VERSION "dbc-export 1 2025.20.8"

NS_ :

BS_:

BU_: ADSP APSB BB BMS CMP CP DAS DI DIF DIR DPB EPASTP EPASTS GTW ICR IDB OCS1P PM PMF PMR PTC RCM RCU TCU UI UIS VCLEFT VCSEC

BO_ 1360 ADSP_alertLog: 8 ADSP
 SG_ ADSP_alertID M : 0|7@1+ (1,0) [0|127] "" Vector__XXX
 SG_ ADSP_alertState : 15|1@1+ (1,0) [0|1] "" Vector__XXX
 SG_ ADSP_a035_a2baFaultNode m35 : 16|4@1+ (1,0) [0|15] "" Vector__XXX
 SG_ ADSP_a035_timeout m35 : 20|1@1+ (1,0) [0|1] "" Vector__XXX
 SG_ ADSP_a035_a2baIntrType m35 : 24|8@1+ (1,0) [0|255] "" Vector__XXX
 SG_ ADSP_a035_a2baFaultType m35 : 32|6@1+ (1,0) [0|63] "" Vector__XXX
 SG_ ADSP_a036_a2bbFaultNode m36 : 16|4@1+ (1,0) [0|15] "" Vector__XXX
 SG_ ADSP_a036_timeout m36 : 20|1@1+ (1,0) [0|1] "" Vector__XXX
 SG_ ADSP_a036_a2bbIntrType m36 : 24|8@1+ (1,0) [0|255] "" Vector__XXX
 SG_ ADSP_a036_a2bbFaultType m36 : 32|6@1+ (1,0) [0|63] "" Vector__XXX
 SG_ ADSP_a050_open_load m50 : 16|1@1+ (1,0) [0|1] "" Vector__XXX
 SG_ ADSP_a050_short_vcc m50 : 17|1@1+ (1,0) [0|1] "" Vector__XXX
 SG_ ADSP_a050_short_gnd m50 : 18|1@1+ (1,0) [0|1] "" Vector__XXX
 SG_ ADSP_a050_short_load m50 : 19|1@1+ (1,0) [0|1] "" Vector__XXX
 SG_ ADSP_a050_diag_failed_to_start m50 : 20|1@1+ (1,0) [0|1] "" Vector__XXX
 SG_ ADSP_a050_diag_failed m50 : 21|1@1+ (1,0) [0|1] "" Vector__XXX
 SG_ ADSP_a053_audioSystemUnavailable m53 : 16|3@1+ (1,0) [0|7] "" Vector__XXX
 SG_ ADSP_a066_open_load m66 : 16|1@1+ (1,0) [0|1] "" Vector__XXX
 SG_ ADSP_a066_short_vcc m66 : 17|1@1+ (1,0) [0|1] "" Vector__XXX
 SG_ ADSP_a066_short_gnd m66 : 18|1@1+ (1,0) [0|1] "" Vector__XXX
 SG_ ADSP_a066_short_load m66 : 19|1@1+ (1,0) [0|1] "" Vector__XXX
 SG_ ADSP_a066_diag_failed_to_start m66 : 20|1@1+ (1,0) [0|1] "" Vector__XXX
 SG_ ADSP_a066_diag_failed m66 : 21|1@1+ (1,0) [0|1] "" Vector__XXX
 SG_ ADSP_a067_baseamp0Fault m67 : 16|3@1+ (1,0) [0|7] "" Vector__XXX
 SG_ ADSP_a068_baseamp1Fault m68 : 16|3@1+ (1,0) [0|7] "" Vector__XXX
 SG_ ADSP_a069_baseamp2Fault m69 : 16|3@1+ (1,0) [0|7] "" Vector__XXX
 SG_ ADSP_a070_baseamp3Fault m70 : 16|3@1+ (1,0) [0|7] "" Vector__XXX
 SG_ ADSP_a071_versionMismatch m71 : 16|1@1+ (1,0) [0|1] "" Vector__XXX

BO_ 1361 ADSP_alertMatrix1: 8 ADSP
 SG_ ADSP_w001_flashInit : 0|1@1+ (1,0) [0|1] "" Vector__XXX
 SG_ ADSP_w002_exception : 1|1@1+ (1,0) [0|1] "" Vector__XXX
 SG_ ADSP_w003_assert : 2|1@1+ (1,0) [0|1] "" Vector__XXX
 SG_ ADSP_w004_malloc : 3|1@1+ (1,0) [0|1] "" Vector__XXX
 SG_ ADSP_w005_stackOverflow : 4|1@1+ (1,0) [0|1] "" Vector__XXX
 SG_ ADSP_w006_eavbSeqno : 5|1@1+ (1,0) [0|1] "" Vector__XXX
 SG_ ADSP_w007_ethLinkErr : 6|1@1+ (1,0) [0|1] "" Vector__XXX
 SG_ ADSP_w008_internalTempHigh : 7|1@1+ (1,0) [0|1] "" Vector__XXX
 SG_ ADSP_w010_12vAudioFiltLow : 9|1@1+ (1,0) [0|1] "" Vector__XXX
 SG_ ADSP_w011_armHighCpuUsage : 10|1@1+ (1,0) [0|1] "" Vector__XXX
 SG_ ADSP_w012_sharc0HighCpuUsage : 11|1@1+ (1,0) [0|1] "" Vector__XXX
 SG_ ADSP_w013_sharc1HighCpuUsage : 12|1@1+ (1,0) [0|1] "" Vector__XXX
 SG_ ADSP_w014_eavbOverrun : 13|1@1+ (1,0) [0|1] "" Vector__XXX
 SG_ ADSP_w015_eavbUnderrun : 14|1@1+ (1,0) [0|1] "" Vector__XXX
 SG_ ADSP_w016_usbRxOverrun : 15|1@1+ (1,0) [0|1] "" Vector__XXX
 SG_ ADSP_w017_usbRxUnderrun : 16|1@1+ (1,0) [0|1] "" Vector__XXX
 SG_ ADSP_w018_usbTxOverrun : 17|1@1+ (1,0) [0|1] "" Vector__XXX
 SG_ ADSP_w019_usbTxUnderrun : 18|1@1+ (1,0) [0|1] "" Vector__XXX
 SG_ ADSP_w020_usbTxFailed : 19|1@1+ (1,0) [0|1] "" Vector__XXX
 SG_ ADSP_w021_usbTxAborted : 20|1@1+ (1,0) [0|1] "" Vector__XXX
 SG_ ADSP_w022_emacErr : 21|1@1+ (1,0) [0|1] "" Vector__XXX
 SG_ ADSP_w023_ethEtharpErr : 22|1@1+ (1,0) [0|1] "" Vector__XXX
 SG_ ADSP_w024_ethIpfragErr : 23|1@1+ (1,0) [0|1] "" Vector__XXX
 SG_ ADSP_w025_ethIpErr : 24|1@1+ (1,0) [0|1] "" Vector__XXX
 SG_ ADSP_w026_ethIcmpErr : 25|1@1+ (1,0) [0|1] "" Vector__XXX
 SG_ ADSP_w027_ethUdpErr : 26|1@1+ (1,0) [0|1] "" Vector__XXX
 SG_ ADSP_w028_ethTcpErr : 27|1@1+ (1,0) [0|1] "" Vector__XXX
 SG_ ADSP_w029_baseamp0SmFault : 28|1@1+ (1,0) [0|1] "" Vector__XXX
 SG_ ADSP_w030_ethSysErr : 29|1@1+ (1,0) [0|1] "" Vector__XXX
 SG_ ADSP_w031_baseamp1SmFault : 30|1@1+ (1,0) [0|1] "" Vector__XXX
 SG_ ADSP_w032_baseamp2SmFault : 31|1@1+ (1,0) [0|1] "" Vector__XXX
 SG_ ADSP_w033_a2baDiscoveryFailed : 32|1@1+ (1,0) [0|1] "" Vector__XXX
 SG_ ADSP_w034_a2bbDiscoveryFailed : 33|1@1+ (1,0) [0|1] "" Vector__XXX
 SG_ ADSP_w035_a2baFault : 34|1@1+ (1,0) [0|1] "" Vector__XXX
 SG_ ADSP_w036_a2bbFault : 35|1@1+ (1,0) [0|1] "" Vector__XXX
 SG_ ADSP_w037_a2baIdleFailed : 36|1@1+ (1,0) [0|1] "" Vector__XXX
 SG_ ADSP_w038_a2bbIdleFailed : 37|1@1+ (1,0) [0|1] "" Vector__XXX
 SG_ ADSP_w039_ancPing : 38|1@1+ (1,0) [0|1] "" Vector__XXX
 SG_ ADSP_w040_socSciHeartbeat : 39|1@1+ (1,0) [0|1] "" Vector__XXX
 SG_ ADSP_w041_twiWriteError : 40|1@1+ (1,0) [0|1] "" Vector__XXX
 SG_ ADSP_w042_twiReadError : 41|1@1+ (1,0) [0|1] "" Vector__XXX
 SG_ ADSP_w043_aweControlError : 42|1@1+ (1,0) [0|1] "" Vector__XXX
 SG_ ADSP_w044_canethChecksum : 43|1@1+ (1,0) [0|1] "" Vector__XXX
 SG_ ADSP_w045_ancEnableFail : 44|1@1+ (1,0) [0|1] "" Vector__XXX
 SG_ ADSP_w046_sharc0AweFrameOverload : 45|1@1+ (1,0) [0|1] "" Vector__XXX
 SG_ ADSP_w047_sharc1AweFrameOverload : 46|1@1+ (1,0) [0|1] "" Vector__XXX
 SG_ ADSP_w048_eCallSelfTestFailed : 47|1@1+ (1,0) [0|1] "" Vector__XXX
 SG_ ADSP_w049_sae : 48|1@1+ (1,0) [0|1] "" Vector__XXX
 SG_ ADSP_w050_extSpkFault : 49|1@1+ (1,0) [0|1] "" Vector__XXX
 SG_ ADSP_w051_extspkFailure : 50|1@1+ (1,0) [0|1] "" Vector__XXX
 SG_ ADSP_w052_criticalReset : 51|1@1+ (1,0) [0|1] "" Vector__XXX
 SG_ ADSP_w053_audioSystemUnavailable : 52|1@1+ (1,0) [0|1] "" Vector__XXX
 SG_ ADSP_w054_canethRxError : 53|1@1+ (1,0) [0|1] "" Vector__XXX
 SG_ ADSP_w055_hfpMathExcept1NAN : 54|1@1+ (1,0) [0|1] "" Vector__XXX
 SG_ ADSP_w056_hfpMathExcept1INF : 55|1@1+ (1,0) [0|1] "" Vector__XXX
 SG_ ADSP_w057_hfpMathExcept2NAN : 56|1@1+ (1,0) [0|1] "" Vector__XXX
 SG_ ADSP_w058_hfpMathExcept2INF : 57|1@1+ (1,0) [0|1] "" Vector__XXX
 SG_ ADSP_w059_nvmmError : 58|1@1+ (1,0) [0|1] "" Vector__XXX
 SG_ ADSP_w060_baseamp3SmFault : 59|1@1+ (1,0) [0|1] "" Vector__XXX
 SG_ ADSP_w061_tcuGpioServiceError : 60|1@1+ (1,0) [0|1] "" Vector__XXX

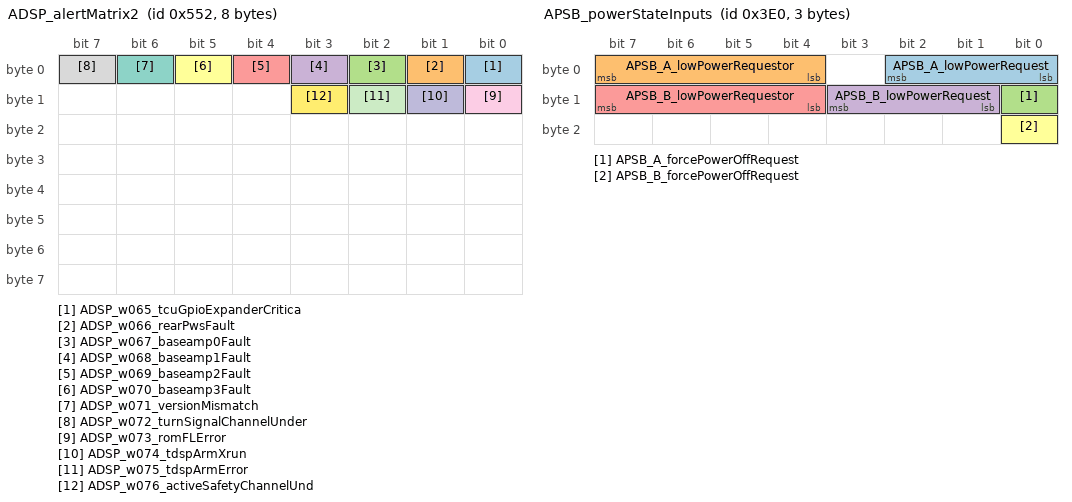
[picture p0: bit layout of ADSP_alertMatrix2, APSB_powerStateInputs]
BO_ 1362 ADSP_alertMatrix2: 8 ADSP
 SG_ ADSP_w065_tcuGpioExpanderCritica : 0|1@1+ (1,0) [0|1] "" Vector__XXX
 SG_ ADSP_w066_rearPwsFault : 1|1@1+ (1,0) [0|1] "" Vector__XXX
 SG_ ADSP_w067_baseamp0Fault : 2|1@1+ (1,0) [0|1] "" Vector__XXX
 SG_ ADSP_w068_baseamp1Fault : 3|1@1+ (1,0) [0|1] "" Vector__XXX
 SG_ ADSP_w069_baseamp2Fault : 4|1@1+ (1,0) [0|1] "" Vector__XXX
 SG_ ADSP_w070_baseamp3Fault : 5|1@1+ (1,0) [0|1] "" Vector__XXX
 SG_ ADSP_w071_versionMismatch : 6|1@1+ (1,0) [0|1] "" Vector__XXX
 SG_ ADSP_w072_turnSignalChannelUnder : 7|1@1+ (1,0) [0|1] "" Vector__XXX
 SG_ ADSP_w073_romFLError : 8|1@1+ (1,0) [0|1] "" Vector__XXX
 SG_ ADSP_w074_tdspArmXrun : 9|1@1+ (1,0) [0|1] "" Vector__XXX
 SG_ ADSP_w075_tdspArmError : 10|1@1+ (1,0) [0|1] "" Vector__XXX
 SG_ ADSP_w076_activeSafetyChannelUnd : 11|1@1+ (1,0) [0|1] "" Vector__XXX

BO_ 992 APSB_powerStateInputs: 3 APSB
 SG_ APSB_A_lowPowerRequest : 0|3@1+ (1,0) [0|7] "" Vector__XXX
 SG_ APSB_A_lowPowerRequestor : 4|4@1+ (1,0) [0|15] "" Vector__XXX
 SG_ APSB_A_forcePowerOffRequest : 8|1@1+ (1,0) [0|1] "" Vector__XXX
 SG_ APSB_B_lowPowerRequest : 9|3@1+ (1,0) [0|7] "" Vector__XXX
 SG_ APSB_B_lowPowerRequestor : 12|4@1+ (1,0) [0|15] "" Vector__XXX
 SG_ APSB_B_forcePowerOffRequest : 16|1@1+ (1,0) [0|1] "" Vector__XXX

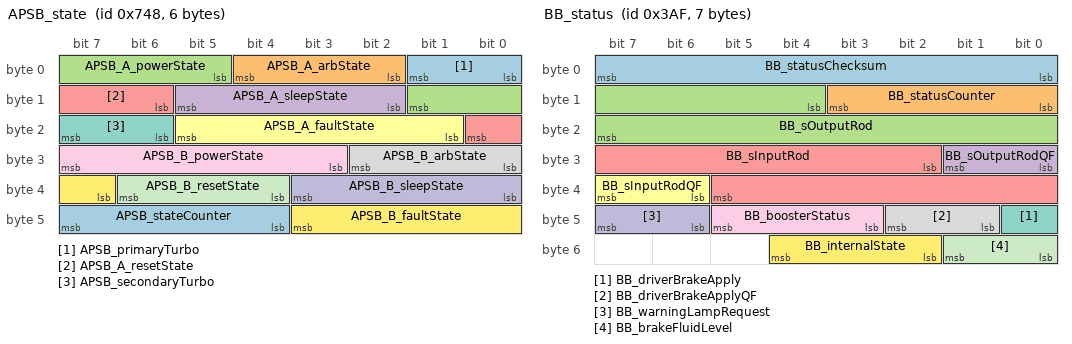
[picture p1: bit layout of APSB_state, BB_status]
BO_ 1864 APSB_state: 6 APSB
 SG_ APSB_primaryTurbo : 0|2@1+ (1,0) [0|3] "" Vector__XXX
 SG_ APSB_A_arbState : 2|3@1+ (1,0) [0|7] "" Vector__XXX
 SG_ APSB_A_powerState : 5|5@1+ (1,0) [0|31] "" Vector__XXX
 SG_ APSB_A_sleepState : 10|4@1+ (1,0) [0|15] "" Vector__XXX
 SG_ APSB_A_resetState : 14|3@1+ (1,0) [0|7] "" Vector__XXX
 SG_ APSB_A_faultState : 17|5@1+ (1,0) [0|31] "" Vector__XXX
 SG_ APSB_secondaryTurbo : 22|2@1+ (1,0) [0|3] "" Vector__XXX
 SG_ APSB_B_arbState : 24|3@1+ (1,0) [0|7] "" Vector__XXX
 SG_ APSB_B_powerState : 27|5@1+ (1,0) [0|31] "" Vector__XXX
 SG_ APSB_B_sleepState : 32|4@1+ (1,0) [0|15] "" Vector__XXX
 SG_ APSB_B_resetState : 36|3@1+ (1,0) [0|7] "" Vector__XXX
 SG_ APSB_B_faultState : 39|5@1+ (1,0) [0|31] "" Vector__XXX
 SG_ APSB_stateCounter : 44|4@1+ (1,0) [0|15] "" Vector__XXX

BO_ 971 APSB_status: 8 APSB
 SG_ APSB_appStatusMonitorState : 0|3@1+ (1,0) [0|7] "" Vector__XXX
 SG_ APSB_vehBehaviorState : 4|4@1+ (1,0) [0|15] "" Vector__XXX
 SG_ APSB_canMaster : 8|2@1+ (1,0) [0|2] "" Vector__XXX
 SG_ APSB_appGpioState : 10|2@1+ (1,0) [0|3] "" Vector__XXX
 SG_ APSB_eacInternalState : 12|3@1+ (1,0) [0|7] "" Vector__XXX
 SG_ APSB_switchState : 15|1@1+ (1,0) [0|1] "" Vector__XXX
 SG_ APSB_apbStatusMonitorState : 16|3@1+ (1,0) [0|7] "" Vector__XXX
 SG_ APSB_apbGpioState : 20|2@1+ (1,0) [0|3] "" Vector__XXX
 SG_ APSB_statusCounter : 22|4@1+ (1,0) [0|15] "" Vector__XXX
 SG_ APSB_locLimitReason : 26|3@1+ (1,0) [0|7] "" Vector__XXX
 SG_ APSB_appPowerStateRequest : 29|2@1+ (1,0) [0|3] "" Vector__XXX
 SG_ APSB_appPowerStateReason : 31|4@1+ (1,0) [0|15] "" Vector__XXX
 SG_ APSB_apbPowerStateRequest : 36|2@1+ (1,0) [0|3] "" Vector__XXX
 SG_ APSB_apbPowerStateReason : 38|4@1+ (1,0) [0|15] "" Vector__XXX
 SG_ APSB_heaterStateDebug : 43|3@1+ (1,0) [0|6] "" Vector__XXX
 SG_ APSB_autosummonCounter : 46|3@1+ (1,0) [0|7] "" Vector__XXX
 SG_ APSB_autosummonAlert : 49|1@1+ (1,0) [0|1] "" Vector__XXX
 SG_ APSB_gpsAntennaState : 50|2@1+ (1,0) [0|3] "" Vector__XXX
 SG_ APSB_arbState : 52|3@1+ (1,0) [0|7] "" Vector__XXX
 SG_ APSB_socPowerOperatingMode : 55|2@1+ (1,0) [0|3] "" Vector__XXX

BO_ 943 BB_status: 7 BB
 SG_ BB_statusChecksum : 0|8@1+ (1,0) [0|255] "" Vector__XXX
 SG_ BB_statusCounter : 8|4@1+ (1,0) [0|15] "" Vector__XXX
 SG_ BB_sOutputRod : 12|12@1+ (0.015625,-5) [-5|47] "mm" Vector__XXX
 SG_ BB_sOutputRodQF : 24|2@1+ (1,0) [0|3] "" Vector__XXX
 SG_ BB_sInputRod : 26|12@1+ (0.015625,-5) [-5|47] "mm" Vector__XXX
 SG_ BB_sInputRodQF : 38|2@1+ (1,0) [0|3] "" Vector__XXX
 SG_ BB_driverBrakeApply : 40|1@1+ (1,0) [0|1] "" Vector__XXX
 SG_ BB_driverBrakeApplyQF : 41|2@1+ (1,0) [0|3] "" Vector__XXX
 SG_ BB_boosterStatus : 43|3@1+ (1,0) [0|7] "" Vector__XXX
 SG_ BB_warningLampRequest : 46|2@1+ (1,0) [0|3] "" Vector__XXX
 SG_ BB_brakeFluidLevel : 48|2@1+ (1,0) [0|3] "" Vector__XXX
 SG_ BB_internalState : 50|3@1+ (1,0) [0|7] "" Vector__XXX

BO_ 2029 BMS_debugInfo_10Hz: 8 BMS
 SG_ BMS_10HzDebug_Id M : 0|6@1+ (1,0) [0|63] "" Vector__XXX
 SG_ BMS_activeCoolCellTargetT m33 : 6|9@1+ (0.25,-25) [-25|100] "DegC" Vector__XXX
 SG_ BMS_passiveCoolCellTargetT m33 : 15|9@1+ (0.25,-25) [-25|100] "DegC" Vector__XXX

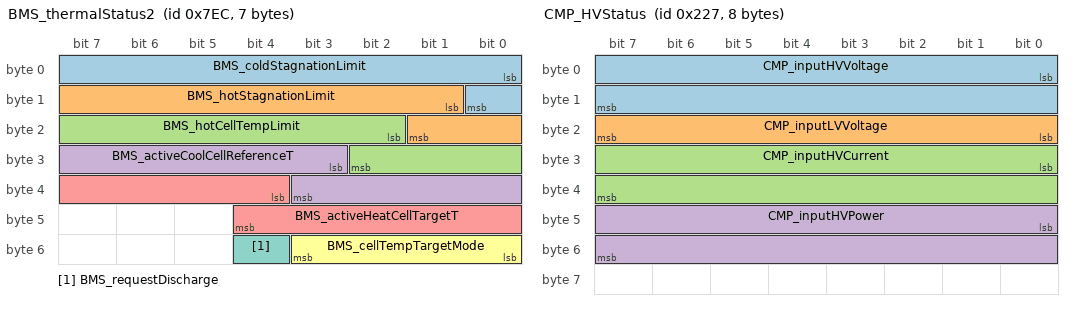
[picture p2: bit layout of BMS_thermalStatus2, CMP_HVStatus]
BO_ 2028 BMS_thermalStatus2: 7 BMS
 SG_ BMS_coldStagnationLimit : 0|9@1+ (0.25,-25) [-25|100] "DegC" Vector__XXX
 SG_ BMS_hotStagnationLimit : 9|9@1+ (0.25,-25) [-25|100] "DegC" Vector__XXX
 SG_ BMS_hotCellTempLimit : 18|9@1+ (0.25,-25) [-25|100] "DegC" Vector__XXX
 SG_ BMS_activeCoolCellReferenceT : 27|9@1+ (0.25,-25) [-25|100] "DegC" Vector__XXX
 SG_ BMS_activeHeatCellTargetT : 36|9@1+ (0.25,-25) [-25|100] "DegC" Vector__XXX
 SG_ BMS_cellTempTargetMode : 48|4@1+ (1,0) [0|15] "" Vector__XXX
 SG_ BMS_requestDischarge : 52|1@1+ (1,0) [0|1] "" Vector__XXX

BO_ 551 CMP_HVStatus: 8 CMP
 SG_ CMP_inputHVVoltage : 0|16@1+ (0.1,0) [0|6553.4] "V" Vector__XXX
 SG_ CMP_inputLVVoltage : 16|8@1+ (0.1,0) [0|25.5] "V" Vector__XXX
 SG_ CMP_inputHVCurrent : 24|16@1+ (0.1,0) [0|6553.4] "A" Vector__XXX
 SG_ CMP_inputHVPower : 40|16@1+ (1,0) [0|65534] "W" Vector__XXX

BO_ 1767 CP_IsoTpPipeToPncd: 8 CP
 SG_ CP_isoTpToPncdData : 0|64@1+ (1,0) [0|1.84467440737e+19] "" Vector__XXX

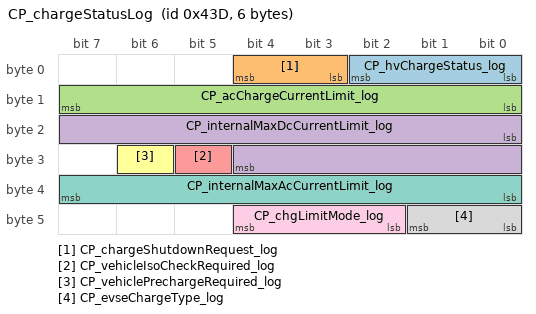
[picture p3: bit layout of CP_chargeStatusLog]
BO_ 1085 CP_chargeStatusLog: 6 CP
 SG_ CP_hvChargeStatus_log : 0|3@1+ (1,0) [0|7] "" Vector__XXX
 SG_ CP_chargeShutdownRequest_log : 3|2@1+ (1,0) [0|3] "" Vector__XXX
 SG_ CP_acChargeCurrentLimit_log : 8|8@1+ (0.5,0) [0|127.5] "A" Vector__XXX
 SG_ CP_internalMaxDcCurrentLimit_log : 16|13@1+ (0.25,0) [0|2047.75] "A" Vector__XXX
 SG_ CP_vehicleIsoCheckRequired_log : 29|1@1+ (1,0) [0|1] "" Vector__XXX
 SG_ CP_vehiclePrechargeRequired_log : 30|1@1+ (1,0) [0|1] "" Vector__XXX
 SG_ CP_internalMaxAcCurrentLimit_log : 32|8@1+ (0.5,0) [0|127.5] "A" Vector__XXX
 SG_ CP_evseChargeType_log : 40|2@1+ (1,0) [0|3] "" Vector__XXX
 SG_ CP_chgLimitMode_log : 42|3@1+ (1,0) [0|7] "" Vector__XXX

BO_ 777 DAS_object: 8 DAS
 SG_ DAS_objectId M : 0|3@1+ (1,0) [0|7] "" Vector__XXX
 SG_ DAS_leadVehType m0 : 3|3@1+ (1,0) [0|7] "" Vector__XXX
 SG_ DAS_leadVehRelevantForControl m0 : 7|1@1+ (1,0) [0|1] "" Vector__XXX
 SG_ DAS_leadVehDx m0 : 8|8@1+ (0.5,0) [0|127] "m" Vector__XXX
 SG_ DAS_leadVehVxRel m0 : 16|4@1+ (4,-30) [-30|26] "m/s" Vector__XXX
 SG_ DAS_leadVehDy m0 : 20|7@1+ (0.35,-22.05) [-22.05|22.4] "m" Vector__XXX
 SG_ DAS_leadVehId m0 : 27|7@1+ (1,0) [0|126] "" Vector__XXX
 SG_ DAS_leadVeh2Type m0 : 34|3@1+ (1,0) [0|7] "" Vector__XXX
 SG_ DAS_leadVeh2RelevantForControl m0 : 38|1@1+ (1,0) [0|1] "" Vector__XXX
 SG_ DAS_leadVeh2Dx m0 : 39|8@1+ (0.5,0) [0|127] "m" Vector__XXX
 SG_ DAS_leadVeh2VxRel m0 : 47|4@1+ (4,-30) [-30|26] "m/s" Vector__XXX
 SG_ DAS_leadVeh2Dy m0 : 51|7@1+ (0.35,-22.05) [-22.05|22.4] "m" Vector__XXX
 SG_ DAS_leadVeh2Id m0 : 58|6@1+ (1,0) [1|63] "" Vector__XXX
 SG_ DAS_leftVehType m1 : 3|3@1+ (1,0) [0|7] "" Vector__XXX
 SG_ DAS_leftVehRelevantForControl m1 : 7|1@1+ (1,0) [0|1] "" Vector__XXX
 SG_ DAS_leftVehDx m1 : 8|8@1+ (0.5,0) [0|127] "m" Vector__XXX
 SG_ DAS_leftVehVxRel m1 : 16|4@1+ (4,-30) [-30|26] "m/s" Vector__XXX
 SG_ DAS_leftVehDy m1 : 20|7@1+ (0.35,-22.05) [-22.05|22.4] "m" Vector__XXX
 SG_ DAS_leftVehId m1 : 27|7@1+ (1,0) [0|126] "" Vector__XXX
 SG_ DAS_leftVeh2Type m1 : 34|3@1+ (1,0) [0|7] "" Vector__XXX
 SG_ DAS_leftVeh2RelevantForControl m1 : 38|1@1+ (1,0) [0|1] "" Vector__XXX
 SG_ DAS_leftVeh2Dx m1 : 39|8@1+ (0.5,0) [0|127] "m" Vector__XXX
 SG_ DAS_leftVeh2VxRel m1 : 47|4@1+ (4,-30) [-30|26] "m/s" Vector__XXX
 SG_ DAS_leftVeh2Dy m1 : 51|7@1+ (0.35,-22.05) [-22.05|22.4] "m" Vector__XXX
 SG_ DAS_leftVeh2Id m1 : 58|6@1+ (1,0) [1|63] "" Vector__XXX
 SG_ DAS_rightVehType m2 : 3|3@1+ (1,0) [0|7] "" Vector__XXX
 SG_ DAS_rightVehRelevantForControl m2 : 7|1@1+ (1,0) [0|1] "" Vector__XXX
 SG_ DAS_rightVehDx m2 : 8|8@1+ (0.5,0) [0|127] "m" Vector__XXX
 SG_ DAS_rightVehVxRel m2 : 16|4@1+ (4,-30) [-30|26] "m/s" Vector__XXX
 SG_ DAS_rightVehDy m2 : 20|7@1+ (0.35,-22.05) [-22.05|22.4] "m" Vector__XXX
 SG_ DAS_rightVehId m2 : 27|7@1+ (1,0) [0|126] "" Vector__XXX
 SG_ DAS_rightVeh2Type m2 : 34|3@1+ (1,0) [0|7] "" Vector__XXX
 SG_ DAS_rightVeh2RelevantForControl m2 : 38|1@1+ (1,0) [0|1] "" Vector__XXX
 SG_ DAS_rightVeh2Dx m2 : 39|8@1+ (0.5,0) [0|127] "m" Vector__XXX
 SG_ DAS_rightVeh2VxRel m2 : 47|4@1+ (4,-30) [-30|26] "m/s" Vector__XXX
 SG_ DAS_rightVeh2Dy m2 : 51|7@1+ (0.35,-22.05) [-22.05|22.4] "m" Vector__XXX
 SG_ DAS_rightVeh2Id m2 : 58|6@1+ (1,0) [1|63] "" Vector__XXX
 SG_ DAS_cutinVehType m3 : 3|3@1+ (1,0) [0|7] "" Vector__XXX
 SG_ DAS_cutinVehRelevantForControl m3 : 7|1@1+ (1,0) [0|1] "" Vector__XXX
 SG_ DAS_cutinVehDx m3 : 8|8@1+ (0.5,0) [0|127] "m" Vector__XXX
 SG_ DAS_cutinVehVxRel m3 : 16|4@1+ (4,-30) [-30|26] "m/s" Vector__XXX
 SG_ DAS_cutinVehDy m3 : 20|7@1+ (0.35,-22.05) [-22.05|22.4] "m" Vector__XXX
 SG_ DAS_cutinVehId m3 : 27|7@1+ (1,0) [0|126] "" Vector__XXX
 SG_ DAS_roadSignColor m4 : 3|3@1+ (1,0) [0|7] "" Vector__XXX
 SG_ DAS_roadSignId m4 : 6|8@1+ (1,0) [0|254] "" Vector__XXX
 SG_ DAS_roadSignStopLineDist m4 : 14|10@1+ (0.2,-20) [-20|184.4] "m" Vector__XXX
 SG_ DAS_roadSignControlActive m4 : 24|1@1+ (1,0) [0|1] "" Vector__XXX
 SG_ DAS_roadSignSource m4 : 25|2@1+ (1,0) [0|3] "" Vector__XXX
 SG_ DAS_roadSignArrow m4 : 27|3@1+ (1,0) [0|7] "" Vector__XXX
 SG_ DAS_roadSignOrientation m4 : 30|2@1+ (1,0) [0|3] "" Vector__XXX

BO_ 1548 DAS_telemetryRadar: 8 DAS
 SG_ DAS_TR_ObjIndex M : 0|5@1+ (1,0) [0|31] "" Vector__XXX
 SG_ DAS_TR_Counter : 54|2@1+ (1,0) [0|3] "" Vector__XXX
 SG_ DAS_TR_Obj00_Class m0 : 5|3@1+ (1,0) [0|7] "" Vector__XXX
 SG_ DAS_TR_Obj00_Dx m0 : 8|10@1+ (0.15625,0) [0|159.84375] "m" Vector__XXX
 SG_ DAS_TR_Obj00_Dy m0 : 18|6@1+ (0.5,-15.5) [-15.5|16] "m" Vector__XXX
 SG_ DAS_TR_Obj00_Vx m0 : 24|8@1+ (0.5,-63.5) [-63.5|64] "m/s" Vector__XXX
 SG_ DAS_TR_Obj00_RCS m0 : 32|8@1+ (0.25,-14) [-14|49.75] "dB" Vector__XXX
 SG_ DAS_TR_Obj00_Length m0 : 40|6@1+ (0.125,0) [0|7.875] "m" Vector__XXX
 SG_ DAS_TR_Obj00_MovingState m0 : 46|2@1+ (1,0) [0|3] "" Vector__XXX
 SG_ DAS_TR_Obj00_Dz m0 : 48|6@1+ (0.25,-5) [-5|10.75] "m" Vector__XXX
 SG_ DAS_TR_Obj00_Exist m0 : 56|5@1+ (3.125,0) [0|96.875] "%" Vector__XXX

BO_ 854 DIF_alertMatrix1: 8 DIF
 SG_ DIF_a001_hwPhaseAgateDrive : 0|1@1+ (1,0) [0|1] "" Vector__XXX
 SG_ DIF_a002_hwPhaseBgateDrive : 1|1@1+ (1,0) [0|1] "" Vector__XXX
 SG_ DIF_a003_hwPhaseCgateDrive : 2|1@1+ (1,0) [0|1] "" Vector__XXX
 SG_ DIF_a004_hwPhaseApeak : 3|1@1+ (1,0) [0|1] "" Vector__XXX
 SG_ DIF_a005_hwPhaseBpeak : 4|1@1+ (1,0) [0|1] "" Vector__XXX
 SG_ DIF_a006_hwPhaseCpeak : 5|1@1+ (1,0) [0|1] "" Vector__XXX
 SG_ DIF_a007_statorAnomalyDetected : 6|1@1+ (1,0) [0|1] "" Vector__XXX
 SG_ DIF_a008_hwEncoderA : 7|1@1+ (1,0) [0|1] "" Vector__XXX
 SG_ DIF_a009_hwEncoderB : 8|1@1+ (1,0) [0|1] "" Vector__XXX
 SG_ DIF_a010_unintendedReset : 9|1@1+ (1,0) [0|1] "" Vector__XXX
 SG_ DIF_a011_swPowerStageNotReady : 10|1@1+ (1,0) [0|1] "" Vector__XXX
 SG_ DIF_a012_hvilNotClosed : 11|1@1+ (1,0) [0|1] "" Vector__XXX
 SG_ DIF_a013_eccError : 12|1@1+ (1,0) [0|1] "" Vector__XXX
 SG_ DIF_a014_activeDamping : 13|1@1+ (1,0) [0|1] "" Vector__XXX
 SG_ DIF_a015_mechSafeStateAnomaly : 14|1@1+ (1,0) [0|1] "" Vector__XXX
 SG_ DIF_a016_safeStateApplied : 15|1@1+ (1,0) [0|1] "" Vector__XXX
 SG_ DIF_a017_hwPedalMonitor : 16|1@1+ (1,0) [0|1] "" Vector__XXX
 SG_ DIF_a018_hwLVSupplyUV : 17|1@1+ (1,0) [0|1] "" Vector__XXX
 SG_ DIF_a020_hwMotorEncoder : 19|1@1+ (1,0) [0|1] "" Vector__XXX
 SG_ DIF_a021_hwBusOV : 20|1@1+ (1,0) [0|1] "" Vector__XXX
 SG_ DIF_a022_hw5vSupplyUV : 21|1@1+ (1,0) [0|1] "" Vector__XXX
 SG_ DIF_a024_selfTest : 23|1@1+ (1,0) [0|1] "" Vector__XXX
 SG_ DIF_a025_phaseApeak : 24|1@1+ (1,0) [0|1] "" Vector__XXX
 SG_ DIF_a026_phaseBpeak : 25|1@1+ (1,0) [0|1] "" Vector__XXX
 SG_ DIF_a027_phaseCpeak : 26|1@1+ (1,0) [0|1] "" Vector__XXX
 SG_ DIF_a028_phaseArms : 27|1@1+ (1,0) [0|1] "" Vector__XXX
 SG_ DIF_a029_phaseBrms : 28|1@1+ (1,0) [0|1] "" Vector__XXX
 SG_ DIF_a030_phaseCrms : 29|1@1+ (1,0) [0|1] "" Vector__XXX
 SG_ DIF_a031_phaseAcurrentOffset : 30|1@1+ (1,0) [0|1] "" Vector__XXX
 SG_ DIF_a032_phaseBcurrentOffset : 31|1@1+ (1,0) [0|1] "" Vector__XXX
 SG_ DIF_a033_phaseAcurrentSensor : 32|1@1+ (1,0) [0|1] "" Vector__XXX
 SG_ DIF_a034_phaseBcurrentSensor : 33|1@1+ (1,0) [0|1] "" Vector__XXX
 SG_ DIF_a035_phaseCurrentBalance : 34|1@1+ (1,0) [0|1] "" Vector__XXX
 SG_ DIF_a036_busOV : 35|1@1+ (1,0) [0|1] "" Vector__XXX
 SG_ DIF_a037_busUV : 36|1@1+ (1,0) [0|1] "" Vector__XXX
 SG_ DIF_a038_busVsensor : 37|1@1+ (1,0) [0|1] "" Vector__XXX
 SG_ DIF_a039_exceptionUndefinedInstr : 38|1@1+ (1,0) [0|1] "" Vector__XXX
 SG_ DIF_a040_difMIA : 39|1@1+ (1,0) [0|1] "" Vector__XXX
 SG_ DIF_a041_sdcMIA : 40|1@1+ (1,0) [0|1] "" Vector__XXX
 SG_ DIF_a042_inletSensor : 41|1@1+ (1,0) [0|1] "" Vector__XXX
 SG_ DIF_a043_outletOT : 42|1@1+ (1,0) [0|1] "" Vector__XXX
 SG_ DIF_a044_outletUT : 43|1@1+ (1,0) [0|1] "" Vector__XXX
 SG_ DIF_a045_outletSensor : 44|1@1+ (1,0) [0|1] "" Vector__XXX
 SG_ DIF_a046_statorOT : 45|1@1+ (1,0) [0|1] "" Vector__XXX
 SG_ DIF_a047_statorSensor1 : 46|1@1+ (1,0) [0|1] "" Vector__XXX
 SG_ DIF_a048_statorSensor2 : 47|1@1+ (1,0) [0|1] "" Vector__XXX
 SG_ DIF_a049_statorSensorDiff : 48|1@1+ (1,0) [0|1] "" Vector__XXX
 SG_ DIF_a050_noStatorSensor : 49|1@1+ (1,0) [0|1] "" Vector__XXX
 SG_ DIF_a052_dirMIA : 51|1@1+ (1,0) [0|1] "" Vector__XXX
 SG_ DIF_a053_unexpectedLatchState : 52|1@1+ (1,0) [0|1] "" Vector__XXX
 SG_ DIF_a054_driveInverterOT : 53|1@1+ (1,0) [0|1] "" Vector__XXX
 SG_ DIF_a055_trqCrossCheck : 54|1@1+ (1,0) [0|1] "" Vector__XXX
 SG_ DIF_a056_ambientOT : 55|1@1+ (1,0) [0|1] "" Vector__XXX
 SG_ DIF_a057_ambientUT : 56|1@1+ (1,0) [0|1] "" Vector__XXX
 SG_ DIF_a058_ambientSensor : 57|1@1+ (1,0) [0|1] "" Vector__XXX
 SG_ DIF_a059_heatsinkOT : 58|1@1+ (1,0) [0|1] "" Vector__XXX
 SG_ DIF_a060_heatsinkUT : 59|1@1+ (1,0) [0|1] "" Vector__XXX
 SG_ DIF_a061_heatsinkSensor : 60|1@1+ (1,0) [0|1] "" Vector__XXX
 SG_ DIF_a062_systemLimpMode : 61|1@1+ (1,0) [0|1] "" Vector__XXX
 SG_ DIF_a063_bbMIA : 62|1@1+ (1,0) [0|1] "" Vector__XXX
 SG_ DIF_a064_torqueIntervention : 63|1@1+ (1,0) [0|1] "" Vector__XXX

BO_ 855 DIF_alertMatrix2: 8 DIF
 SG_ DIF_a065_canHardwareBusB : 0|1@1+ (1,0) [0|1] "" Vector__XXX
 SG_ DIF_a066_canDataBusB : 1|1@1+ (1,0) [0|1] "" Vector__XXX
 SG_ DIF_a067_canOverrunBusB : 2|1@1+ (1,0) [0|1] "" Vector__XXX
 SG_ DIF_a069_rotorTempLimit : 4|1@1+ (1,0) [0|1] "" Vector__XXX
 SG_ DIF_a070_udsTransactionInitiated : 5|1@1+ (1,0) [0|1] "" Vector__XXX
 SG_ DIF_a071_busDisconnected : 6|1@1+ (1,0) [0|1] "" Vector__XXX
 SG_ DIF_a072_gateDriveFaultCounter : 7|1@1+ (1,0) [0|1] "" Vector__XXX
 SG_ DIF_a073_motorSpeed : 8|1@1+ (1,0) [0|1] "" Vector__XXX
 SG_ DIF_a074_motorEncoder : 9|1@1+ (1,0) [0|1] "" Vector__XXX
 SG_ DIF_a075_motorSpeedMismatch : 10|1@1+ (1,0) [0|1] "" Vector__XXX
 SG_ DIF_a076_lvSupplyOV : 11|1@1+ (1,0) [0|1] "" Vector__XXX
 SG_ DIF_a077_lvSupplyUV : 12|1@1+ (1,0) [0|1] "" Vector__XXX
 SG_ DIF_a078_adcRefLow : 13|1@1+ (1,0) [0|1] "" Vector__XXX
 SG_ DIF_a079_adcRefHigh : 14|1@1+ (1,0) [0|1] "" Vector__XXX
 SG_ DIF_a081_P0BFF_DIF_EM_CurrentHig : 16|1@1+ (1,0) [0|1] "" Vector__XXX
 SG_ DIF_a082_P7837_DIF_ECU_DemoTimer : 17|1@1+ (1,0) [0|1] "" Vector__XXX
 SG_ DIF_a083_PABCD_DIF_ECU_DemoWindo : 18|1@1+ (1,0) [0|1] "" Vector__XXX
 SG_ DIF_a084_eccTestData0 : 19|1@1+ (1,0) [0|1] "" Vector__XXX
 SG_ DIF_a086_activeDischargeOn : 21|1@1+ (1,0) [0|1] "" Vector__XXX
 SG_ DIF_a087_gtwMIA : 22|1@1+ (1,0) [0|1] "" Vector__XXX
 SG_ DIF_a088_uiMIA : 23|1@1+ (1,0) [0|1] "" Vector__XXX
 SG_ DIF_a090_pmMIA : 25|1@1+ (1,0) [0|1] "" Vector__XXX
 SG_ DIF_a091_espMIA : 26|1@1+ (1,0) [0|1] "" Vector__XXX
 SG_ DIF_a092_bmsMIA : 27|1@1+ (1,0) [0|1] "" Vector__XXX
 SG_ DIF_a093_canHardwareBusA : 28|1@1+ (1,0) [0|1] "" Vector__XXX
 SG_ DIF_a094_canDataBusA : 29|1@1+ (1,0) [0|1] "" Vector__XXX
 SG_ DIF_a095_canOverrunBusA : 30|1@1+ (1,0) [0|1] "" Vector__XXX
 SG_ DIF_a096_memoryError : 31|1@1+ (1,0) [0|1] "" Vector__XXX
 SG_ DIF_a097_eepromError : 32|1@1+ (1,0) [0|1] "" Vector__XXX
 SG_ DIF_a098_intTimeTooLong : 33|1@1+ (1,0) [0|1] "" Vector__XXX
 SG_ DIF_a099_threadOverrun : 34|1@1+ (1,0) [0|1] "" Vector__XXX
 SG_ DIF_a100_assertion : 35|1@1+ (1,0) [0|1] "" Vector__XXX
 SG_ DIF_a101_eccTestData1 : 36|1@1+ (1,0) [0|1] "" Vector__XXX
 SG_ DIF_a102_exceptionPrefetchAbort : 37|1@1+ (1,0) [0|1] "" Vector__XXX
 SG_ DIF_a103_lowFlow : 38|1@1+ (1,0) [0|1] "" Vector__XXX
 SG_ DIF_a107_fpgaError : 42|1@1+ (1,0) [0|1] "" Vector__XXX
 SG_ DIF_a108_stateTrans : 43|1@1+ (1,0) [0|1] "" Vector__XXX
 SG_ DIF_a109_ahbWriteError : 44|1@1+ (1,0) [0|1] "" Vector__XXX
 SG_ DIF_a110_brakeMIA : 45|1@1+ (1,0) [0|1] "" Vector__XXX
 SG_ DIF_a111_badPhaseSensorCalib : 46|1@1+ (1,0) [0|1] "" Vector__XXX
 SG_ DIF_a112_noPhaseCurrent : 47|1@1+ (1,0) [0|1] "" Vector__XXX
 SG_ DIF_a113_noFuncHeatsinkSensor : 48|1@1+ (1,0) [0|1] "" Vector__XXX
 SG_ DIF_a114_exceptionDataAbort : 49|1@1+ (1,0) [0|1] "" Vector__XXX
 SG_ DIF_a115_exceptionDataAbort2 : 50|1@1+ (1,0) [0|1] "" Vector__XXX
 SG_ DIF_a116_highSpeedWearCounter : 51|1@1+ (1,0) [0|1] "" Vector__XXX
 SG_ DIF_a117_diMIA : 52|1@1+ (1,0) [0|1] "" Vector__XXX
 SG_ DIF_a119_hvpMIA : 54|1@1+ (1,0) [0|1] "" Vector__XXX
 SG_ DIF_a120_hvlinkMIA : 55|1@1+ (1,0) [0|1] "" Vector__XXX
 SG_ DIF_a121_motorControlRegulation : 56|1@1+ (1,0) [0|1] "" Vector__XXX
 SG_ DIF_a122_highStackUsage : 57|1@1+ (1,0) [0|1] "" Vector__XXX
 SG_ DIF_a123_lossMotorControl : 58|1@1+ (1,0) [0|1] "" Vector__XXX
 SG_ DIF_a126_limpMode : 61|1@1+ (1,0) [0|1] "" Vector__XXX
 SG_ DIF_a127_gracefulPowerOff : 62|1@1+ (1,0) [0|1] "" Vector__XXX
 SG_ DIF_a128_fpgaVersionMismatch : 63|1@1+ (1,0) [0|1] "" Vector__XXX

BO_ 858 DIF_alertMatrix3: 8 DIF
 SG_ DIF_a133_capacitorOT : 4|1@1+ (1,0) [0|1] "" Vector__XXX
 SG_ DIF_a134_wheelSpeedIrrational : 5|1@1+ (1,0) [0|1] "" Vector__XXX
 SG_ DIF_a136_spiError : 7|1@1+ (1,0) [0|1] "" Vector__XXX
 SG_ DIF_a142_highLashAngle : 13|1@1+ (1,0) [0|1] "" Vector__XXX
 SG_ DIF_a144_configMismatch : 15|1@1+ (1,0) [0|1] "" Vector__XXX
 SG_ DIF_a147_highTorqueWearLimit : 18|1@1+ (1,0) [0|1] "" Vector__XXX
 SG_ DIF_a148_burnInCycleEnded : 19|1@1+ (1,0) [0|1] "" Vector__XXX
 SG_ DIF_a149_oilPumpFailure : 20|1@1+ (1,0) [0|1] "" Vector__XXX
 SG_ DIF_a150_busVD : 21|1@1+ (1,0) [0|1] "" Vector__XXX
 SG_ DIF_a151_shockTorqueLimiter : 22|1@1+ (1,0) [0|1] "" Vector__XXX
 SG_ DIF_a152_linError : 23|1@1+ (1,0) [0|1] "" Vector__XXX
 SG_ DIF_a153_oilPumpDiagnostics : 24|1@1+ (1,0) [0|1] "" Vector__XXX
 SG_ DIF_a154_resolver : 25|1@1+ (1,0) [0|1] "" Vector__XXX
 SG_ DIF_a155_vcfrontMIA : 26|1@1+ (1,0) [0|1] "" Vector__XXX
 SG_ DIF_a156_currentObserver : 27|1@1+ (1,0) [0|1] "" Vector__XXX
 SG_ DIF_a157_rcmMIA : 28|1@1+ (1,0) [0|1] "" Vector__XXX
 SG_ DIF_a158_ibstMIA : 29|1@1+ (1,0) [0|1] "" Vector__XXX
 SG_ DIF_a160_busVoltageAnomaly : 31|1@1+ (1,0) [0|1] "" Vector__XXX
 SG_ DIF_a161_epas3pMIA : 32|1@1+ (1,0) [0|1] "" Vector__XXX
 SG_ DIF_a162_endOfLifetimeBurnIn : 33|1@1+ (1,0) [0|1] "" Vector__XXX
 SG_ DIF_a174_unitMayNotRestart : 45|1@1+ (1,0) [0|1] "" Vector__XXX
 SG_ DIF_a176_safetyICFault : 47|1@1+ (1,0) [0|1] "" Vector__XXX
 SG_ DIF_a177_fluxReferenceCorrected : 48|1@1+ (1,0) [0|1] "" Vector__XXX

BO_ 859 DIF_alertMatrix4: 8 DIF
 SG_ DIF_a202_excessHeatUnavailable : 9|1@1+ (1,0) [0|1] "" Vector__XXX
 SG_ DIF_a225_tmpEstPlausibility : 32|1@1+ (1,0) [0|1] "" Vector__XXX
 SG_ DIF_a231_unintendedReset2 : 38|1@1+ (1,0) [0|1] "" Vector__XXX
 SG_ DIF_a233_diMsgMissed : 40|1@1+ (1,0) [0|1] "" Vector__XXX
 SG_ DIF_a234_pcsMIA : 41|1@1+ (1,0) [0|1] "" Vector__XXX
 SG_ DIF_a236_tasMIA : 43|1@1+ (1,0) [0|1] "" Vector__XXX
 SG_ DIF_a241_systemThermallyLimited : 48|1@1+ (1,0) [0|1] "" Vector__XXX
 SG_ DIF_a242_spinDownLearning : 49|1@1+ (1,0) [0|1] "" Vector__XXX
 SG_ DIF_a243_ecuLogAvailable : 50|1@1+ (1,0) [0|1] "" Vector__XXX
 SG_ DIF_a244_mechSafeStateApplied : 51|1@1+ (1,0) [0|1] "" Vector__XXX
 SG_ DIF_a245_mechSafeStatePreWarn : 52|1@1+ (1,0) [0|1] "" Vector__XXX
 SG_ DIF_a246_recoveryAtSpeedError : 53|1@1+ (1,0) [0|1] "" Vector__XXX
 SG_ DIF_a247_rotorOffsetError : 54|1@1+ (1,0) [0|1] "" Vector__XXX
 SG_ DIF_a249_highStatorTempFromResis : 56|1@1+ (1,0) [0|1] "" Vector__XXX
 SG_ DIF_a250_preregulatorRail : 57|1@1+ (1,0) [0|1] "" Vector__XXX
 SG_ DIF_a251_oilPumpService : 58|1@1+ (1,0) [0|1] "" Vector__XXX
 SG_ DIF_a252_currentCoreFallback : 59|1@1+ (1,0) [0|1] "" Vector__XXX
 SG_ DIF_a253_lvBoostedRail : 60|1@1+ (1,0) [0|1] "" Vector__XXX
 SG_ DIF_a254_activeDischargeRail : 61|1@1+ (1,0) [0|1] "" Vector__XXX
 SG_ DIF_a255_currentGainFallback : 62|1@1+ (1,0) [0|1] "" Vector__XXX

BO_ 935 DIR_alertMatrix1: 8 DIR
 SG_ DIR_a001_hwPhaseAgateDrive : 0|1@1+ (1,0) [0|1] "" Vector__XXX
 SG_ DIR_a002_hwPhaseBgateDrive : 1|1@1+ (1,0) [0|1] "" Vector__XXX
 SG_ DIR_a003_hwPhaseCgateDrive : 2|1@1+ (1,0) [0|1] "" Vector__XXX
 SG_ DIR_a004_hwPhaseApeak : 3|1@1+ (1,0) [0|1] "" Vector__XXX
 SG_ DIR_a005_hwPhaseBpeak : 4|1@1+ (1,0) [0|1] "" Vector__XXX
 SG_ DIR_a006_hwPhaseCpeak : 5|1@1+ (1,0) [0|1] "" Vector__XXX
 SG_ DIR_a007_statorAnomalyDetected : 6|1@1+ (1,0) [0|1] "" Vector__XXX
 SG_ DIR_a008_hwEncoderA : 7|1@1+ (1,0) [0|1] "" Vector__XXX
 SG_ DIR_a009_hwEncoderB : 8|1@1+ (1,0) [0|1] "" Vector__XXX
 SG_ DIR_a010_unintendedReset : 9|1@1+ (1,0) [0|1] "" Vector__XXX
 SG_ DIR_a011_swPowerStageNotReady : 10|1@1+ (1,0) [0|1] "" Vector__XXX
 SG_ DIR_a012_hvilNotClosed : 11|1@1+ (1,0) [0|1] "" Vector__XXX
 SG_ DIR_a013_eccError : 12|1@1+ (1,0) [0|1] "" Vector__XXX
 SG_ DIR_a014_activeDamping : 13|1@1+ (1,0) [0|1] "" Vector__XXX
 SG_ DIR_a015_mechSafeStateAnomaly : 14|1@1+ (1,0) [0|1] "" Vector__XXX
 SG_ DIR_a016_safeStateApplied : 15|1@1+ (1,0) [0|1] "" Vector__XXX
 SG_ DIR_a017_hwPedalMonitor : 16|1@1+ (1,0) [0|1] "" Vector__XXX
 SG_ DIR_a018_hwLVSupplyUV : 17|1@1+ (1,0) [0|1] "" Vector__XXX
 SG_ DIR_a020_hwMotorEncoder : 19|1@1+ (1,0) [0|1] "" Vector__XXX
 SG_ DIR_a021_hwBusOV : 20|1@1+ (1,0) [0|1] "" Vector__XXX
 SG_ DIR_a022_hw5vSupplyUV : 21|1@1+ (1,0) [0|1] "" Vector__XXX
 SG_ DIR_a024_selfTest : 23|1@1+ (1,0) [0|1] "" Vector__XXX
 SG_ DIR_a025_phaseApeak : 24|1@1+ (1,0) [0|1] "" Vector__XXX
 SG_ DIR_a026_phaseBpeak : 25|1@1+ (1,0) [0|1] "" Vector__XXX
 SG_ DIR_a027_phaseCpeak : 26|1@1+ (1,0) [0|1] "" Vector__XXX
 SG_ DIR_a028_phaseArms : 27|1@1+ (1,0) [0|1] "" Vector__XXX
 SG_ DIR_a029_phaseBrms : 28|1@1+ (1,0) [0|1] "" Vector__XXX
 SG_ DIR_a030_phaseCrms : 29|1@1+ (1,0) [0|1] "" Vector__XXX
 SG_ DIR_a031_phaseAcurrentOffset : 30|1@1+ (1,0) [0|1] "" Vector__XXX
 SG_ DIR_a032_phaseBcurrentOffset : 31|1@1+ (1,0) [0|1] "" Vector__XXX
 SG_ DIR_a033_phaseAcurrentSensor : 32|1@1+ (1,0) [0|1] "" Vector__XXX
 SG_ DIR_a034_phaseBcurrentSensor : 33|1@1+ (1,0) [0|1] "" Vector__XXX
 SG_ DIR_a035_phaseCurrentBalance : 34|1@1+ (1,0) [0|1] "" Vector__XXX
 SG_ DIR_a036_busOV : 35|1@1+ (1,0) [0|1] "" Vector__XXX
 SG_ DIR_a037_busUV : 36|1@1+ (1,0) [0|1] "" Vector__XXX
 SG_ DIR_a038_busVsensor : 37|1@1+ (1,0) [0|1] "" Vector__XXX
 SG_ DIR_a039_exceptionUndefinedInstr : 38|1@1+ (1,0) [0|1] "" Vector__XXX
 SG_ DIR_a040_difMIA : 39|1@1+ (1,0) [0|1] "" Vector__XXX
 SG_ DIR_a041_sdcMIA : 40|1@1+ (1,0) [0|1] "" Vector__XXX
 SG_ DIR_a042_inletSensor : 41|1@1+ (1,0) [0|1] "" Vector__XXX
 SG_ DIR_a043_outletOT : 42|1@1+ (1,0) [0|1] "" Vector__XXX
 SG_ DIR_a044_outletUT : 43|1@1+ (1,0) [0|1] "" Vector__XXX
 SG_ DIR_a045_outletSensor : 44|1@1+ (1,0) [0|1] "" Vector__XXX
 SG_ DIR_a046_statorOT : 45|1@1+ (1,0) [0|1] "" Vector__XXX
 SG_ DIR_a047_statorSensor1 : 46|1@1+ (1,0) [0|1] "" Vector__XXX
 SG_ DIR_a048_statorSensor2 : 47|1@1+ (1,0) [0|1] "" Vector__XXX
 SG_ DIR_a049_statorSensorDiff : 48|1@1+ (1,0) [0|1] "" Vector__XXX
 SG_ DIR_a050_noStatorSensor : 49|1@1+ (1,0) [0|1] "" Vector__XXX
 SG_ DIR_a052_dirMIA : 51|1@1+ (1,0) [0|1] "" Vector__XXX
 SG_ DIR_a053_unexpectedLatchState : 52|1@1+ (1,0) [0|1] "" Vector__XXX
 SG_ DIR_a054_driveInverterOT : 53|1@1+ (1,0) [0|1] "" Vector__XXX
 SG_ DIR_a055_trqCrossCheck : 54|1@1+ (1,0) [0|1] "" Vector__XXX
 SG_ DIR_a056_ambientOT : 55|1@1+ (1,0) [0|1] "" Vector__XXX
 SG_ DIR_a057_ambientUT : 56|1@1+ (1,0) [0|1] "" Vector__XXX
 SG_ DIR_a058_ambientSensor : 57|1@1+ (1,0) [0|1] "" Vector__XXX
 SG_ DIR_a059_heatsinkOT : 58|1@1+ (1,0) [0|1] "" Vector__XXX
 SG_ DIR_a060_heatsinkUT : 59|1@1+ (1,0) [0|1] "" Vector__XXX
 SG_ DIR_a061_heatsinkSensor : 60|1@1+ (1,0) [0|1] "" Vector__XXX
 SG_ DIR_a062_systemLimpMode : 61|1@1+ (1,0) [0|1] "" Vector__XXX
 SG_ DIR_a063_bbMIA : 62|1@1+ (1,0) [0|1] "" Vector__XXX
 SG_ DIR_a064_torqueIntervention : 63|1@1+ (1,0) [0|1] "" Vector__XXX

BO_ 949 DIR_alertMatrix2: 8 DIR
 SG_ DIR_a065_canHardwareBusB : 0|1@1+ (1,0) [0|1] "" Vector__XXX
 SG_ DIR_a066_canDataBusB : 1|1@1+ (1,0) [0|1] "" Vector__XXX
 SG_ DIR_a067_canOverrunBusB : 2|1@1+ (1,0) [0|1] "" Vector__XXX
 SG_ DIR_a069_rotorTempLimit : 4|1@1+ (1,0) [0|1] "" Vector__XXX
 SG_ DIR_a070_udsTransactionInitiated : 5|1@1+ (1,0) [0|1] "" Vector__XXX
 SG_ DIR_a071_busDisconnected : 6|1@1+ (1,0) [0|1] "" Vector__XXX
 SG_ DIR_a072_gateDriveFaultCounter : 7|1@1+ (1,0) [0|1] "" Vector__XXX
 SG_ DIR_a073_motorSpeed : 8|1@1+ (1,0) [0|1] "" Vector__XXX
 SG_ DIR_a074_motorEncoder : 9|1@1+ (1,0) [0|1] "" Vector__XXX
 SG_ DIR_a075_motorSpeedMismatch : 10|1@1+ (1,0) [0|1] "" Vector__XXX
 SG_ DIR_a076_lvSupplyOV : 11|1@1+ (1,0) [0|1] "" Vector__XXX
 SG_ DIR_a077_lvSupplyUV : 12|1@1+ (1,0) [0|1] "" Vector__XXX
 SG_ DIR_a078_adcRefLow : 13|1@1+ (1,0) [0|1] "" Vector__XXX
 SG_ DIR_a079_adcRefHigh : 14|1@1+ (1,0) [0|1] "" Vector__XXX
 SG_ DIR_a080_adcInfo : 15|1@1+ (1,0) [0|1] "" Vector__XXX
 SG_ DIR_a081_P0BFF_DIR_EM_CurrentHig : 16|1@1+ (1,0) [0|1] "" Vector__XXX
 SG_ DIR_a082_P0F45_DIR_ECU_DemoTimer : 17|1@1+ (1,0) [0|1] "" Vector__XXX
 SG_ DIR_a083_P98B3_DIR_ECU_DemoWindo : 18|1@1+ (1,0) [0|1] "" Vector__XXX
 SG_ DIR_a084_eccTestData0 : 19|1@1+ (1,0) [0|1] "" Vector__XXX
 SG_ DIR_a086_activeDischargeOn : 21|1@1+ (1,0) [0|1] "" Vector__XXX
 SG_ DIR_a087_gtwMIA : 22|1@1+ (1,0) [0|1] "" Vector__XXX
 SG_ DIR_a088_uiMIA : 23|1@1+ (1,0) [0|1] "" Vector__XXX
 SG_ DIR_a090_pmMIA : 25|1@1+ (1,0) [0|1] "" Vector__XXX
 SG_ DIR_a091_espMIA : 26|1@1+ (1,0) [0|1] "" Vector__XXX
 SG_ DIR_a092_bmsMIA : 27|1@1+ (1,0) [0|1] "" Vector__XXX
 SG_ DIR_a093_canHardwareBusA : 28|1@1+ (1,0) [0|1] "" Vector__XXX
 SG_ DIR_a094_canDataBusA : 29|1@1+ (1,0) [0|1] "" Vector__XXX
 SG_ DIR_a095_canOverrunBusA : 30|1@1+ (1,0) [0|1] "" Vector__XXX
 SG_ DIR_a096_memoryError : 31|1@1+ (1,0) [0|1] "" Vector__XXX
 SG_ DIR_a097_eepromError : 32|1@1+ (1,0) [0|1] "" Vector__XXX
 SG_ DIR_a098_intTimeTooLong : 33|1@1+ (1,0) [0|1] "" Vector__XXX
 SG_ DIR_a099_threadOverrun : 34|1@1+ (1,0) [0|1] "" Vector__XXX
 SG_ DIR_a100_assertion : 35|1@1+ (1,0) [0|1] "" Vector__XXX
 SG_ DIR_a101_eccTestData1 : 36|1@1+ (1,0) [0|1] "" Vector__XXX
 SG_ DIR_a102_exceptionPrefetchAbort : 37|1@1+ (1,0) [0|1] "" Vector__XXX
 SG_ DIR_a103_lowFlow : 38|1@1+ (1,0) [0|1] "" Vector__XXX
 SG_ DIR_a107_fpgaError : 42|1@1+ (1,0) [0|1] "" Vector__XXX
 SG_ DIR_a108_stateTrans : 43|1@1+ (1,0) [0|1] "" Vector__XXX
 SG_ DIR_a109_ahbWriteError : 44|1@1+ (1,0) [0|1] "" Vector__XXX
 SG_ DIR_a110_brakeMIA : 45|1@1+ (1,0) [0|1] "" Vector__XXX
 SG_ DIR_a111_badPhaseSensorCalib : 46|1@1+ (1,0) [0|1] "" Vector__XXX
 SG_ DIR_a112_noPhaseCurrent : 47|1@1+ (1,0) [0|1] "" Vector__XXX
 SG_ DIR_a113_noFuncHeatsinkSensor : 48|1@1+ (1,0) [0|1] "" Vector__XXX
 SG_ DIR_a114_exceptionDataAbort : 49|1@1+ (1,0) [0|1] "" Vector__XXX
 SG_ DIR_a115_exceptionDataAbort2 : 50|1@1+ (1,0) [0|1] "" Vector__XXX
 SG_ DIR_a116_highSpeedWearCounter : 51|1@1+ (1,0) [0|1] "" Vector__XXX
 SG_ DIR_a117_diMIA : 52|1@1+ (1,0) [0|1] "" Vector__XXX
 SG_ DIR_a119_hvpMIA : 54|1@1+ (1,0) [0|1] "" Vector__XXX
 SG_ DIR_a120_hvlinkMIA : 55|1@1+ (1,0) [0|1] "" Vector__XXX
 SG_ DIR_a121_motorControlRegulation : 56|1@1+ (1,0) [0|1] "" Vector__XXX
 SG_ DIR_a122_highStackUsage : 57|1@1+ (1,0) [0|1] "" Vector__XXX
 SG_ DIR_a123_lossMotorControl : 58|1@1+ (1,0) [0|1] "" Vector__XXX
 SG_ DIR_a126_limpMode : 61|1@1+ (1,0) [0|1] "" Vector__XXX
 SG_ DIR_a127_gracefulPowerOff : 62|1@1+ (1,0) [0|1] "" Vector__XXX
 SG_ DIR_a128_fpgaVersionMismatch : 63|1@1+ (1,0) [0|1] "" Vector__XXX

BO_ 965 DIR_alertMatrix3: 8 DIR
 SG_ DIR_a133_capacitorOT : 4|1@1+ (1,0) [0|1] "" Vector__XXX
 SG_ DIR_a134_wheelSpeedIrrational : 5|1@1+ (1,0) [0|1] "" Vector__XXX
 SG_ DIR_a136_spiError : 7|1@1+ (1,0) [0|1] "" Vector__XXX
 SG_ DIR_a142_highLashAngle : 13|1@1+ (1,0) [0|1] "" Vector__XXX
 SG_ DIR_a144_configMismatch : 15|1@1+ (1,0) [0|1] "" Vector__XXX
 SG_ DIR_a147_highTorqueWearLimit : 18|1@1+ (1,0) [0|1] "" Vector__XXX
 SG_ DIR_a148_burnInCycleEnded : 19|1@1+ (1,0) [0|1] "" Vector__XXX
 SG_ DIR_a149_oilPumpFailure : 20|1@1+ (1,0) [0|1] "" Vector__XXX
 SG_ DIR_a150_busVD : 21|1@1+ (1,0) [0|1] "" Vector__XXX
 SG_ DIR_a151_shockTorqueLimiter : 22|1@1+ (1,0) [0|1] "" Vector__XXX
 SG_ DIR_a152_linError : 23|1@1+ (1,0) [0|1] "" Vector__XXX
 SG_ DIR_a153_oilPumpDiagnostics : 24|1@1+ (1,0) [0|1] "" Vector__XXX
 SG_ DIR_a154_resolver : 25|1@1+ (1,0) [0|1] "" Vector__XXX
 SG_ DIR_a155_vcfrontMIA : 26|1@1+ (1,0) [0|1] "" Vector__XXX
 SG_ DIR_a156_currentObserver : 27|1@1+ (1,0) [0|1] "" Vector__XXX
 SG_ DIR_a157_rcmMIA : 28|1@1+ (1,0) [0|1] "" Vector__XXX
 SG_ DIR_a158_ibstMIA : 29|1@1+ (1,0) [0|1] "" Vector__XXX
 SG_ DIR_a160_busVoltageAnomaly : 31|1@1+ (1,0) [0|1] "" Vector__XXX
 SG_ DIR_a161_epas3pMIA : 32|1@1+ (1,0) [0|1] "" Vector__XXX
 SG_ DIR_a162_endOfLifetimeBurnIn : 33|1@1+ (1,0) [0|1] "" Vector__XXX
 SG_ DIR_a174_unitMayNotRestart : 45|1@1+ (1,0) [0|1] "" Vector__XXX
 SG_ DIR_a176_safetyICFault : 47|1@1+ (1,0) [0|1] "" Vector__XXX
 SG_ DIR_a177_fluxReferenceCorrected : 48|1@1+ (1,0) [0|1] "" Vector__XXX
 SG_ DIR_a178_spindownLearningBrakeAl : 49|1@1+ (1,0) [0|1] "" Vector__XXX

BO_ 997 DIR_alertMatrix4: 8 DIR
 SG_ DIR_a202_excessHeatUnavailable : 9|1@1+ (1,0) [0|1] "" Vector__XXX
 SG_ DIR_a225_tmpEstPlausibility : 32|1@1+ (1,0) [0|1] "" Vector__XXX
 SG_ DIR_a231_unintendedReset2 : 38|1@1+ (1,0) [0|1] "" Vector__XXX
 SG_ DIR_a233_diMsgMissed : 40|1@1+ (1,0) [0|1] "" Vector__XXX
 SG_ DIR_a234_pcsMIA : 41|1@1+ (1,0) [0|1] "" Vector__XXX
 SG_ DIR_a236_tasMIA : 43|1@1+ (1,0) [0|1] "" Vector__XXX
 SG_ DIR_a241_systemThermallyLimited : 48|1@1+ (1,0) [0|1] "" Vector__XXX
 SG_ DIR_a242_spinDownLearning : 49|1@1+ (1,0) [0|1] "" Vector__XXX
 SG_ DIR_a243_ecuLogAvailable : 50|1@1+ (1,0) [0|1] "" Vector__XXX
 SG_ DIR_a244_mechSafeStateApplied : 51|1@1+ (1,0) [0|1] "" Vector__XXX
 SG_ DIR_a245_mechSafeStatePreWarn : 52|1@1+ (1,0) [0|1] "" Vector__XXX
 SG_ DIR_a246_recoveryAtSpeedError : 53|1@1+ (1,0) [0|1] "" Vector__XXX
 SG_ DIR_a247_rotorOffsetError : 54|1@1+ (1,0) [0|1] "" Vector__XXX
 SG_ DIR_a248_vehicleSpeedLimited : 55|1@1+ (1,0) [0|1] "" Vector__XXX
 SG_ DIR_a249_highStatorTempFromResis : 56|1@1+ (1,0) [0|1] "" Vector__XXX
 SG_ DIR_a250_preregulatorRail : 57|1@1+ (1,0) [0|1] "" Vector__XXX
 SG_ DIR_a251_oilPumpService : 58|1@1+ (1,0) [0|1] "" Vector__XXX
 SG_ DIR_a252_currentCoreFallback : 59|1@1+ (1,0) [0|1] "" Vector__XXX
 SG_ DIR_a253_lvBoostedRail : 60|1@1+ (1,0) [0|1] "" Vector__XXX
 SG_ DIR_a254_activeDischargeRail : 61|1@1+ (1,0) [0|1] "" Vector__XXX
 SG_ DIR_a255_currentGainFallback : 62|1@1+ (1,0) [0|1] "" Vector__XXX

BO_ 871 DI_alertMatrix1: 8 DI
 SG_ DI_a001_frunkSpeedLimitActive : 0|1@1+ (1,0) [0|1] "" Vector__XXX
 SG_ DI_a002_parkButtonDuringStalkReq : 1|1@1+ (1,0) [0|1] "" Vector__XXX
 SG_ DI_a003_suggestedGearOverride : 2|1@1+ (1,0) [0|1] "" Vector__XXX
 SG_ DI_a004_smartShiftUnavailable : 3|1@1+ (1,0) [0|1] "" Vector__XXX
 SG_ DI_a005_stalkPanicked : 4|1@1+ (1,0) [0|1] "" Vector__XXX
 SG_ DI_a006_shifterUnavailable : 5|1@1+ (1,0) [0|1] "" Vector__XXX
 SG_ DI_a007_secGearSelButtonStuck : 6|1@1+ (1,0) [0|1] "" Vector__XXX
 SG_ DI_a010_unintendedReset : 9|1@1+ (1,0) [0|1] "" Vector__XXX
 SG_ DI_a012_accel5VSupply : 11|1@1+ (1,0) [0|1] "" Vector__XXX
 SG_ DI_a013_eccError : 12|1@1+ (1,0) [0|1] "" Vector__XXX
 SG_ DI_a014_secGearSelActivated : 13|1@1+ (1,0) [0|1] "" Vector__XXX
 SG_ DI_a015_immobilizer : 14|1@1+ (1,0) [0|1] "" Vector__XXX
 SG_ DI_a016_parkRequestByPM : 15|1@1+ (1,0) [0|1] "" Vector__XXX
 SG_ DI_a017_hwPedalMonitor : 16|1@1+ (1,0) [0|1] "" Vector__XXX
 SG_ DI_a018_hwLVSupplyUV : 17|1@1+ (1,0) [0|1] "" Vector__XXX
 SG_ DI_a019_hwAccelPedalPower : 18|1@1+ (1,0) [0|1] "" Vector__XXX
 SG_ DI_a020_systemHvilNotClosed : 19|1@1+ (1,0) [0|1] "" Vector__XXX
 SG_ DI_a021_packOvervoltage : 20|1@1+ (1,0) [0|1] "" Vector__XXX
 SG_ DI_a022_hw5vSupplyUV : 21|1@1+ (1,0) [0|1] "" Vector__XXX
 SG_ DI_a023_carNotParked : 22|1@1+ (1,0) [0|1] "" Vector__XXX
 SG_ DI_a024_holdNForNeutral : 23|1@1+ (1,0) [0|1] "" Vector__XXX
 SG_ DI_a025_regenBackfillUnavailable : 24|1@1+ (1,0) [0|1] "" Vector__XXX
 SG_ DI_a026_parkPressedWithHighAPeda : 25|1@1+ (1,0) [0|1] "" Vector__XXX
 SG_ DI_a031_closureAccelerationLimit : 30|1@1+ (1,0) [0|1] "" Vector__XXX
 SG_ DI_a036_sysStandbyUnitLimitedWai : 35|1@1+ (1,0) [0|1] "" Vector__XXX
 SG_ DI_a038_idleTaskStarving : 37|1@1+ (1,0) [0|1] "" Vector__XXX
 SG_ DI_a039_exceptionUndefinedInstru : 38|1@1+ (1,0) [0|1] "" Vector__XXX
 SG_ DI_a040_difMIA : 39|1@1+ (1,0) [0|1] "" Vector__XXX
 SG_ DI_a041_driverBrakeApplyStuck : 40|1@1+ (1,0) [0|1] "" Vector__XXX
 SG_ DI_a042_pmfMIA : 41|1@1+ (1,0) [0|1] "" Vector__XXX
 SG_ DI_a043_pmrMIA : 42|1@1+ (1,0) [0|1] "" Vector__XXX
 SG_ DI_a048_ecuLogAvailable : 47|1@1+ (1,0) [0|1] "" Vector__XXX
 SG_ DI_a049_P0632_DI_ECU_OdometerNot : 48|1@1+ (1,0) [0|1] "" Vector__XXX
 SG_ DI_a050_P1234_DI_ECU_DemoTimer : 49|1@1+ (1,0) [0|1] "" Vector__XXX
 SG_ DI_a051_batteryOvercurrent : 50|1@1+ (1,0) [0|1] "" Vector__XXX
 SG_ DI_a052_dirMIA : 51|1@1+ (1,0) [0|1] "" Vector__XXX
 SG_ DI_a053_canDataBusC : 52|1@1+ (1,0) [0|1] "" Vector__XXX
 SG_ DI_a054_canOverrunBusC : 53|1@1+ (1,0) [0|1] "" Vector__XXX
 SG_ DI_a055_canHardwareBusC : 54|1@1+ (1,0) [0|1] "" Vector__XXX
 SG_ DI_a056_canDataBusD : 55|1@1+ (1,0) [0|1] "" Vector__XXX
 SG_ DI_a057_canOverrunBusD : 56|1@1+ (1,0) [0|1] "" Vector__XXX
 SG_ DI_a058_canHardwareBusD : 57|1@1+ (1,0) [0|1] "" Vector__XXX
 SG_ DI_a059_canDataBusE : 58|1@1+ (1,0) [0|1] "" Vector__XXX
 SG_ DI_a060_canOverrunBusE : 59|1@1+ (1,0) [0|1] "" Vector__XXX
 SG_ DI_a061_canHardwareBusE : 60|1@1+ (1,0) [0|1] "" Vector__XXX
 SG_ DI_a062_systemLimpMode : 61|1@1+ (1,0) [0|1] "" Vector__XXX
 SG_ DI_a063_systemGracefulPowerOff : 62|1@1+ (1,0) [0|1] "" Vector__XXX
 SG_ DI_a064_pmsrmUnitMiaWithHvDown : 63|1@1+ (1,0) [0|1] "" Vector__XXX

BO_ 872 DI_alertMatrix2: 8 DI
 SG_ DI_a065_canHardwareBusB : 0|1@1+ (1,0) [0|1] "" Vector__XXX
 SG_ DI_a066_canDataBusB : 1|1@1+ (1,0) [0|1] "" Vector__XXX
 SG_ DI_a067_canOverrunBusB : 2|1@1+ (1,0) [0|1] "" Vector__XXX
 SG_ DI_a068_secondaryWheelSpeedIrrat : 3|1@1+ (1,0) [0|1] "" Vector__XXX
 SG_ DI_a069_P1234_DI_ECU_DemoWindow : 4|1@1+ (1,0) [0|1] "" Vector__XXX
 SG_ DI_a070_udsTransactionInitiated : 5|1@1+ (1,0) [0|1] "" Vector__XXX
 SG_ DI_a076_lvSupplyOV : 11|1@1+ (1,0) [0|1] "" Vector__XXX
 SG_ DI_a077_lvSupplyUV : 12|1@1+ (1,0) [0|1] "" Vector__XXX
 SG_ DI_a078_adcRefLow : 13|1@1+ (1,0) [0|1] "" Vector__XXX
 SG_ DI_a079_adcRefHigh : 14|1@1+ (1,0) [0|1] "" Vector__XXX
 SG_ DI_a080_accelSynch : 15|1@1+ (1,0) [0|1] "" Vector__XXX
 SG_ DI_a081_accelTrack1 : 16|1@1+ (1,0) [0|1] "" Vector__XXX
 SG_ DI_a082_accelTrack2 : 17|1@1+ (1,0) [0|1] "" Vector__XXX
 SG_ DI_a083_brakePedalSensor : 18|1@1+ (1,0) [0|1] "" Vector__XXX
 SG_ DI_a084_eccTestData0 : 19|1@1+ (1,0) [0|1] "" Vector__XXX
 SG_ DI_a085_proximityInEnable : 20|1@1+ (1,0) [0|1] "" Vector__XXX
 SG_ DI_a086_dpbMIA : 21|1@1+ (1,0) [0|1] "" Vector__XXX
 SG_ DI_a087_gtwMIA : 22|1@1+ (1,0) [0|1] "" Vector__XXX
 SG_ DI_a088_uiMIA : 23|1@1+ (1,0) [0|1] "" Vector__XXX
 SG_ DI_a089_sccmMIA : 24|1@1+ (1,0) [0|1] "" Vector__XXX
 SG_ DI_a090_pmMIA : 25|1@1+ (1,0) [0|1] "" Vector__XXX
 SG_ DI_a091_espMIA : 26|1@1+ (1,0) [0|1] "" Vector__XXX
 SG_ DI_a092_bmsMIA : 27|1@1+ (1,0) [0|1] "" Vector__XXX
 SG_ DI_a093_canHardwareBusA : 28|1@1+ (1,0) [0|1] "" Vector__XXX
 SG_ DI_a094_canDataBusA : 29|1@1+ (1,0) [0|1] "" Vector__XXX
 SG_ DI_a095_canOverrunBusA : 30|1@1+ (1,0) [0|1] "" Vector__XXX
 SG_ DI_a096_memoryError : 31|1@1+ (1,0) [0|1] "" Vector__XXX
 SG_ DI_a097_eepromError : 32|1@1+ (1,0) [0|1] "" Vector__XXX
 SG_ DI_a098_eepromManagerError : 33|1@1+ (1,0) [0|1] "" Vector__XXX
 SG_ DI_a099_threadOverrun : 34|1@1+ (1,0) [0|1] "" Vector__XXX
 SG_ DI_a100_nvramError : 35|1@1+ (1,0) [0|1] "" Vector__XXX
 SG_ DI_a101_eccTestData1 : 36|1@1+ (1,0) [0|1] "" Vector__XXX
 SG_ DI_a102_exceptionPrefetchAbort : 37|1@1+ (1,0) [0|1] "" Vector__XXX
 SG_ DI_a103_bbMIA : 38|1@1+ (1,0) [0|1] "" Vector__XXX
 SG_ DI_a104_proximityIrrational : 39|1@1+ (1,0) [0|1] "" Vector__XXX
 SG_ DI_a105_cpMIA : 40|1@1+ (1,0) [0|1] "" Vector__XXX
 SG_ DI_a108_appMIA : 43|1@1+ (1,0) [0|1] "" Vector__XXX
 SG_ DI_a109_ahbWriteError : 44|1@1+ (1,0) [0|1] "" Vector__XXX
 SG_ DI_a110_brakeMIA : 45|1@1+ (1,0) [0|1] "" Vector__XXX
 SG_ DI_a112_accelTrack1Incons : 47|1@1+ (1,0) [0|1] "" Vector__XXX
 SG_ DI_a114_exceptionDataAbort : 49|1@1+ (1,0) [0|1] "" Vector__XXX
 SG_ DI_a115_exceptionDataAbort2 : 50|1@1+ (1,0) [0|1] "" Vector__XXX
 SG_ DI_a116_motorRecovered : 51|1@1+ (1,0) [0|1] "" Vector__XXX
 SG_ DI_a117_latentFaultCheckTripped : 52|1@1+ (1,0) [0|1] "" Vector__XXX
 SG_ DI_a118_diImmobilizedForFactoryF : 53|1@1+ (1,0) [0|1] "" Vector__XXX
 SG_ DI_a119_latentFaultCheckFailedOn : 54|1@1+ (1,0) [0|1] "" Vector__XXX
 SG_ DI_a120_regenBlendingUnavailable : 55|1@1+ (1,0) [0|1] "" Vector__XXX
 SG_ DI_a121_qualifiedBrakeEventMitig : 56|1@1+ (1,0) [0|1] "" Vector__XXX
 SG_ DI_a122_highStackUsage : 57|1@1+ (1,0) [0|1] "" Vector__XXX
 SG_ DI_a124_cruiseFault : 59|1@1+ (1,0) [0|1] "" Vector__XXX
 SG_ DI_a125_noBatteryPower : 60|1@1+ (1,0) [0|1] "" Vector__XXX

BO_ 875 DI_alertMatrix3: 8 DI
 SG_ DI_a129_epbNotApplied : 0|1@1+ (1,0) [0|1] "" Vector__XXX
 SG_ DI_a130_aebFault : 1|1@1+ (1,0) [0|1] "" Vector__XXX
 SG_ DI_a131_highSpeedWearLimit : 2|1@1+ (1,0) [0|1] "" Vector__XXX
 SG_ DI_a133_vehicleHoldTimedOut : 4|1@1+ (1,0) [0|1] "" Vector__XXX
 SG_ DI_a134_wheelSpeedIrrational : 5|1@1+ (1,0) [0|1] "" Vector__XXX
 SG_ DI_a135_vehicleHoldFault : 6|1@1+ (1,0) [0|1] "" Vector__XXX
 SG_ DI_a137_noCapableDriveUnits : 8|1@1+ (1,0) [0|1] "" Vector__XXX
 SG_ DI_a138_frontUnitDisabled : 9|1@1+ (1,0) [0|1] "" Vector__XXX
 SG_ DI_a139_rearUnitDisabled : 10|1@1+ (1,0) [0|1] "" Vector__XXX
 SG_ DI_a140_ptcMIA : 11|1@1+ (1,0) [0|1] "" Vector__XXX
 SG_ DI_a141_dasMIA : 12|1@1+ (1,0) [0|1] "" Vector__XXX
 SG_ DI_a142_potholeDetected : 13|1@1+ (1,0) [0|1] "" Vector__XXX
 SG_ DI_a143_mcuLimitActive : 14|1@1+ (1,0) [0|1] "" Vector__XXX
 SG_ DI_a144_configMismatch : 15|1@1+ (1,0) [0|1] "" Vector__XXX
 SG_ DI_a146_pbrkPanicEpbFault : 17|1@1+ (1,0) [0|1] "" Vector__XXX
 SG_ DI_a154_vdcRearSteering : 25|1@1+ (1,0) [0|1] "" Vector__XXX
 SG_ DI_a155_vcfrontMIA : 26|1@1+ (1,0) [0|1] "" Vector__XXX
 SG_ DI_a157_rcmMIA : 28|1@1+ (1,0) [0|1] "" Vector__XXX
 SG_ DI_a158_ibstMIA : 29|1@1+ (1,0) [0|1] "" Vector__XXX
 SG_ DI_a159_cruiseSelfCheck : 30|1@1+ (1,0) [0|1] "" Vector__XXX
 SG_ DI_a160_fastLearnComplete : 31|1@1+ (1,0) [0|1] "" Vector__XXX
 SG_ DI_a161_epas3pMIA : 32|1@1+ (1,0) [0|1] "" Vector__XXX
 SG_ DI_a162_shiftDenied : 33|1@1+ (1,0) [0|1] "" Vector__XXX
 SG_ DI_a163_shiftMotorSpeed : 34|1@1+ (1,0) [0|1] "" Vector__XXX
 SG_ DI_a164_brakeOverride : 35|1@1+ (1,0) [0|1] "" Vector__XXX
 SG_ DI_a165_cruiseCancelled : 36|1@1+ (1,0) [0|1] "" Vector__XXX
 SG_ DI_a166_driverLeft : 37|1@1+ (1,0) [0|1] "" Vector__XXX
 SG_ DI_a167_keyNotAuthenticated : 38|1@1+ (1,0) [0|1] "" Vector__XXX
 SG_ DI_a168_proximityDriveDenial : 39|1@1+ (1,0) [0|1] "" Vector__XXX
 SG_ DI_a169_regenOffOverride : 40|1@1+ (1,0) [0|1] "" Vector__XXX
 SG_ DI_a170_tireConfigUpdated : 41|1@1+ (1,0) [0|1] "" Vector__XXX
 SG_ DI_a171_driveRailNotRequested : 42|1@1+ (1,0) [0|1] "" Vector__XXX
 SG_ DI_a172_accelPressedInNP : 43|1@1+ (1,0) [0|1] "" Vector__XXX
 SG_ DI_a173_bothPedalsPressed : 44|1@1+ (1,0) [0|1] "" Vector__XXX
 SG_ DI_a174_notOkToStartDrive : 45|1@1+ (1,0) [0|1] "" Vector__XXX
 SG_ DI_a175_crsNotAvailable : 46|1@1+ (1,0) [0|1] "" Vector__XXX
 SG_ DI_a176_EBRreleased : 47|1@1+ (1,0) [0|1] "" Vector__XXX
 SG_ DI_a177_tireFitmentChanged : 48|1@1+ (1,0) [0|1] "" Vector__XXX
 SG_ DI_a178_steeringAngleOffsetFault : 49|1@1+ (1,0) [0|1] "" Vector__XXX
 SG_ DI_a179_steeringAngleOffsetWarni : 50|1@1+ (1,0) [0|1] "" Vector__XXX
 SG_ DI_a180_crsSeatbeltUnbuckled : 51|1@1+ (1,0) [0|1] "" Vector__XXX
 SG_ DI_a181_rearMotorMode : 52|1@1+ (1,0) [0|1] "" Vector__XXX
 SG_ DI_a182_frontMotorMode : 53|1@1+ (1,0) [0|1] "" Vector__XXX
 SG_ DI_a183_holdReleaseRqrd : 54|1@1+ (1,0) [0|1] "" Vector__XXX
 SG_ DI_a184_autoparkCanceled : 55|1@1+ (1,0) [0|1] "" Vector__XXX
 SG_ DI_a185_autoparkAborted : 56|1@1+ (1,0) [0|1] "" Vector__XXX
 SG_ DI_a186_brakeStand : 57|1@1+ (1,0) [0|1] "" Vector__XXX
 SG_ DI_a187_pedalMisapplication : 58|1@1+ (1,0) [0|1] "" Vector__XXX
 SG_ DI_a188_tireRotationRecommendedG : 59|1@1+ (1,0) [0|1] "" Vector__XXX
 SG_ DI_a189_garageShiftWithPedal : 60|1@1+ (1,0) [0|1] "" Vector__XXX
 SG_ DI_a190_tireRotationRecommended : 61|1@1+ (1,0) [0|1] "" Vector__XXX
 SG_ DI_a191_brakeShiftReq : 62|1@1+ (1,0) [0|1] "" Vector__XXX
 SG_ DI_a192_invalidOdometer : 63|1@1+ (1,0) [0|1] "" Vector__XXX

BO_ 878 DI_alertMatrix4: 8 DI
 SG_ DI_a193_vdcBrakeTorqueFr : 0|1@1+ (1,0) [0|1] "" Vector__XXX
 SG_ DI_a194_vdcBrakeTorqueRe : 1|1@1+ (1,0) [0|1] "" Vector__XXX
 SG_ DI_a195_vdcEspSlipFr : 2|1@1+ (1,0) [0|1] "" Vector__XXX
 SG_ DI_a196_vdcEspSlipRe : 3|1@1+ (1,0) [0|1] "" Vector__XXX
 SG_ DI_a197_vdcEspWheelSaturations : 4|1@1+ (1,0) [0|1] "" Vector__XXX
 SG_ DI_a198_vdcEspMCPressAndSteering : 5|1@1+ (1,0) [0|1] "" Vector__XXX
 SG_ DI_a199_vdcFaulted : 6|1@1+ (1,0) [0|1] "" Vector__XXX
 SG_ DI_a200_vdcModelBasedPlausibilit : 7|1@1+ (1,0) [0|1] "" Vector__XXX
 SG_ DI_a201_decelTorqueLimited : 8|1@1+ (1,0) [0|1] "" Vector__XXX
 SG_ DI_a202_excessHeatUnavailable : 9|1@1+ (1,0) [0|1] "" Vector__XXX
 SG_ DI_a203_TCReducedByADD : 10|1@1+ (1,0) [0|1] "" Vector__XXX
 SG_ DI_a204_vdcRcmLongitudinal : 11|1@1+ (1,0) [0|1] "" Vector__XXX
 SG_ DI_a205_vdcRcmLateral : 12|1@1+ (1,0) [0|1] "" Vector__XXX
 SG_ DI_a206_vdcRcmVertical : 13|1@1+ (1,0) [0|1] "" Vector__XXX
 SG_ DI_a207_vdcPowertrainTorque_dif : 14|1@1+ (1,0) [0|1] "" Vector__XXX
 SG_ DI_a208_vdcPowertrainTorque_dir : 15|1@1+ (1,0) [0|1] "" Vector__XXX
 SG_ DI_a210_vdcOtherControllerStates : 17|1@1+ (1,0) [0|1] "" Vector__XXX
 SG_ DI_a211_vdcMotorSpeed_dif : 18|1@1+ (1,0) [0|1] "" Vector__XXX
 SG_ DI_a212_vdcWheelRotations : 19|1@1+ (1,0) [0|1] "" Vector__XXX
 SG_ DI_a213_lowMuProbabilityChange : 20|1@1+ (1,0) [0|1] "" Vector__XXX
 SG_ DI_a214_vdcWheelSpeedFr : 21|1@1+ (1,0) [0|1] "" Vector__XXX
 SG_ DI_a215_vdcWheelSpeedRe : 22|1@1+ (1,0) [0|1] "" Vector__XXX
 SG_ DI_a216_vdcMBPAlmostTripped : 23|1@1+ (1,0) [0|1] "" Vector__XXX
 SG_ DI_a217_vdcOutputIrrational : 24|1@1+ (1,0) [0|1] "" Vector__XXX
 SG_ DI_a218_vdcOSPreControlActive : 25|1@1+ (1,0) [0|1] "" Vector__XXX
 SG_ DI_a219_vdcOversteerdMzActive : 26|1@1+ (1,0) [0|1] "" Vector__XXX
 SG_ DI_a220_vdcUndersteerDecelActive : 27|1@1+ (1,0) [0|1] "" Vector__XXX
 SG_ DI_a221_vdcUndersteerdMzActive : 28|1@1+ (1,0) [0|1] "" Vector__XXX
 SG_ DI_a222_vdcDisabled : 29|1@1+ (1,0) [0|1] "" Vector__XXX
 SG_ DI_a223_tractionControlDisabled : 30|1@1+ (1,0) [0|1] "" Vector__XXX
 SG_ DI_a224_brakeOverTemp : 31|1@1+ (1,0) [0|1] "" Vector__XXX
 SG_ DI_a225_vyEstimatorDegradedDebug : 32|1@1+ (1,0) [0|1] "" Vector__XXX
 SG_ DI_a226_sysStartConditionNotMet : 33|1@1+ (1,0) [0|1] "" Vector__XXX
 SG_ DI_a227_contactorsNotClosed : 34|1@1+ (1,0) [0|1] "" Vector__XXX
 SG_ DI_a228_brakeTempEstUnavailable : 35|1@1+ (1,0) [0|1] "" Vector__XXX
 SG_ DI_a230_cmpMIA : 37|1@1+ (1,0) [0|1] "" Vector__XXX
 SG_ DI_a231_unintendedReset2 : 38|1@1+ (1,0) [0|1] "" Vector__XXX
 SG_ DI_a232_velocityEstimatorDegrade : 39|1@1+ (1,0) [0|1] "" Vector__XXX
 SG_ DI_a233_frontWheelImpactDetected : 40|1@1+ (1,0) [0|1] "" Vector__XXX
 SG_ DI_a235_trackModeActive : 42|1@1+ (1,0) [0|1] "" Vector__XXX
 SG_ DI_a236_tasMIA : 43|1@1+ (1,0) [0|1] "" Vector__XXX
 SG_ DI_a237_undersideAbuse : 44|1@1+ (1,0) [0|1] "" Vector__XXX
 SG_ DI_a238_secondaryCollisionMitiga : 45|1@1+ (1,0) [0|1] "" Vector__XXX
 SG_ DI_a239_neutralRequestByPM : 46|1@1+ (1,0) [0|1] "" Vector__XXX
 SG_ DI_a240_torqueSplitStuck : 47|1@1+ (1,0) [0|1] "" Vector__XXX
 SG_ DI_a241_vdcMotorSpeed_dir : 48|1@1+ (1,0) [0|1] "" Vector__XXX
 SG_ DI_a242_vdcTrailerSwayDetected : 49|1@1+ (1,0) [0|1] "" Vector__XXX
 SG_ DI_a243_rcuMIA : 50|1@1+ (1,0) [0|1] "" Vector__XXX
 SG_ DI_a244_vseRLSMassMismatch : 51|1@1+ (1,0) [0|1] "" Vector__XXX
 SG_ DI_a245_opdReducedWithoutEbr : 52|1@1+ (1,0) [0|1] "" Vector__XXX
 SG_ DI_a246_opdUnavailable : 53|1@1+ (1,0) [0|1] "" Vector__XXX
 SG_ DI_a248_vdcPreControlHighDynamic : 55|1@1+ (1,0) [0|1] "" Vector__XXX
 SG_ DI_a249_spinDownLearningInProgre : 56|1@1+ (1,0) [0|1] "" Vector__XXX
 SG_ DI_a250_tasSpeedLimitActive : 57|1@1+ (1,0) [0|1] "" Vector__XXX
 SG_ DI_a251_diPowerOnStateMismatch : 58|1@1+ (1,0) [0|1] "" Vector__XXX
 SG_ DI_a253_accelSynchWarn : 60|1@1+ (1,0) [0|1] "" Vector__XXX
 SG_ DI_a254_vehicleStuckDetected : 61|1@1+ (1,0) [0|1] "" Vector__XXX

BO_TX_BU_ 1360 : ADSP;
BO_TX_BU_ 1361 : ADSP;
BO_TX_BU_ 1362 : ADSP;
BO_TX_BU_ 992 : APSB;
BO_TX_BU_ 1864 : APSB;
BO_TX_BU_ 971 : APSB;
BO_TX_BU_ 943 : BB;
BO_TX_BU_ 2029 : BMS;
BO_TX_BU_ 2028 : BMS;
BO_TX_BU_ 551 : CMP;
BO_TX_BU_ 1767 : CP;
BO_TX_BU_ 1085 : CP;
BO_TX_BU_ 777 : DAS;
BO_TX_BU_ 1548 : DAS;
BO_TX_BU_ 854 : DIF;
BO_TX_BU_ 855 : DIF;
BO_TX_BU_ 858 : DIF;
BO_TX_BU_ 859 : DIF;
BO_TX_BU_ 935 : DIR;
BO_TX_BU_ 949 : DIR;
BO_TX_BU_ 965 : DIR;
BO_TX_BU_ 997 : DIR;
BO_TX_BU_ 871 : DI;
BO_TX_BU_ 872 : DI;
BO_TX_BU_ 875 : DI;
BO_TX_BU_ 878 : DI;

CM_ "Tesla Model 3 / Model Y CAN bus database; bus ETH; firmware 2025.20.8. Decoded CAN signal definitions (layout, scaling, units, value tables).";
CM_ BU_ ADSP "Audio amplifier";
CM_ BU_ APSB "APSB ECU";
CM_ BU_ BB "BB ECU";
CM_ BU_ BMS "High-voltage battery management system";
CM_ BU_ CMP "A/C compressor";
CM_ BU_ CP "Charge port controller";
CM_ BU_ DAS "Driver assistance computer";
CM_ BU_ DI "Drive inverter";
CM_ BU_ DIF "Front drive inverter";
CM_ BU_ DIR "Rear drive inverter";
CM_ BU_ DPB "DPB ECU";
CM_ BU_ EPASTP "EPASTP ECU";
CM_ BU_ EPASTS "EPASTS ECU";
CM_ BU_ GTW "Gateway";
CM_ BU_ ICR "ICR ECU";
CM_ BU_ IDB "IDB ECU";
CM_ BU_ OCS1P "Occupant classification system";
CM_ BU_ PM "PM ECU";
CM_ BU_ PMF "PMF ECU";
CM_ BU_ PMR "PMR ECU";
CM_ BU_ PTC "Cabin heater";
CM_ BU_ RCM "Restraint control module";
CM_ BU_ RCU "RCU ECU";
CM_ BU_ TCU "TCU ECU";
CM_ BU_ UI "Touchscreen user interface computer";
CM_ BU_ UIS "UIS ECU";
CM_ BU_ VCLEFT "Left body controller";
CM_ BU_ VCSEC "Vehicle security controller";
CM_ BO_ 1360 "Audio amplifier message: alert log";
CM_ SG_ 1360 ADSP_alertID "Audio amplifier: alert ID";
CM_ SG_ 1360 ADSP_alertState "Audio amplifier: alert state";
CM_ SG_ 1360 ADSP_a035_a2baFaultNode "Audio amplifier: a035 a2ba fault node";
CM_ SG_ 1360 ADSP_a035_timeout "Audio amplifier: a035 timeout";
CM_ SG_ 1360 ADSP_a035_a2baIntrType "Audio amplifier: a035 a2ba intr type";
CM_ SG_ 1360 ADSP_a035_a2baFaultType "Audio amplifier: a035 a2ba fault type";
CM_ SG_ 1360 ADSP_a036_a2bbFaultNode "Audio amplifier: a036 a2bb fault node";
CM_ SG_ 1360 ADSP_a036_timeout "Audio amplifier: a036 timeout";
CM_ SG_ 1360 ADSP_a036_a2bbIntrType "Audio amplifier: a036 a2bb intr type";
CM_ SG_ 1360 ADSP_a036_a2bbFaultType "Audio amplifier: a036 a2bb fault type";
CM_ SG_ 1360 ADSP_a050_open_load "Audio amplifier: a050 open load";
CM_ SG_ 1360 ADSP_a050_short_vcc "Audio amplifier: a050 short vcc";
CM_ SG_ 1360 ADSP_a050_short_gnd "Audio amplifier: a050 short gnd";
CM_ SG_ 1360 ADSP_a050_short_load "Audio amplifier: a050 short load";
CM_ SG_ 1360 ADSP_a050_diag_failed_to_start "Audio amplifier: a050 diag failed to start";
CM_ SG_ 1360 ADSP_a050_diag_failed "Audio amplifier: a050 diag failed";
CM_ SG_ 1360 ADSP_a053_audioSystemUnavailable "Audio amplifier: a053 audio system unavailable";
CM_ SG_ 1360 ADSP_a066_open_load "Audio amplifier: a066 open load";
CM_ SG_ 1360 ADSP_a066_short_vcc "Audio amplifier: a066 short vcc";
CM_ SG_ 1360 ADSP_a066_short_gnd "Audio amplifier: a066 short gnd";
CM_ SG_ 1360 ADSP_a066_short_load "Audio amplifier: a066 short load";
CM_ SG_ 1360 ADSP_a066_diag_failed_to_start "Audio amplifier: a066 diag failed to start";
CM_ SG_ 1360 ADSP_a066_diag_failed "Audio amplifier: a066 diag failed";
CM_ SG_ 1360 ADSP_a067_baseamp0Fault "Audio amplifier: a067 baseamp0 fault";
CM_ SG_ 1360 ADSP_a068_baseamp1Fault "Audio amplifier: a068 baseamp1 fault";
CM_ SG_ 1360 ADSP_a069_baseamp2Fault "Audio amplifier: a069 baseamp2 fault";
CM_ SG_ 1360 ADSP_a070_baseamp3Fault "Audio amplifier: a070 baseamp3 fault";
CM_ SG_ 1360 ADSP_a071_versionMismatch "Audio amplifier: a071 version mismatch";
CM_ BO_ 1361 "Audio amplifier message: alert matrix1";
CM_ SG_ 1361 ADSP_w001_flashInit "Audio amplifier: w001 flash init";
CM_ SG_ 1361 ADSP_w002_exception "Audio amplifier: w002 exception";
CM_ SG_ 1361 ADSP_w003_assert "Audio amplifier: w003 assert";
CM_ SG_ 1361 ADSP_w004_malloc "Audio amplifier: w004 malloc";
CM_ SG_ 1361 ADSP_w005_stackOverflow "Audio amplifier: w005 stack overflow";
CM_ SG_ 1361 ADSP_w006_eavbSeqno "Audio amplifier: w006 eavb seqno";
CM_ SG_ 1361 ADSP_w007_ethLinkErr "Audio amplifier: w007 eth link err";
CM_ SG_ 1361 ADSP_w008_internalTempHigh "Audio amplifier: w008 internal temp high";
CM_ SG_ 1361 ADSP_w010_12vAudioFiltLow "Audio amplifier: w010 12v audio filt low";
CM_ SG_ 1361 ADSP_w011_armHighCpuUsage "Audio amplifier: w011 arm high cpu usage";
CM_ SG_ 1361 ADSP_w012_sharc0HighCpuUsage "Audio amplifier: w012 sharc0 high cpu usage";
CM_ SG_ 1361 ADSP_w013_sharc1HighCpuUsage "Audio amplifier: w013 sharc1 high cpu usage";
CM_ SG_ 1361 ADSP_w014_eavbOverrun "Audio amplifier: w014 eavb overrun";
CM_ SG_ 1361 ADSP_w015_eavbUnderrun "Audio amplifier: w015 eavb underrun";
CM_ SG_ 1361 ADSP_w016_usbRxOverrun "Audio amplifier: w016 usb rx overrun";
CM_ SG_ 1361 ADSP_w017_usbRxUnderrun "Audio amplifier: w017 usb rx underrun";
CM_ SG_ 1361 ADSP_w018_usbTxOverrun "Audio amplifier: w018 usb tx overrun";
CM_ SG_ 1361 ADSP_w019_usbTxUnderrun "Audio amplifier: w019 usb tx underrun";
CM_ SG_ 1361 ADSP_w020_usbTxFailed "Audio amplifier: w020 usb tx failed";
CM_ SG_ 1361 ADSP_w021_usbTxAborted "Audio amplifier: w021 usb tx aborted";
CM_ SG_ 1361 ADSP_w022_emacErr "Audio amplifier: w022 emac err";
CM_ SG_ 1361 ADSP_w023_ethEtharpErr "Audio amplifier: w023 eth etharp err";
CM_ SG_ 1361 ADSP_w024_ethIpfragErr "Audio amplifier: w024 eth ipfrag err";
CM_ SG_ 1361 ADSP_w025_ethIpErr "Audio amplifier: w025 eth ip err";
CM_ SG_ 1361 ADSP_w026_ethIcmpErr "Audio amplifier: w026 eth icmp err";
CM_ SG_ 1361 ADSP_w027_ethUdpErr "Audio amplifier: w027 eth udp err";
CM_ SG_ 1361 ADSP_w028_ethTcpErr "Audio amplifier: w028 eth tcp err";
CM_ SG_ 1361 ADSP_w029_baseamp0SmFault "Audio amplifier: w029 baseamp0 sm fault";
CM_ SG_ 1361 ADSP_w030_ethSysErr "Audio amplifier: w030 eth sys err";
CM_ SG_ 1361 ADSP_w031_baseamp1SmFault "Audio amplifier: w031 baseamp1 sm fault";
CM_ SG_ 1361 ADSP_w032_baseamp2SmFault "Audio amplifier: w032 baseamp2 sm fault";
CM_ SG_ 1361 ADSP_w033_a2baDiscoveryFailed "Audio amplifier: w033 a2ba discovery failed";
CM_ SG_ 1361 ADSP_w034_a2bbDiscoveryFailed "Audio amplifier: w034 a2bb discovery failed";
CM_ SG_ 1361 ADSP_w035_a2baFault "Audio amplifier: w035 a2ba fault";
CM_ SG_ 1361 ADSP_w036_a2bbFault "Audio amplifier: w036 a2bb fault";
CM_ SG_ 1361 ADSP_w037_a2baIdleFailed "Audio amplifier: w037 a2ba idle failed";
CM_ SG_ 1361 ADSP_w038_a2bbIdleFailed "Audio amplifier: w038 a2bb idle failed";
CM_ SG_ 1361 ADSP_w039_ancPing "Audio amplifier: w039 anc ping";
CM_ SG_ 1361 ADSP_w040_socSciHeartbeat "Audio amplifier: w040 soc sci heartbeat";
CM_ SG_ 1361 ADSP_w041_twiWriteError "Audio amplifier: w041 twi write error";
CM_ SG_ 1361 ADSP_w042_twiReadError "Audio amplifier: w042 twi read error";
CM_ SG_ 1361 ADSP_w043_aweControlError "Audio amplifier: w043 awe control error";
CM_ SG_ 1361 ADSP_w044_canethChecksum "Audio amplifier: w044 caneth checksum";
CM_ SG_ 1361 ADSP_w045_ancEnableFail "Audio amplifier: w045 anc enable fail";
CM_ SG_ 1361 ADSP_w046_sharc0AweFrameOverload "Audio amplifier: w046 sharc0 awe frame overload";
CM_ SG_ 1361 ADSP_w047_sharc1AweFrameOverload "Audio amplifier: w047 sharc1 awe frame overload";
CM_ SG_ 1361 ADSP_w048_eCallSelfTestFailed "Audio amplifier: w048 e call self test failed";
CM_ SG_ 1361 ADSP_w049_sae "Audio amplifier: w049 sae";
CM_ SG_ 1361 ADSP_w050_extSpkFault "Audio amplifier: w050 ext spk fault";
CM_ SG_ 1361 ADSP_w051_extspkFailure "Audio amplifier: w051 extspk failure";
CM_ SG_ 1361 ADSP_w052_criticalReset "Audio amplifier: w052 critical reset";
CM_ SG_ 1361 ADSP_w053_audioSystemUnavailable "Audio amplifier: w053 audio system unavailable";
CM_ SG_ 1361 ADSP_w054_canethRxError "Audio amplifier: w054 caneth rx error";
CM_ SG_ 1361 ADSP_w055_hfpMathExcept1NAN "Audio amplifier: w055 hfp math except1 NAN";
CM_ SG_ 1361 ADSP_w056_hfpMathExcept1INF "Audio amplifier: w056 hfp math except1 INF";
CM_ SG_ 1361 ADSP_w057_hfpMathExcept2NAN "Audio amplifier: w057 hfp math except2 NAN";
CM_ SG_ 1361 ADSP_w058_hfpMathExcept2INF "Audio amplifier: w058 hfp math except2 INF";
CM_ SG_ 1361 ADSP_w059_nvmmError "Audio amplifier: w059 nvmm error";
CM_ SG_ 1361 ADSP_w060_baseamp3SmFault "Audio amplifier: w060 baseamp3 sm fault";
CM_ SG_ 1361 ADSP_w061_tcuGpioServiceError "Audio amplifier: w061 tcu gpio service error";
CM_ BO_ 1362 "Audio amplifier message: alert matrix2";
CM_ SG_ 1362 ADSP_w065_tcuGpioExpanderCritica "Audio amplifier: w065 tcu gpio expander critical error";
CM_ SG_ 1362 ADSP_w066_rearPwsFault "Audio amplifier: w066 rear pws fault";
CM_ SG_ 1362 ADSP_w067_baseamp0Fault "Audio amplifier: w067 baseamp0 fault";
CM_ SG_ 1362 ADSP_w068_baseamp1Fault "Audio amplifier: w068 baseamp1 fault";
CM_ SG_ 1362 ADSP_w069_baseamp2Fault "Audio amplifier: w069 baseamp2 fault";
CM_ SG_ 1362 ADSP_w070_baseamp3Fault "Audio amplifier: w070 baseamp3 fault";
CM_ SG_ 1362 ADSP_w071_versionMismatch "Audio amplifier: w071 version mismatch";
CM_ SG_ 1362 ADSP_w072_turnSignalChannelUnder "Audio amplifier: w072 turn signal channel underrun";
CM_ SG_ 1362 ADSP_w073_romFLError "Audio amplifier: w073 rom FL error";
CM_ SG_ 1362 ADSP_w074_tdspArmXrun "Audio amplifier: w074 tdsp arm xrun";
CM_ SG_ 1362 ADSP_w075_tdspArmError "Audio amplifier: w075 tdsp arm error";
CM_ SG_ 1362 ADSP_w076_activeSafetyChannelUnd "Audio amplifier: w076 active safety channel underrun";
CM_ BO_ 992 "APSB ECU message: power state inputs";
CM_ SG_ 992 APSB_A_lowPowerRequest "APSB ECU: a low power request";
CM_ SG_ 992 APSB_A_lowPowerRequestor "APSB ECU: a low power requestor";
CM_ SG_ 992 APSB_A_forcePowerOffRequest "APSB ECU: a force power off request";
CM_ SG_ 992 APSB_B_lowPowerRequest "APSB ECU: b low power request";
CM_ SG_ 992 APSB_B_lowPowerRequestor "APSB ECU: b low power requestor";
CM_ SG_ 992 APSB_B_forcePowerOffRequest "APSB ECU: b force power off request";
CM_ BO_ 1864 "APSB ECU message: state";
CM_ SG_ 1864 APSB_primaryTurbo "APSB ECU: primary turbo";
CM_ SG_ 1864 APSB_A_arbState "APSB ECU: a arb state";
CM_ SG_ 1864 APSB_A_powerState "The state of the power state machine of Turbo A.";
CM_ SG_ 1864 APSB_A_sleepState "APSB ECU: a sleep state";
CM_ SG_ 1864 APSB_A_resetState "APSB ECU: a reset state";
CM_ SG_ 1864 APSB_A_faultState "APSB ECU: a fault state";
CM_ SG_ 1864 APSB_secondaryTurbo "APSB ECU: secondary turbo";
CM_ SG_ 1864 APSB_B_arbState "APSB ECU: b arb state";
CM_ SG_ 1864 APSB_B_powerState "The state of the power state machine of Turbo B.";
CM_ SG_ 1864 APSB_B_sleepState "APSB ECU: b sleep state";
CM_ SG_ 1864 APSB_B_resetState "APSB ECU: b reset state";
CM_ SG_ 1864 APSB_B_faultState "APSB ECU: b fault state";
CM_ SG_ 1864 APSB_stateCounter "APSB ECU: state counter";
CM_ BO_ 971 "APSB ECU message: status";
CM_ SG_ 971 APSB_appStatusMonitorState "APSB ECU: app status monitor state";
CM_ SG_ 971 APSB_vehBehaviorState "APSB ECU: veh behavior state";
CM_ SG_ 971 APSB_canMaster "Indicates which of the autopilot computers is currently controlling outgoing CAN traffic.; raw 3 = signal not available (SNA)";
CM_ SG_ 971 APSB_appGpioState "APSB ECU: app gpio state";
CM_ SG_ 971 APSB_eacInternalState "APSB ECU: eac internal state";
CM_ SG_ 971 APSB_switchState "APSB ECU: switch state";
CM_ SG_ 971 APSB_apbStatusMonitorState "APSB ECU: apb status monitor state";
CM_ SG_ 971 APSB_apbGpioState "APSB ECU: apb gpio state";
CM_ SG_ 971 APSB_statusCounter "APSB ECU: status counter";
CM_ SG_ 971 APSB_locLimitReason "APSB ECU: loc limit reason";
CM_ SG_ 971 APSB_appPowerStateRequest "APSB ECU: app power state request";
CM_ SG_ 971 APSB_appPowerStateReason "APSB ECU: app power state reason";
CM_ SG_ 971 APSB_apbPowerStateRequest "APSB ECU: apb power state request";
CM_ SG_ 971 APSB_apbPowerStateReason "APSB ECU: apb power state reason";
CM_ SG_ 971 APSB_heaterStateDebug "APSB ECU: heater state debug; raw 7 = signal not available (SNA)";
CM_ SG_ 971 APSB_autosummonCounter "APSB ECU: autosummon counter";
CM_ SG_ 971 APSB_autosummonAlert "APSB ECU: autosummon alert";
CM_ SG_ 971 APSB_gpsAntennaState "APSB ECU: gps antenna state";
CM_ SG_ 971 APSB_arbState "APSB ECU: arb state";
CM_ SG_ 971 APSB_socPowerOperatingMode "APSB ECU: soc power operating mode";
CM_ BO_ 943 "BB ECU message: status";
CM_ SG_ 943 BB_statusChecksum "BB ECU: status checksum";
CM_ SG_ 943 BB_statusCounter "BB ECU: status counter";
CM_ SG_ 943 BB_sOutputRod "Reports the measured brake booster (BB) plunger piston position";
CM_ SG_ 943 BB_sOutputRodQF "Reports the BB_sOutputRod signal qualifier";
CM_ SG_ 943 BB_sInputRod "Reports the measured brake booster (BB) input rod stroke.";
CM_ SG_ 943 BB_sInputRodQF "Reports the BB_sInputRod signal qualifier.";
CM_ SG_ 943 BB_driverBrakeApply "Indicates whether the driver operates the brake pedal. Only active when the driver brakes, not when an external brake command implemented on brake booster (BB).";
CM_ SG_ 943 BB_driverBrakeApplyQF "Qualifier for BB_driverBrakeApply";
CM_ SG_ 943 BB_boosterStatus "Indication of the brake booster (BB) functional state";
CM_ SG_ 943 BB_warningLampRequest "Request from brake booster (BB) to enable the red brake lamp";
CM_ SG_ 943 BB_brakeFluidLevel "Indication of the brake fluid reservoir fluid level sensor status measured by the brake booster (BB).";
CM_ SG_ 943 BB_internalState "Indication of the brake booster (BB) internal state";
CM_ BO_ 2029 "High-voltage battery management system message: debug info 10 hz";
CM_ SG_ 2029 BMS_10HzDebug_Id "High-voltage battery management system: 10 hz debug id";
CM_ SG_ 2029 BMS_activeCoolCellTargetT "High-voltage battery management system: active cool cell target t";
CM_ SG_ 2029 BMS_passiveCoolCellTargetT "High-voltage battery management system: passive cool cell target t";
CM_ BO_ 2028 "High-voltage battery management system message: thermal status2";
CM_ SG_ 2028 BMS_coldStagnationLimit "Minimum temperature at which the pack is allowed to be used as a heat-energy source";
CM_ SG_ 2028 BMS_hotStagnationLimit "Maximum temperature at which we allow the pack to be used for heat-energy storage";
CM_ SG_ 2028 BMS_hotCellTempLimit "Maximum temperature at which the pack will allow limp mode levels of current";
CM_ SG_ 2028 BMS_activeCoolCellReferenceT "Desired cell temperature reference which composes the temperature trajectory portion of the active cooling target temperature controls";
CM_ SG_ 2028 BMS_activeHeatCellTargetT "Desired cell temperature which feeds as an input to the active heating target temperature, before any additional controls calculations";
CM_ SG_ 2028 BMS_cellTempTargetMode "Operating mode of the thermal controls for the Battery Management System (BMS)";
CM_ SG_ 2028 BMS_requestDischarge "Flag identifying when the Battery Management System (BMS) is requesting the battery pack to be discharged";
CM_ BO_ 551 "A/C compressor message: HV status";
CM_ SG_ 551 CMP_inputHVVoltage "Compressor high voltage input voltage";
CM_ SG_ 551 CMP_inputLVVoltage "A/C compressor: input LV voltage";
CM_ SG_ 551 CMP_inputHVCurrent "A/C compressor: input HV current";
CM_ SG_ 551 CMP_inputHVPower "Compressor high voltage input power";
CM_ BO_ 1767 "Charge port controller message: iso tp pipe to pncd";
CM_ SG_ 1767 CP_isoTpToPncdData "Charge port controller: iso tp to pncd data";
CM_ BO_ 1085 "Charge port controller message: charge status log";
CM_ SG_ 1085 CP_hvChargeStatus_log "Charge port controller: hv charge status log";
CM_ SG_ 1085 CP_chargeShutdownRequest_log "Charge port controller: charge shutdown request log";
CM_ SG_ 1085 CP_acChargeCurrentLimit_log "Charge port controller: ac charge current limit log";
CM_ SG_ 1085 CP_internalMaxDcCurrentLimit_log "Charge port controller: internal max dc current limit log";
CM_ SG_ 1085 CP_vehicleIsoCheckRequired_log "Charge port controller: vehicle iso check required log";
CM_ SG_ 1085 CP_vehiclePrechargeRequired_log "Charge port controller: vehicle precharge required log";
CM_ SG_ 1085 CP_internalMaxAcCurrentLimit_log "Charge port controller: internal max ac current limit log";
CM_ SG_ 1085 CP_evseChargeType_log "Charge port controller: evse charge type log";
CM_ SG_ 1085 CP_chgLimitMode_log "Charge port controller: chg limit mode log";
CM_ BO_ 777 "Driver assistance computer message: object";
CM_ SG_ 777 DAS_objectId "Driver assistance computer: object id";
CM_ SG_ 777 DAS_leadVehType "Driver assistance computer: lead veh type";
CM_ SG_ 777 DAS_leadVehRelevantForControl "Driver assistance computer: lead veh relevant for control";
CM_ SG_ 777 DAS_leadVehDx "Measures the distance to lead vehicle, or vehicle in the ego lane.; raw 255 = signal not available (SNA)";
CM_ SG_ 777 DAS_leadVehVxRel "Driver assistance computer: lead veh vx rel; raw 15 = signal not available (SNA)";
CM_ SG_ 777 DAS_leadVehDy "Driver assistance computer: lead veh dy";
CM_ SG_ 777 DAS_leadVehId "Driver assistance computer: lead veh id; raw 127 = signal not available (SNA)";
CM_ SG_ 777 DAS_leadVeh2Type "Driver assistance computer: lead veh2 type";
CM_ SG_ 777 DAS_leadVeh2RelevantForControl "Driver assistance computer: lead veh2 relevant for control";
CM_ SG_ 777 DAS_leadVeh2Dx "Driver assistance computer: lead veh2 dx; raw 255 = signal not available (SNA)";
CM_ SG_ 777 DAS_leadVeh2VxRel "Driver assistance computer: lead veh2 vx rel; raw 15 = signal not available (SNA)";
CM_ SG_ 777 DAS_leadVeh2Dy "Driver assistance computer: lead veh2 dy";
CM_ SG_ 777 DAS_leadVeh2Id "Driver assistance computer: lead veh2 id; raw 0 = signal not available (SNA)";
CM_ SG_ 777 DAS_leftVehType "Driver assistance computer: left veh type";
CM_ SG_ 777 DAS_leftVehRelevantForControl "Driver assistance computer: left veh relevant for control";
CM_ SG_ 777 DAS_leftVehDx "Driver assistance computer: left veh dx; raw 255 = signal not available (SNA)";
CM_ SG_ 777 DAS_leftVehVxRel "Driver assistance computer: left veh vx rel; raw 15 = signal not available (SNA)";
CM_ SG_ 777 DAS_leftVehDy "Driver assistance computer: left veh dy";
CM_ SG_ 777 DAS_leftVehId "Driver assistance computer: left veh id; raw 127 = signal not available (SNA)";
CM_ SG_ 777 DAS_leftVeh2Type "Driver assistance computer: left veh2 type";
CM_ SG_ 777 DAS_leftVeh2RelevantForControl "Driver assistance computer: left veh2 relevant for control";
CM_ SG_ 777 DAS_leftVeh2Dx "Driver assistance computer: left veh2 dx; raw 255 = signal not available (SNA)";
CM_ SG_ 777 DAS_leftVeh2VxRel "Driver assistance computer: left veh2 vx rel; raw 15 = signal not available (SNA)";
CM_ SG_ 777 DAS_leftVeh2Dy "Driver assistance computer: left veh2 dy";
CM_ SG_ 777 DAS_leftVeh2Id "Driver assistance computer: left veh2 id; raw 0 = signal not available (SNA)";
CM_ SG_ 777 DAS_rightVehType "Driver assistance computer: right veh type";
CM_ SG_ 777 DAS_rightVehRelevantForControl "Driver assistance computer: right veh relevant for control";
CM_ SG_ 777 DAS_rightVehDx "Driver assistance computer: right veh dx; raw 255 = signal not available (SNA)";
CM_ SG_ 777 DAS_rightVehVxRel "Driver assistance computer: right veh vx rel; raw 15 = signal not available (SNA)";
CM_ SG_ 777 DAS_rightVehDy "Driver assistance computer: right veh dy";
CM_ SG_ 777 DAS_rightVehId "Driver assistance computer: right veh id; raw 127 = signal not available (SNA)";
CM_ SG_ 777 DAS_rightVeh2Type "Driver assistance computer: right veh2 type";
CM_ SG_ 777 DAS_rightVeh2RelevantForControl "Driver assistance computer: right veh2 relevant for control";
CM_ SG_ 777 DAS_rightVeh2Dx "Driver assistance computer: right veh2 dx; raw 255 = signal not available (SNA)";
CM_ SG_ 777 DAS_rightVeh2VxRel "Driver assistance computer: right veh2 vx rel; raw 15 = signal not available (SNA)";
CM_ SG_ 777 DAS_rightVeh2Dy "Driver assistance computer: right veh2 dy";
CM_ SG_ 777 DAS_rightVeh2Id "Driver assistance computer: right veh2 id; raw 0 = signal not available (SNA)";
CM_ SG_ 777 DAS_cutinVehType "Driver assistance computer: cutin veh type";
CM_ SG_ 777 DAS_cutinVehRelevantForControl "Driver assistance computer: cutin veh relevant for control";
CM_ SG_ 777 DAS_cutinVehDx "Driver assistance computer: cutin veh dx; raw 255 = signal not available (SNA)";
CM_ SG_ 777 DAS_cutinVehVxRel "Driver assistance computer: cutin veh vx rel; raw 15 = signal not available (SNA)";
CM_ SG_ 777 DAS_cutinVehDy "Driver assistance computer: cutin veh dy";
CM_ SG_ 777 DAS_cutinVehId "Driver assistance computer: cutin veh id; raw 127 = signal not available (SNA)";
CM_ SG_ 777 DAS_roadSignColor "Driver assistance computer: road sign color";
CM_ SG_ 777 DAS_roadSignId "Driver assistance computer: road sign id; raw 255 = signal not available (SNA)";
CM_ SG_ 777 DAS_roadSignStopLineDist "Driver assistance computer: road sign stop line dist; raw 1023 = signal not available (SNA)";
CM_ SG_ 777 DAS_roadSignControlActive "Driver assistance computer: road sign control active";
CM_ SG_ 777 DAS_roadSignSource "Driver assistance computer: road sign source";
CM_ SG_ 777 DAS_roadSignArrow "Driver assistance computer: road sign arrow";
CM_ SG_ 777 DAS_roadSignOrientation "Driver assistance computer: road sign orientation";
CM_ BO_ 1548 "Driver assistance computer message: telemetry radar";
CM_ SG_ 1548 DAS_TR_ObjIndex "Driver assistance computer: TR obj index";
CM_ SG_ 1548 DAS_TR_Counter "Driver assistance computer: TR counter";
CM_ SG_ 1548 DAS_TR_Obj00_Class "Driver assistance computer: TR obj00 class";
CM_ SG_ 1548 DAS_TR_Obj00_Dx "Driver assistance computer: TR obj00 dx";
CM_ SG_ 1548 DAS_TR_Obj00_Dy "Driver assistance computer: TR obj00 dy";
CM_ SG_ 1548 DAS_TR_Obj00_Vx "Driver assistance computer: TR obj00 vx";
CM_ SG_ 1548 DAS_TR_Obj00_RCS "Driver assistance computer: TR obj00 RCS";
CM_ SG_ 1548 DAS_TR_Obj00_Length "Driver assistance computer: TR obj00 length";
CM_ SG_ 1548 DAS_TR_Obj00_MovingState "Driver assistance computer: TR obj00 moving state";
CM_ SG_ 1548 DAS_TR_Obj00_Dz "Driver assistance computer: TR obj00 dz";
CM_ SG_ 1548 DAS_TR_Obj00_Exist "Driver assistance computer: TR obj00 exist";
CM_ BO_ 854 "Front drive inverter message: alert matrix1";
CM_ SG_ 854 DIF_a001_hwPhaseAgateDrive "Front drive inverter: a001 hw phase agate drive";
CM_ SG_ 854 DIF_a002_hwPhaseBgateDrive "Front drive inverter: a002 hw phase bgate drive";
CM_ SG_ 854 DIF_a003_hwPhaseCgateDrive "Front drive inverter: a003 hw phase cgate drive";
CM_ SG_ 854 DIF_a004_hwPhaseApeak "Front drive inverter: a004 hw phase apeak";
CM_ SG_ 854 DIF_a005_hwPhaseBpeak "Front drive inverter: a005 hw phase bpeak";
CM_ SG_ 854 DIF_a006_hwPhaseCpeak "Front drive inverter: a006 hw phase cpeak";
CM_ SG_ 854 DIF_a007_statorAnomalyDetected "Front drive inverter: a007 stator anomaly detected";
CM_ SG_ 854 DIF_a008_hwEncoderA "Front drive inverter: a008 hw encoder a";
CM_ SG_ 854 DIF_a009_hwEncoderB "Front drive inverter: a009 hw encoder b";
CM_ SG_ 854 DIF_a010_unintendedReset "Front drive inverter: a010 unintended reset";
CM_ SG_ 854 DIF_a011_swPowerStageNotReady "Front drive inverter: a011 sw power stage not ready";
CM_ SG_ 854 DIF_a012_hvilNotClosed "Front drive inverter: a012 hvil not closed";
CM_ SG_ 854 DIF_a013_eccError "Front drive inverter: a013 ecc error";
CM_ SG_ 854 DIF_a014_activeDamping "Front drive inverter: a014 active damping";
CM_ SG_ 854 DIF_a015_mechSafeStateAnomaly "Front drive inverter: a015 mech safe state anomaly";
CM_ SG_ 854 DIF_a016_safeStateApplied "Front drive inverter: a016 safe state applied";
CM_ SG_ 854 DIF_a017_hwPedalMonitor "Front drive inverter: a017 hw pedal monitor";
CM_ SG_ 854 DIF_a018_hwLVSupplyUV "Front drive inverter: a018 hw LV supply UV";
CM_ SG_ 854 DIF_a020_hwMotorEncoder "Front drive inverter: a020 hw motor encoder";
CM_ SG_ 854 DIF_a021_hwBusOV "Front drive inverter: a021 hw bus OV";
CM_ SG_ 854 DIF_a022_hw5vSupplyUV "Front drive inverter: a022 hw5v supply UV";
CM_ SG_ 854 DIF_a024_selfTest "Front drive inverter: a024 self test";
CM_ SG_ 854 DIF_a025_phaseApeak "Front drive inverter: a025 phase apeak";
CM_ SG_ 854 DIF_a026_phaseBpeak "Front drive inverter: a026 phase bpeak";
CM_ SG_ 854 DIF_a027_phaseCpeak "Front drive inverter: a027 phase cpeak";
CM_ SG_ 854 DIF_a028_phaseArms "Front drive inverter: a028 phase arms";
CM_ SG_ 854 DIF_a029_phaseBrms "Front drive inverter: a029 phase brms";
CM_ SG_ 854 DIF_a030_phaseCrms "Front drive inverter: a030 phase crms";
CM_ SG_ 854 DIF_a031_phaseAcurrentOffset "Front drive inverter: a031 phase acurrent offset";
CM_ SG_ 854 DIF_a032_phaseBcurrentOffset "Front drive inverter: a032 phase bcurrent offset";
CM_ SG_ 854 DIF_a033_phaseAcurrentSensor "Front drive inverter: a033 phase acurrent sensor";
CM_ SG_ 854 DIF_a034_phaseBcurrentSensor "Front drive inverter: a034 phase bcurrent sensor";
CM_ SG_ 854 DIF_a035_phaseCurrentBalance "Front drive inverter: a035 phase current balance";
CM_ SG_ 854 DIF_a036_busOV "Front drive inverter: a036 bus OV";
CM_ SG_ 854 DIF_a037_busUV "Front drive inverter: a037 bus UV";
CM_ SG_ 854 DIF_a038_busVsensor "Front drive inverter: a038 bus vsensor";
CM_ SG_ 854 DIF_a039_exceptionUndefinedInstr "Front drive inverter: a039 exception undefined instruction";
CM_ SG_ 854 DIF_a040_difMIA "Front drive inverter: a040 dif MIA";
CM_ SG_ 854 DIF_a041_sdcMIA "Front drive inverter: a041 sdc MIA";
CM_ SG_ 854 DIF_a042_inletSensor "Front drive inverter: a042 inlet sensor";
CM_ SG_ 854 DIF_a043_outletOT "Front drive inverter: a043 outlet OT";
CM_ SG_ 854 DIF_a044_outletUT "Front drive inverter: a044 outlet UT";
CM_ SG_ 854 DIF_a045_outletSensor "Front drive inverter: a045 outlet sensor";
CM_ SG_ 854 DIF_a046_statorOT "Front drive inverter: a046 stator OT";
CM_ SG_ 854 DIF_a047_statorSensor1 "Front drive inverter: a047 stator sensor1";
CM_ SG_ 854 DIF_a048_statorSensor2 "Front drive inverter: a048 stator sensor2";
CM_ SG_ 854 DIF_a049_statorSensorDiff "Front drive inverter: a049 stator sensor diff";
CM_ SG_ 854 DIF_a050_noStatorSensor "Front drive inverter: a050 no stator sensor";
CM_ SG_ 854 DIF_a052_dirMIA "Front drive inverter: a052 dir MIA";
CM_ SG_ 854 DIF_a053_unexpectedLatchState "Front drive inverter: a053 unexpected latch state";
CM_ SG_ 854 DIF_a054_driveInverterOT "Front drive inverter: a054 drive inverter OT";
CM_ SG_ 854 DIF_a055_trqCrossCheck "Front drive inverter: a055 trq cross check";
CM_ SG_ 854 DIF_a056_ambientOT "Front drive inverter: a056 ambient OT";
CM_ SG_ 854 DIF_a057_ambientUT "Front drive inverter: a057 ambient UT";
CM_ SG_ 854 DIF_a058_ambientSensor "Front drive inverter: a058 ambient sensor";
CM_ SG_ 854 DIF_a059_heatsinkOT "Front drive inverter: a059 heatsink OT";
CM_ SG_ 854 DIF_a060_heatsinkUT "Front drive inverter: a060 heatsink UT";
CM_ SG_ 854 DIF_a061_heatsinkSensor "Front drive inverter: a061 heatsink sensor";
CM_ SG_ 854 DIF_a062_systemLimpMode "Front drive inverter: a062 system limp mode";
CM_ SG_ 854 DIF_a063_bbMIA "Front drive inverter: a063 bb MIA";
CM_ SG_ 854 DIF_a064_torqueIntervention "Front drive inverter: a064 torque intervention";
CM_ BO_ 855 "Front drive inverter message: alert matrix2";
CM_ SG_ 855 DIF_a065_canHardwareBusB "Front drive inverter: a065 can hardware bus b";
CM_ SG_ 855 DIF_a066_canDataBusB "Front drive inverter: a066 can data bus b";
CM_ SG_ 855 DIF_a067_canOverrunBusB "Front drive inverter: a067 can overrun bus b";
CM_ SG_ 855 DIF_a069_rotorTempLimit "Front drive inverter: a069 rotor temp limit";
CM_ SG_ 855 DIF_a070_udsTransactionInitiated "Front drive inverter: a070 uds transaction initiated";
CM_ SG_ 855 DIF_a071_busDisconnected "Front drive inverter: a071 bus disconnected";
CM_ SG_ 855 DIF_a072_gateDriveFaultCounter "Front drive inverter: a072 gate drive fault counter";
CM_ SG_ 855 DIF_a073_motorSpeed "Front drive inverter: a073 motor speed";
CM_ SG_ 855 DIF_a074_motorEncoder "Front drive inverter: a074 motor encoder";
CM_ SG_ 855 DIF_a075_motorSpeedMismatch "Front drive inverter: a075 motor speed mismatch";
CM_ SG_ 855 DIF_a076_lvSupplyOV "Front drive inverter: a076 lv supply OV";
CM_ SG_ 855 DIF_a077_lvSupplyUV "Front drive inverter: a077 lv supply UV";
CM_ SG_ 855 DIF_a078_adcRefLow "Front drive inverter: a078 adc ref low";
CM_ SG_ 855 DIF_a079_adcRefHigh "Front drive inverter: a079 adc ref high";
CM_ SG_ 855 DIF_a081_P0BFF_DIF_EM_CurrentHig "Front drive inverter: a081 P0 BFF DIF EM current high";
CM_ SG_ 855 DIF_a082_P7837_DIF_ECU_DemoTimer "Front drive inverter: a082 P7837 DIF ECU demo timer";
CM_ SG_ 855 DIF_a083_PABCD_DIF_ECU_DemoWindo "Front drive inverter: a083 PABCD DIF ECU demo window";
CM_ SG_ 855 DIF_a084_eccTestData0 "Front drive inverter: a084 ecc test data0";
CM_ SG_ 855 DIF_a086_activeDischargeOn "Front drive inverter: a086 active discharge on";
CM_ SG_ 855 DIF_a087_gtwMIA "Front drive inverter: a087 gtw MIA";
CM_ SG_ 855 DIF_a088_uiMIA "Front drive inverter: a088 ui MIA";
CM_ SG_ 855 DIF_a090_pmMIA "Front drive inverter: a090 pm MIA";
CM_ SG_ 855 DIF_a091_espMIA "Front drive inverter: a091 esp MIA";
CM_ SG_ 855 DIF_a092_bmsMIA "Front drive inverter: a092 bms MIA";
CM_ SG_ 855 DIF_a093_canHardwareBusA "Front drive inverter: a093 can hardware bus a";
CM_ SG_ 855 DIF_a094_canDataBusA "Front drive inverter: a094 can data bus a";
CM_ SG_ 855 DIF_a095_canOverrunBusA "Front drive inverter: a095 can overrun bus a";
CM_ SG_ 855 DIF_a096_memoryError "Front drive inverter: a096 memory error";
CM_ SG_ 855 DIF_a097_eepromError "Front drive inverter: a097 eeprom error";
CM_ SG_ 855 DIF_a098_intTimeTooLong "Front drive inverter: a098 int time too long";
CM_ SG_ 855 DIF_a099_threadOverrun "Front drive inverter: a099 thread overrun";
CM_ SG_ 855 DIF_a100_assertion "Front drive inverter: a100 assertion";
CM_ SG_ 855 DIF_a101_eccTestData1 "Front drive inverter: a101 ecc test data1";
CM_ SG_ 855 DIF_a102_exceptionPrefetchAbort "Front drive inverter: a102 exception prefetch abort";
CM_ SG_ 855 DIF_a103_lowFlow "Front drive inverter: a103 low flow";
CM_ SG_ 855 DIF_a107_fpgaError "Front drive inverter: a107 fpga error";
CM_ SG_ 855 DIF_a108_stateTrans "Front drive inverter: a108 state trans";
CM_ SG_ 855 DIF_a109_ahbWriteError "Front drive inverter: a109 ahb write error";
CM_ SG_ 855 DIF_a110_brakeMIA "Front drive inverter: a110 brake MIA";
CM_ SG_ 855 DIF_a111_badPhaseSensorCalib "Front drive inverter: a111 bad phase sensor calib";
CM_ SG_ 855 DIF_a112_noPhaseCurrent "Front drive inverter: a112 no phase current";
CM_ SG_ 855 DIF_a113_noFuncHeatsinkSensor "Front drive inverter: a113 no func heatsink sensor";
CM_ SG_ 855 DIF_a114_exceptionDataAbort "Front drive inverter: a114 exception data abort";
CM_ SG_ 855 DIF_a115_exceptionDataAbort2 "Front drive inverter: a115 exception data abort2";
CM_ SG_ 855 DIF_a116_highSpeedWearCounter "Front drive inverter: a116 high speed wear counter";
CM_ SG_ 855 DIF_a117_diMIA "Front drive inverter: a117 di MIA";
CM_ SG_ 855 DIF_a119_hvpMIA "Front drive inverter: a119 hvp MIA";
CM_ SG_ 855 DIF_a120_hvlinkMIA "Front drive inverter: a120 hvlink MIA";
CM_ SG_ 855 DIF_a121_motorControlRegulation "Front drive inverter: a121 motor control regulation";
CM_ SG_ 855 DIF_a122_highStackUsage "Front drive inverter: a122 high stack usage";
CM_ SG_ 855 DIF_a123_lossMotorControl "Front drive inverter: a123 loss motor control";
CM_ SG_ 855 DIF_a126_limpMode "Front drive inverter: a126 limp mode";
CM_ SG_ 855 DIF_a127_gracefulPowerOff "Front drive inverter: a127 graceful power off";
CM_ SG_ 855 DIF_a128_fpgaVersionMismatch "Front drive inverter: a128 fpga version mismatch";
CM_ BO_ 858 "Front drive inverter message: alert matrix3";
CM_ SG_ 858 DIF_a133_capacitorOT "Front drive inverter: a133 capacitor OT";
CM_ SG_ 858 DIF_a134_wheelSpeedIrrational "Front drive inverter: a134 wheel speed irrational";
CM_ SG_ 858 DIF_a136_spiError "Front drive inverter: a136 spi error";
CM_ SG_ 858 DIF_a142_highLashAngle "Front drive inverter: a142 high lash angle";
CM_ SG_ 858 DIF_a144_configMismatch "Front drive inverter: a144 config mismatch";
CM_ SG_ 858 DIF_a147_highTorqueWearLimit "Front drive inverter: a147 high torque wear limit";
CM_ SG_ 858 DIF_a148_burnInCycleEnded "Front drive inverter: a148 burn in cycle ended";
CM_ SG_ 858 DIF_a149_oilPumpFailure "Front drive inverter: a149 oil pump failure";
CM_ SG_ 858 DIF_a150_busVD "Front drive inverter: a150 bus VD";
CM_ SG_ 858 DIF_a151_shockTorqueLimiter "Front drive inverter: a151 shock torque limiter";
CM_ SG_ 858 DIF_a152_linError "Front drive inverter: a152 lin error";
CM_ SG_ 858 DIF_a153_oilPumpDiagnostics "Front drive inverter: a153 oil pump diagnostics";
CM_ SG_ 858 DIF_a154_resolver "Front drive inverter: a154 resolver";
CM_ SG_ 858 DIF_a155_vcfrontMIA "Front drive inverter: a155 vcfront MIA";
CM_ SG_ 858 DIF_a156_currentObserver "Front drive inverter: a156 current observer";
CM_ SG_ 858 DIF_a157_rcmMIA "Front drive inverter: a157 rcm MIA";
CM_ SG_ 858 DIF_a158_ibstMIA "Front drive inverter: a158 ibst MIA";
CM_ SG_ 858 DIF_a160_busVoltageAnomaly "Front drive inverter: a160 bus voltage anomaly";
CM_ SG_ 858 DIF_a161_epas3pMIA "Front drive inverter: a161 epas3p MIA";
CM_ SG_ 858 DIF_a162_endOfLifetimeBurnIn "Front drive inverter: a162 end of lifetime burn in";
CM_ SG_ 858 DIF_a174_unitMayNotRestart "Front drive inverter: a174 unit may not restart";
CM_ SG_ 858 DIF_a176_safetyICFault "Front drive inverter: a176 safety IC fault";
CM_ SG_ 858 DIF_a177_fluxReferenceCorrected "Front drive inverter: a177 flux reference corrected";
CM_ BO_ 859 "Front drive inverter message: alert matrix4";
CM_ SG_ 859 DIF_a202_excessHeatUnavailable "Front drive inverter: a202 excess heat unavailable";
CM_ SG_ 859 DIF_a225_tmpEstPlausibility "Front drive inverter: a225 tmp est plausibility";
CM_ SG_ 859 DIF_a231_unintendedReset2 "Front drive inverter: a231 unintended reset2";
CM_ SG_ 859 DIF_a233_diMsgMissed "Front drive inverter: a233 di msg missed";
CM_ SG_ 859 DIF_a234_pcsMIA "Front drive inverter: a234 pcs MIA";
CM_ SG_ 859 DIF_a236_tasMIA "Front drive inverter: a236 tas MIA";
CM_ SG_ 859 DIF_a241_systemThermallyLimited "Front drive inverter: a241 system thermally limited";
CM_ SG_ 859 DIF_a242_spinDownLearning "Front drive inverter: a242 spin down learning";
CM_ SG_ 859 DIF_a243_ecuLogAvailable "Front drive inverter: a243 ecu log available";
CM_ SG_ 859 DIF_a244_mechSafeStateApplied "Front drive inverter: a244 mech safe state applied";
CM_ SG_ 859 DIF_a245_mechSafeStatePreWarn "Front drive inverter: a245 mech safe state pre warn";
CM_ SG_ 859 DIF_a246_recoveryAtSpeedError "Front drive inverter: a246 recovery at speed error";
CM_ SG_ 859 DIF_a247_rotorOffsetError "Front drive inverter: a247 rotor offset error";
CM_ SG_ 859 DIF_a249_highStatorTempFromResis "Front drive inverter: a249 high stator temp from resist";
CM_ SG_ 859 DIF_a250_preregulatorRail "Front drive inverter: a250 preregulator rail";
CM_ SG_ 859 DIF_a251_oilPumpService "Front drive inverter: a251 oil pump service";
CM_ SG_ 859 DIF_a252_currentCoreFallback "Front drive inverter: a252 current core fallback";
CM_ SG_ 859 DIF_a253_lvBoostedRail "Front drive inverter: a253 lv boosted rail";
CM_ SG_ 859 DIF_a254_activeDischargeRail "Front drive inverter: a254 active discharge rail";
CM_ SG_ 859 DIF_a255_currentGainFallback "Front drive inverter: a255 current gain fallback";
CM_ BO_ 935 "Rear drive inverter message: alert matrix1";
CM_ SG_ 935 DIR_a001_hwPhaseAgateDrive "Rear drive inverter: a001 hw phase agate drive";
CM_ SG_ 935 DIR_a002_hwPhaseBgateDrive "Rear drive inverter: a002 hw phase bgate drive";
CM_ SG_ 935 DIR_a003_hwPhaseCgateDrive "Rear drive inverter: a003 hw phase cgate drive";
CM_ SG_ 935 DIR_a004_hwPhaseApeak "Rear drive inverter: a004 hw phase apeak";
CM_ SG_ 935 DIR_a005_hwPhaseBpeak "Rear drive inverter: a005 hw phase bpeak";
CM_ SG_ 935 DIR_a006_hwPhaseCpeak "Rear drive inverter: a006 hw phase cpeak";
CM_ SG_ 935 DIR_a007_statorAnomalyDetected "Rear drive inverter: a007 stator anomaly detected";
CM_ SG_ 935 DIR_a008_hwEncoderA "Rear drive inverter: a008 hw encoder a";
CM_ SG_ 935 DIR_a009_hwEncoderB "Rear drive inverter: a009 hw encoder b";
CM_ SG_ 935 DIR_a010_unintendedReset "Rear drive inverter: a010 unintended reset";
CM_ SG_ 935 DIR_a011_swPowerStageNotReady "Rear drive inverter: a011 sw power stage not ready";
CM_ SG_ 935 DIR_a012_hvilNotClosed "Rear drive inverter: a012 hvil not closed";
CM_ SG_ 935 DIR_a013_eccError "Rear drive inverter: a013 ecc error";
CM_ SG_ 935 DIR_a014_activeDamping "Rear drive inverter: a014 active damping";
CM_ SG_ 935 DIR_a015_mechSafeStateAnomaly "Rear drive inverter: a015 mech safe state anomaly";
CM_ SG_ 935 DIR_a016_safeStateApplied "Rear drive inverter: a016 safe state applied";
CM_ SG_ 935 DIR_a017_hwPedalMonitor "Rear drive inverter: a017 hw pedal monitor";
CM_ SG_ 935 DIR_a018_hwLVSupplyUV "Rear drive inverter: a018 hw LV supply UV";
CM_ SG_ 935 DIR_a020_hwMotorEncoder "Rear drive inverter: a020 hw motor encoder";
CM_ SG_ 935 DIR_a021_hwBusOV "Rear drive inverter: a021 hw bus OV";
CM_ SG_ 935 DIR_a022_hw5vSupplyUV "Rear drive inverter: a022 hw5v supply UV";
CM_ SG_ 935 DIR_a024_selfTest "Rear drive inverter: a024 self test";
CM_ SG_ 935 DIR_a025_phaseApeak "Rear drive inverter: a025 phase apeak";
CM_ SG_ 935 DIR_a026_phaseBpeak "Rear drive inverter: a026 phase bpeak";
CM_ SG_ 935 DIR_a027_phaseCpeak "Rear drive inverter: a027 phase cpeak";
CM_ SG_ 935 DIR_a028_phaseArms "Rear drive inverter: a028 phase arms";
CM_ SG_ 935 DIR_a029_phaseBrms "Rear drive inverter: a029 phase brms";
CM_ SG_ 935 DIR_a030_phaseCrms "Rear drive inverter: a030 phase crms";
CM_ SG_ 935 DIR_a031_phaseAcurrentOffset "Rear drive inverter: a031 phase acurrent offset";
CM_ SG_ 935 DIR_a032_phaseBcurrentOffset "Rear drive inverter: a032 phase bcurrent offset";
CM_ SG_ 935 DIR_a033_phaseAcurrentSensor "Rear drive inverter: a033 phase acurrent sensor";
CM_ SG_ 935 DIR_a034_phaseBcurrentSensor "Rear drive inverter: a034 phase bcurrent sensor";
CM_ SG_ 935 DIR_a035_phaseCurrentBalance "Rear drive inverter: a035 phase current balance";
CM_ SG_ 935 DIR_a036_busOV "Rear drive inverter: a036 bus OV";
CM_ SG_ 935 DIR_a037_busUV "Rear drive inverter: a037 bus UV";
CM_ SG_ 935 DIR_a038_busVsensor "Rear drive inverter: a038 bus vsensor";
CM_ SG_ 935 DIR_a039_exceptionUndefinedInstr "Rear drive inverter: a039 exception undefined instruction";
CM_ SG_ 935 DIR_a040_difMIA "Rear drive inverter: a040 dif MIA";
CM_ SG_ 935 DIR_a041_sdcMIA "Rear drive inverter: a041 sdc MIA";
CM_ SG_ 935 DIR_a042_inletSensor "Rear drive inverter: a042 inlet sensor";
CM_ SG_ 935 DIR_a043_outletOT "Rear drive inverter: a043 outlet OT";
CM_ SG_ 935 DIR_a044_outletUT "Rear drive inverter: a044 outlet UT";
CM_ SG_ 935 DIR_a045_outletSensor "Rear drive inverter: a045 outlet sensor";
CM_ SG_ 935 DIR_a046_statorOT "Rear drive inverter: a046 stator OT";
CM_ SG_ 935 DIR_a047_statorSensor1 "Rear drive inverter: a047 stator sensor1";
CM_ SG_ 935 DIR_a048_statorSensor2 "Rear drive inverter: a048 stator sensor2";
CM_ SG_ 935 DIR_a049_statorSensorDiff "Rear drive inverter: a049 stator sensor diff";
CM_ SG_ 935 DIR_a050_noStatorSensor "Rear drive inverter: a050 no stator sensor";
CM_ SG_ 935 DIR_a052_dirMIA "Rear drive inverter: a052 dir MIA";
CM_ SG_ 935 DIR_a053_unexpectedLatchState "Rear drive inverter: a053 unexpected latch state";
CM_ SG_ 935 DIR_a054_driveInverterOT "Rear drive inverter: a054 drive inverter OT";
CM_ SG_ 935 DIR_a055_trqCrossCheck "Rear drive inverter: a055 trq cross check";
CM_ SG_ 935 DIR_a056_ambientOT "Rear drive inverter: a056 ambient OT";
CM_ SG_ 935 DIR_a057_ambientUT "Rear drive inverter: a057 ambient UT";
CM_ SG_ 935 DIR_a058_ambientSensor "Rear drive inverter: a058 ambient sensor";
CM_ SG_ 935 DIR_a059_heatsinkOT "Rear drive inverter: a059 heatsink OT";
CM_ SG_ 935 DIR_a060_heatsinkUT "Rear drive inverter: a060 heatsink UT";
CM_ SG_ 935 DIR_a061_heatsinkSensor "Rear drive inverter: a061 heatsink sensor";
CM_ SG_ 935 DIR_a062_systemLimpMode "Rear drive inverter: a062 system limp mode";
CM_ SG_ 935 DIR_a063_bbMIA "Rear drive inverter: a063 bb MIA";
CM_ SG_ 935 DIR_a064_torqueIntervention "Rear drive inverter: a064 torque intervention";
CM_ BO_ 949 "Rear drive inverter message: alert matrix2";
CM_ SG_ 949 DIR_a065_canHardwareBusB "Rear drive inverter: a065 can hardware bus b";
CM_ SG_ 949 DIR_a066_canDataBusB "Rear drive inverter: a066 can data bus b";
CM_ SG_ 949 DIR_a067_canOverrunBusB "Rear drive inverter: a067 can overrun bus b";
CM_ SG_ 949 DIR_a069_rotorTempLimit "Rear drive inverter: a069 rotor temp limit";
CM_ SG_ 949 DIR_a070_udsTransactionInitiated "Rear drive inverter: a070 uds transaction initiated";
CM_ SG_ 949 DIR_a071_busDisconnected "Rear drive inverter: a071 bus disconnected";
CM_ SG_ 949 DIR_a072_gateDriveFaultCounter "Rear drive inverter: a072 gate drive fault counter";
CM_ SG_ 949 DIR_a073_motorSpeed "Rear drive inverter: a073 motor speed";
CM_ SG_ 949 DIR_a074_motorEncoder "Rear drive inverter: a074 motor encoder";
CM_ SG_ 949 DIR_a075_motorSpeedMismatch "Rear drive inverter: a075 motor speed mismatch";
CM_ SG_ 949 DIR_a076_lvSupplyOV "Rear drive inverter: a076 lv supply OV";
CM_ SG_ 949 DIR_a077_lvSupplyUV "Rear drive inverter: a077 lv supply UV";
CM_ SG_ 949 DIR_a078_adcRefLow "Rear drive inverter: a078 adc ref low";
CM_ SG_ 949 DIR_a079_adcRefHigh "Rear drive inverter: a079 adc ref high";
CM_ SG_ 949 DIR_a080_adcInfo "Rear drive inverter: a080 adc info";
CM_ SG_ 949 DIR_a081_P0BFF_DIR_EM_CurrentHig "Rear drive inverter: a081 P0 BFF DIR EM current high";
CM_ SG_ 949 DIR_a082_P0F45_DIR_ECU_DemoTimer "Rear drive inverter: a082 P0 F45 DIR ECU demo timer";
CM_ SG_ 949 DIR_a083_P98B3_DIR_ECU_DemoWindo "Rear drive inverter: a083 P98 B3 DIR ECU demo window";
CM_ SG_ 949 DIR_a084_eccTestData0 "Rear drive inverter: a084 ecc test data0";
CM_ SG_ 949 DIR_a086_activeDischargeOn "Rear drive inverter: a086 active discharge on";
CM_ SG_ 949 DIR_a087_gtwMIA "Rear drive inverter: a087 gtw MIA";
CM_ SG_ 949 DIR_a088_uiMIA "Rear drive inverter: a088 ui MIA";
CM_ SG_ 949 DIR_a090_pmMIA "Rear drive inverter: a090 pm MIA";
CM_ SG_ 949 DIR_a091_espMIA "Rear drive inverter: a091 esp MIA";
CM_ SG_ 949 DIR_a092_bmsMIA "Rear drive inverter: a092 bms MIA";
CM_ SG_ 949 DIR_a093_canHardwareBusA "Rear drive inverter: a093 can hardware bus a";
CM_ SG_ 949 DIR_a094_canDataBusA "Rear drive inverter: a094 can data bus a";
CM_ SG_ 949 DIR_a095_canOverrunBusA "Rear drive inverter: a095 can overrun bus a";
CM_ SG_ 949 DIR_a096_memoryError "Rear drive inverter: a096 memory error";
CM_ SG_ 949 DIR_a097_eepromError "Rear drive inverter: a097 eeprom error";
CM_ SG_ 949 DIR_a098_intTimeTooLong "Rear drive inverter: a098 int time too long";
CM_ SG_ 949 DIR_a099_threadOverrun "Rear drive inverter: a099 thread overrun";
CM_ SG_ 949 DIR_a100_assertion "Rear drive inverter: a100 assertion";
CM_ SG_ 949 DIR_a101_eccTestData1 "Rear drive inverter: a101 ecc test data1";
CM_ SG_ 949 DIR_a102_exceptionPrefetchAbort "Rear drive inverter: a102 exception prefetch abort";
CM_ SG_ 949 DIR_a103_lowFlow "Rear drive inverter: a103 low flow";
CM_ SG_ 949 DIR_a107_fpgaError "Rear drive inverter: a107 fpga error";
CM_ SG_ 949 DIR_a108_stateTrans "Rear drive inverter: a108 state trans";
CM_ SG_ 949 DIR_a109_ahbWriteError "Rear drive inverter: a109 ahb write error";
CM_ SG_ 949 DIR_a110_brakeMIA "Rear drive inverter: a110 brake MIA";
CM_ SG_ 949 DIR_a111_badPhaseSensorCalib "Rear drive inverter: a111 bad phase sensor calib";
CM_ SG_ 949 DIR_a112_noPhaseCurrent "Rear drive inverter: a112 no phase current";
CM_ SG_ 949 DIR_a113_noFuncHeatsinkSensor "Rear drive inverter: a113 no func heatsink sensor";
CM_ SG_ 949 DIR_a114_exceptionDataAbort "Rear drive inverter: a114 exception data abort";
CM_ SG_ 949 DIR_a115_exceptionDataAbort2 "Rear drive inverter: a115 exception data abort2";
CM_ SG_ 949 DIR_a116_highSpeedWearCounter "Rear drive inverter: a116 high speed wear counter";
CM_ SG_ 949 DIR_a117_diMIA "Rear drive inverter: a117 di MIA";
CM_ SG_ 949 DIR_a119_hvpMIA "Rear drive inverter: a119 hvp MIA";
CM_ SG_ 949 DIR_a120_hvlinkMIA "Rear drive inverter: a120 hvlink MIA";
CM_ SG_ 949 DIR_a121_motorControlRegulation "Rear drive inverter: a121 motor control regulation";
CM_ SG_ 949 DIR_a122_highStackUsage "Rear drive inverter: a122 high stack usage";
CM_ SG_ 949 DIR_a123_lossMotorControl "Rear drive inverter: a123 loss motor control";
CM_ SG_ 949 DIR_a126_limpMode "Rear drive inverter: a126 limp mode";
CM_ SG_ 949 DIR_a127_gracefulPowerOff "Rear drive inverter: a127 graceful power off";
CM_ SG_ 949 DIR_a128_fpgaVersionMismatch "Rear drive inverter: a128 fpga version mismatch";
CM_ BO_ 965 "Rear drive inverter message: alert matrix3";
CM_ SG_ 965 DIR_a133_capacitorOT "Rear drive inverter: a133 capacitor OT";
CM_ SG_ 965 DIR_a134_wheelSpeedIrrational "Rear drive inverter: a134 wheel speed irrational";
CM_ SG_ 965 DIR_a136_spiError "Rear drive inverter: a136 spi error";
CM_ SG_ 965 DIR_a142_highLashAngle "Rear drive inverter: a142 high lash angle";
CM_ SG_ 965 DIR_a144_configMismatch "Rear drive inverter: a144 config mismatch";
CM_ SG_ 965 DIR_a147_highTorqueWearLimit "Rear drive inverter: a147 high torque wear limit";
CM_ SG_ 965 DIR_a148_burnInCycleEnded "Rear drive inverter: a148 burn in cycle ended";
CM_ SG_ 965 DIR_a149_oilPumpFailure "Rear drive inverter: a149 oil pump failure";
CM_ SG_ 965 DIR_a150_busVD "Rear drive inverter: a150 bus VD";
CM_ SG_ 965 DIR_a151_shockTorqueLimiter "Rear drive inverter: a151 shock torque limiter";
CM_ SG_ 965 DIR_a152_linError "Rear drive inverter: a152 lin error";
CM_ SG_ 965 DIR_a153_oilPumpDiagnostics "Rear drive inverter: a153 oil pump diagnostics";
CM_ SG_ 965 DIR_a154_resolver "Rear drive inverter: a154 resolver";
CM_ SG_ 965 DIR_a155_vcfrontMIA "Rear drive inverter: a155 vcfront MIA";
CM_ SG_ 965 DIR_a156_currentObserver "Rear drive inverter: a156 current observer";
CM_ SG_ 965 DIR_a157_rcmMIA "Rear drive inverter: a157 rcm MIA";
CM_ SG_ 965 DIR_a158_ibstMIA "Rear drive inverter: a158 ibst MIA";
CM_ SG_ 965 DIR_a160_busVoltageAnomaly "Rear drive inverter: a160 bus voltage anomaly";
CM_ SG_ 965 DIR_a161_epas3pMIA "Rear drive inverter: a161 epas3p MIA";
CM_ SG_ 965 DIR_a162_endOfLifetimeBurnIn "Rear drive inverter: a162 end of lifetime burn in";
CM_ SG_ 965 DIR_a174_unitMayNotRestart "Rear drive inverter: a174 unit may not restart";
CM_ SG_ 965 DIR_a176_safetyICFault "Rear drive inverter: a176 safety IC fault";
CM_ SG_ 965 DIR_a177_fluxReferenceCorrected "Rear drive inverter: a177 flux reference corrected";
CM_ SG_ 965 DIR_a178_spindownLearningBrakeAl "Rear drive inverter: a178 spindown learning brake allowed";
CM_ BO_ 997 "Rear drive inverter message: alert matrix4";
CM_ SG_ 997 DIR_a202_excessHeatUnavailable "Rear drive inverter: a202 excess heat unavailable";
CM_ SG_ 997 DIR_a225_tmpEstPlausibility "Rear drive inverter: a225 tmp est plausibility";
CM_ SG_ 997 DIR_a231_unintendedReset2 "Rear drive inverter: a231 unintended reset2";
CM_ SG_ 997 DIR_a233_diMsgMissed "Rear drive inverter: a233 di msg missed";
CM_ SG_ 997 DIR_a234_pcsMIA "Rear drive inverter: a234 pcs MIA";
CM_ SG_ 997 DIR_a236_tasMIA "Rear drive inverter: a236 tas MIA";
CM_ SG_ 997 DIR_a241_systemThermallyLimited "Rear drive inverter: a241 system thermally limited";
CM_ SG_ 997 DIR_a242_spinDownLearning "Rear drive inverter: a242 spin down learning";
CM_ SG_ 997 DIR_a243_ecuLogAvailable "Rear drive inverter: a243 ecu log available";
CM_ SG_ 997 DIR_a244_mechSafeStateApplied "Rear drive inverter: a244 mech safe state applied";
CM_ SG_ 997 DIR_a245_mechSafeStatePreWarn "Rear drive inverter: a245 mech safe state pre warn";
CM_ SG_ 997 DIR_a246_recoveryAtSpeedError "Rear drive inverter: a246 recovery at speed error";
CM_ SG_ 997 DIR_a247_rotorOffsetError "Rear drive inverter: a247 rotor offset error";
CM_ SG_ 997 DIR_a248_vehicleSpeedLimited "Rear drive inverter: a248 vehicle speed limited";
CM_ SG_ 997 DIR_a249_highStatorTempFromResis "Rear drive inverter: a249 high stator temp from resist";
CM_ SG_ 997 DIR_a250_preregulatorRail "Rear drive inverter: a250 preregulator rail";
CM_ SG_ 997 DIR_a251_oilPumpService "Rear drive inverter: a251 oil pump service";
CM_ SG_ 997 DIR_a252_currentCoreFallback "Rear drive inverter: a252 current core fallback";
CM_ SG_ 997 DIR_a253_lvBoostedRail "Rear drive inverter: a253 lv boosted rail";
CM_ SG_ 997 DIR_a254_activeDischargeRail "Rear drive inverter: a254 active discharge rail";
CM_ SG_ 997 DIR_a255_currentGainFallback "Rear drive inverter: a255 current gain fallback";
CM_ BO_ 871 "Drive inverter message: alert matrix1";
CM_ SG_ 871 DI_a001_frunkSpeedLimitActive "Drive inverter: a001 frunk speed limit active";
CM_ SG_ 871 DI_a002_parkButtonDuringStalkReq "Drive inverter: a002 park button during stalk req";
CM_ SG_ 871 DI_a003_suggestedGearOverride "Drive inverter: a003 suggested gear override";
CM_ SG_ 871 DI_a004_smartShiftUnavailable "Drive inverter: a004 smart shift unavailable";
CM_ SG_ 871 DI_a005_stalkPanicked "Drive inverter: a005 stalk panicked";
CM_ SG_ 871 DI_a006_shifterUnavailable "Drive inverter: a006 shifter unavailable";
CM_ SG_ 871 DI_a007_secGearSelButtonStuck "Drive inverter: a007 sec gear sel button stuck";
CM_ SG_ 871 DI_a010_unintendedReset "Drive inverter: a010 unintended reset";
CM_ SG_ 871 DI_a012_accel5VSupply "Drive inverter: a012 accel5 v supply";
CM_ SG_ 871 DI_a013_eccError "Drive inverter: a013 ecc error";
CM_ SG_ 871 DI_a014_secGearSelActivated "Drive inverter: a014 sec gear sel activated";
CM_ SG_ 871 DI_a015_immobilizer "Drive inverter: a015 immobilizer";
CM_ SG_ 871 DI_a016_parkRequestByPM "Drive inverter: a016 park request by PM";
CM_ SG_ 871 DI_a017_hwPedalMonitor "Drive inverter: a017 hw pedal monitor";
CM_ SG_ 871 DI_a018_hwLVSupplyUV "Drive inverter: a018 hw LV supply UV";
CM_ SG_ 871 DI_a019_hwAccelPedalPower "Drive inverter: a019 hw accel pedal power";
CM_ SG_ 871 DI_a020_systemHvilNotClosed "Drive inverter: a020 system hvil not closed";
CM_ SG_ 871 DI_a021_packOvervoltage "Drive inverter: a021 pack overvoltage";
CM_ SG_ 871 DI_a022_hw5vSupplyUV "Drive inverter: a022 hw5v supply UV";
CM_ SG_ 871 DI_a023_carNotParked "Drive inverter: a023 car not parked";
CM_ SG_ 871 DI_a024_holdNForNeutral "Drive inverter: a024 hold n for neutral";
CM_ SG_ 871 DI_a025_regenBackfillUnavailable "Drive inverter: a025 regen backfill unavailable";
CM_ SG_ 871 DI_a026_parkPressedWithHighAPeda "Drive inverter: a026 park pressed with high a pedal";
CM_ SG_ 871 DI_a031_closureAccelerationLimit "Drive inverter: a031 closure acceleration limit";
CM_ SG_ 871 DI_a036_sysStandbyUnitLimitedWai "Drive inverter: a036 sys standby unit limited wait";
CM_ SG_ 871 DI_a038_idleTaskStarving "Drive inverter: a038 idle task starving";
CM_ SG_ 871 DI_a039_exceptionUndefinedInstru "Drive inverter: a039 exception undefined instruction";
CM_ SG_ 871 DI_a040_difMIA "Drive inverter: a040 dif MIA";
CM_ SG_ 871 DI_a041_driverBrakeApplyStuck "Drive inverter: a041 driver brake apply stuck";
CM_ SG_ 871 DI_a042_pmfMIA "Drive inverter: a042 pmf MIA";
CM_ SG_ 871 DI_a043_pmrMIA "Drive inverter: a043 pmr MIA";
CM_ SG_ 871 DI_a048_ecuLogAvailable "Drive inverter: a048 ecu log available";
CM_ SG_ 871 DI_a049_P0632_DI_ECU_OdometerNot "Drive inverter: a049 P0632 DI ECU odometer not programmed";
CM_ SG_ 871 DI_a050_P1234_DI_ECU_DemoTimer "Drive inverter: a050 P1234 DI ECU demo timer";
CM_ SG_ 871 DI_a051_batteryOvercurrent "Drive inverter: a051 battery overcurrent";
CM_ SG_ 871 DI_a052_dirMIA "Drive inverter: a052 dir MIA";
CM_ SG_ 871 DI_a053_canDataBusC "Drive inverter: a053 can data bus c";
CM_ SG_ 871 DI_a054_canOverrunBusC "Drive inverter: a054 can overrun bus c";
CM_ SG_ 871 DI_a055_canHardwareBusC "Drive inverter: a055 can hardware bus c";
CM_ SG_ 871 DI_a056_canDataBusD "Drive inverter: a056 can data bus d";
CM_ SG_ 871 DI_a057_canOverrunBusD "Drive inverter: a057 can overrun bus d";
CM_ SG_ 871 DI_a058_canHardwareBusD "Drive inverter: a058 can hardware bus d";
CM_ SG_ 871 DI_a059_canDataBusE "Drive inverter: a059 can data bus e";
CM_ SG_ 871 DI_a060_canOverrunBusE "Drive inverter: a060 can overrun bus e";
CM_ SG_ 871 DI_a061_canHardwareBusE "Drive inverter: a061 can hardware bus e";
CM_ SG_ 871 DI_a062_systemLimpMode "Drive inverter: a062 system limp mode";
CM_ SG_ 871 DI_a063_systemGracefulPowerOff "Drive inverter: a063 system graceful power off";
CM_ SG_ 871 DI_a064_pmsrmUnitMiaWithHvDown "Drive inverter: a064 pmsrm unit mia with hv down";
CM_ BO_ 872 "Drive inverter message: alert matrix2";
CM_ SG_ 872 DI_a065_canHardwareBusB "Drive inverter: a065 can hardware bus b";
CM_ SG_ 872 DI_a066_canDataBusB "Drive inverter: a066 can data bus b";
CM_ SG_ 872 DI_a067_canOverrunBusB "Drive inverter: a067 can overrun bus b";
CM_ SG_ 872 DI_a068_secondaryWheelSpeedIrrat "Drive inverter: a068 secondary wheel speed irrational";
CM_ SG_ 872 DI_a069_P1234_DI_ECU_DemoWindow "Drive inverter: a069 P1234 DI ECU demo window";
CM_ SG_ 872 DI_a070_udsTransactionInitiated "Drive inverter: a070 uds transaction initiated";
CM_ SG_ 872 DI_a076_lvSupplyOV "Drive inverter: a076 lv supply OV";
CM_ SG_ 872 DI_a077_lvSupplyUV "Drive inverter: a077 lv supply UV";
CM_ SG_ 872 DI_a078_adcRefLow "Drive inverter: a078 adc ref low";
CM_ SG_ 872 DI_a079_adcRefHigh "Drive inverter: a079 adc ref high";
CM_ SG_ 872 DI_a080_accelSynch "Drive inverter: a080 accel synch";
CM_ SG_ 872 DI_a081_accelTrack1 "Drive inverter: a081 accel track1";
CM_ SG_ 872 DI_a082_accelTrack2 "Drive inverter: a082 accel track2";
CM_ SG_ 872 DI_a083_brakePedalSensor "Drive inverter: a083 brake pedal sensor";
CM_ SG_ 872 DI_a084_eccTestData0 "Drive inverter: a084 ecc test data0";
CM_ SG_ 872 DI_a085_proximityInEnable "Drive inverter: a085 proximity in enable";
CM_ SG_ 872 DI_a086_dpbMIA "Drive inverter: a086 dpb MIA";
CM_ SG_ 872 DI_a087_gtwMIA "Drive inverter: a087 gtw MIA";
CM_ SG_ 872 DI_a088_uiMIA "Drive inverter: a088 ui MIA";
CM_ SG_ 872 DI_a089_sccmMIA "Drive inverter: a089 sccm MIA";
CM_ SG_ 872 DI_a090_pmMIA "Drive inverter: a090 pm MIA";
CM_ SG_ 872 DI_a091_espMIA "Drive inverter: a091 esp MIA";
CM_ SG_ 872 DI_a092_bmsMIA "Drive inverter: a092 bms MIA";
CM_ SG_ 872 DI_a093_canHardwareBusA "Drive inverter: a093 can hardware bus a";
CM_ SG_ 872 DI_a094_canDataBusA "Drive inverter: a094 can data bus a";
CM_ SG_ 872 DI_a095_canOverrunBusA "Drive inverter: a095 can overrun bus a";
CM_ SG_ 872 DI_a096_memoryError "Drive inverter: a096 memory error";
CM_ SG_ 872 DI_a097_eepromError "Drive inverter: a097 eeprom error";
CM_ SG_ 872 DI_a098_eepromManagerError "Drive inverter: a098 eeprom manager error";
CM_ SG_ 872 DI_a099_threadOverrun "Drive inverter: a099 thread overrun";
CM_ SG_ 872 DI_a100_nvramError "Drive inverter: a100 nvram error";
CM_ SG_ 872 DI_a101_eccTestData1 "Drive inverter: a101 ecc test data1";
CM_ SG_ 872 DI_a102_exceptionPrefetchAbort "Drive inverter: a102 exception prefetch abort";
CM_ SG_ 872 DI_a103_bbMIA "Drive inverter: a103 bb MIA";
CM_ SG_ 872 DI_a104_proximityIrrational "Drive inverter: a104 proximity irrational";
CM_ SG_ 872 DI_a105_cpMIA "Drive inverter: a105 cp MIA";
CM_ SG_ 872 DI_a108_appMIA "Drive inverter: a108 app MIA";
CM_ SG_ 872 DI_a109_ahbWriteError "Drive inverter: a109 ahb write error";
CM_ SG_ 872 DI_a110_brakeMIA "Drive inverter: a110 brake MIA";
CM_ SG_ 872 DI_a112_accelTrack1Incons "Drive inverter: a112 accel track1 incons";
CM_ SG_ 872 DI_a114_exceptionDataAbort "Drive inverter: a114 exception data abort";
CM_ SG_ 872 DI_a115_exceptionDataAbort2 "Drive inverter: a115 exception data abort2";
CM_ SG_ 872 DI_a116_motorRecovered "Drive inverter: a116 motor recovered";
CM_ SG_ 872 DI_a117_latentFaultCheckTripped "Drive inverter: a117 latent fault check tripped";
CM_ SG_ 872 DI_a118_diImmobilizedForFactoryF "Drive inverter: a118 di immobilized for factory failsafe";
CM_ SG_ 872 DI_a119_latentFaultCheckFailedOn "Drive inverter: a119 latent fault check failed once";
CM_ SG_ 872 DI_a120_regenBlendingUnavailable "Drive inverter: a120 regen blending unavailable";
CM_ SG_ 872 DI_a121_qualifiedBrakeEventMitig "Drive inverter: a121 qualified brake event mitigation";
CM_ SG_ 872 DI_a122_highStackUsage "Drive inverter: a122 high stack usage";
CM_ SG_ 872 DI_a124_cruiseFault "Drive inverter: a124 cruise fault";
CM_ SG_ 872 DI_a125_noBatteryPower "Drive inverter: a125 no battery power";
CM_ BO_ 875 "Drive inverter message: alert matrix3";
CM_ SG_ 875 DI_a129_epbNotApplied "Drive inverter: a129 epb not applied";
CM_ SG_ 875 DI_a130_aebFault "Drive inverter: a130 aeb fault";
CM_ SG_ 875 DI_a131_highSpeedWearLimit "Drive inverter: a131 high speed wear limit";
CM_ SG_ 875 DI_a133_vehicleHoldTimedOut "Drive inverter: a133 vehicle hold timed out";
CM_ SG_ 875 DI_a134_wheelSpeedIrrational "Drive inverter: a134 wheel speed irrational";
CM_ SG_ 875 DI_a135_vehicleHoldFault "Drive inverter: a135 vehicle hold fault";
CM_ SG_ 875 DI_a137_noCapableDriveUnits "Drive inverter: a137 no capable drive units";
CM_ SG_ 875 DI_a138_frontUnitDisabled "Drive inverter: a138 front unit disabled";
CM_ SG_ 875 DI_a139_rearUnitDisabled "Drive inverter: a139 rear unit disabled";
CM_ SG_ 875 DI_a140_ptcMIA "Drive inverter: a140 ptc MIA";
CM_ SG_ 875 DI_a141_dasMIA "Drive inverter: a141 das MIA";
CM_ SG_ 875 DI_a142_potholeDetected "Drive inverter: a142 pothole detected";
CM_ SG_ 875 DI_a143_mcuLimitActive "Drive inverter: a143 mcu limit active";
CM_ SG_ 875 DI_a144_configMismatch "Drive inverter: a144 config mismatch";
CM_ SG_ 875 DI_a146_pbrkPanicEpbFault "Drive inverter: a146 pbrk panic epb fault";
CM_ SG_ 875 DI_a154_vdcRearSteering "Drive inverter: a154 vdc rear steering";
CM_ SG_ 875 DI_a155_vcfrontMIA "Drive inverter: a155 vcfront MIA";
CM_ SG_ 875 DI_a157_rcmMIA "Drive inverter: a157 rcm MIA";
CM_ SG_ 875 DI_a158_ibstMIA "Drive inverter: a158 ibst MIA";
CM_ SG_ 875 DI_a159_cruiseSelfCheck "Drive inverter: a159 cruise self check";
CM_ SG_ 875 DI_a160_fastLearnComplete "Drive inverter: a160 fast learn complete";
CM_ SG_ 875 DI_a161_epas3pMIA "Drive inverter: a161 epas3p MIA";
CM_ SG_ 875 DI_a162_shiftDenied "Drive inverter: a162 shift denied";
CM_ SG_ 875 DI_a163_shiftMotorSpeed "Drive inverter: a163 shift motor speed";
CM_ SG_ 875 DI_a164_brakeOverride "Drive inverter: a164 brake override";
CM_ SG_ 875 DI_a165_cruiseCancelled "Drive inverter: a165 cruise cancelled";
CM_ SG_ 875 DI_a166_driverLeft "Drive inverter: a166 driver left";
CM_ SG_ 875 DI_a167_keyNotAuthenticated "Drive inverter: a167 key not authenticated";
CM_ SG_ 875 DI_a168_proximityDriveDenial "Drive inverter: a168 proximity drive denial";
CM_ SG_ 875 DI_a169_regenOffOverride "Drive inverter: a169 regen off override";
CM_ SG_ 875 DI_a170_tireConfigUpdated "Drive inverter: a170 tire config updated";
CM_ SG_ 875 DI_a171_driveRailNotRequested "Drive inverter: a171 drive rail not requested";
CM_ SG_ 875 DI_a172_accelPressedInNP "Drive inverter: a172 accel pressed in NP";
CM_ SG_ 875 DI_a173_bothPedalsPressed "Drive inverter: a173 both pedals pressed";
CM_ SG_ 875 DI_a174_notOkToStartDrive "Drive inverter: a174 not ok to start drive";
CM_ SG_ 875 DI_a175_crsNotAvailable "Drive inverter: a175 crs not available";
CM_ SG_ 875 DI_a176_EBRreleased "Drive inverter: a176 EB rreleased";
CM_ SG_ 875 DI_a177_tireFitmentChanged "Drive inverter: a177 tire fitment changed";
CM_ SG_ 875 DI_a178_steeringAngleOffsetFault "Drive inverter: a178 steering angle offset fault";
CM_ SG_ 875 DI_a179_steeringAngleOffsetWarni "Drive inverter: a179 steering angle offset warning";
CM_ SG_ 875 DI_a180_crsSeatbeltUnbuckled "Drive inverter: a180 crs seatbelt unbuckled";
CM_ SG_ 875 DI_a181_rearMotorMode "Drive inverter: a181 rear motor mode";
CM_ SG_ 875 DI_a182_frontMotorMode "Drive inverter: a182 front motor mode";
CM_ SG_ 875 DI_a183_holdReleaseRqrd "Drive inverter: a183 hold release rqrd";
CM_ SG_ 875 DI_a184_autoparkCanceled "Drive inverter: a184 autopark canceled";
CM_ SG_ 875 DI_a185_autoparkAborted "Drive inverter: a185 autopark aborted";
CM_ SG_ 875 DI_a186_brakeStand "Drive inverter: a186 brake stand";
CM_ SG_ 875 DI_a187_pedalMisapplication "Drive inverter: a187 pedal misapplication";
CM_ SG_ 875 DI_a188_tireRotationRecommendedG "Drive inverter: a188 tire rotation recommended ghosted";
CM_ SG_ 875 DI_a189_garageShiftWithPedal "Drive inverter: a189 garage shift with pedal";
CM_ SG_ 875 DI_a190_tireRotationRecommended "Drive inverter: a190 tire rotation recommended";
CM_ SG_ 875 DI_a191_brakeShiftReq "Drive inverter: a191 brake shift req";
CM_ SG_ 875 DI_a192_invalidOdometer "Drive inverter: a192 invalid odometer";
CM_ BO_ 878 "Drive inverter message: alert matrix4";
CM_ SG_ 878 DI_a193_vdcBrakeTorqueFr "Drive inverter: a193 vdc brake torque fr";
CM_ SG_ 878 DI_a194_vdcBrakeTorqueRe "Drive inverter: a194 vdc brake torque re";
CM_ SG_ 878 DI_a195_vdcEspSlipFr "Drive inverter: a195 vdc esp slip fr";
CM_ SG_ 878 DI_a196_vdcEspSlipRe "Drive inverter: a196 vdc esp slip re";
CM_ SG_ 878 DI_a197_vdcEspWheelSaturations "Drive inverter: a197 vdc esp wheel saturations";
CM_ SG_ 878 DI_a198_vdcEspMCPressAndSteering "Drive inverter: a198 vdc esp MC press and steering";
CM_ SG_ 878 DI_a199_vdcFaulted "Drive inverter: a199 vdc faulted";
CM_ SG_ 878 DI_a200_vdcModelBasedPlausibilit "Drive inverter: a200 vdc model based plausibility";
CM_ SG_ 878 DI_a201_decelTorqueLimited "Drive inverter: a201 decel torque limited";
CM_ SG_ 878 DI_a202_excessHeatUnavailable "Drive inverter: a202 excess heat unavailable";
CM_ SG_ 878 DI_a203_TCReducedByADD "Drive inverter: a203 TC reduced by ADD";
CM_ SG_ 878 DI_a204_vdcRcmLongitudinal "Drive inverter: a204 vdc rcm longitudinal";
CM_ SG_ 878 DI_a205_vdcRcmLateral "Drive inverter: a205 vdc rcm lateral";
CM_ SG_ 878 DI_a206_vdcRcmVertical "Drive inverter: a206 vdc rcm vertical";
CM_ SG_ 878 DI_a207_vdcPowertrainTorque_dif "Drive inverter: a207 vdc powertrain torque dif";
CM_ SG_ 878 DI_a208_vdcPowertrainTorque_dir "Drive inverter: a208 vdc powertrain torque dir";
CM_ SG_ 878 DI_a210_vdcOtherControllerStates "Drive inverter: a210 vdc other controller states";
CM_ SG_ 878 DI_a211_vdcMotorSpeed_dif "Drive inverter: a211 vdc motor speed dif";
CM_ SG_ 878 DI_a212_vdcWheelRotations "Drive inverter: a212 vdc wheel rotations";
CM_ SG_ 878 DI_a213_lowMuProbabilityChange "Drive inverter: a213 low mu probability change";
CM_ SG_ 878 DI_a214_vdcWheelSpeedFr "Drive inverter: a214 vdc wheel speed fr";
CM_ SG_ 878 DI_a215_vdcWheelSpeedRe "Drive inverter: a215 vdc wheel speed re";
CM_ SG_ 878 DI_a216_vdcMBPAlmostTripped "Drive inverter: a216 vdc MBP almost tripped";
CM_ SG_ 878 DI_a217_vdcOutputIrrational "Drive inverter: a217 vdc output irrational";
CM_ SG_ 878 DI_a218_vdcOSPreControlActive "Drive inverter: a218 vdc OS pre control active";
CM_ SG_ 878 DI_a219_vdcOversteerdMzActive "Drive inverter: a219 vdc oversteerd mz active";
CM_ SG_ 878 DI_a220_vdcUndersteerDecelActive "Drive inverter: a220 vdc understeer decel active";
CM_ SG_ 878 DI_a221_vdcUndersteerdMzActive "Drive inverter: a221 vdc understeerd mz active";
CM_ SG_ 878 DI_a222_vdcDisabled "Drive inverter: a222 vdc disabled";
CM_ SG_ 878 DI_a223_tractionControlDisabled "Drive inverter: a223 traction control disabled";
CM_ SG_ 878 DI_a224_brakeOverTemp "Drive inverter: a224 brake over temp";
CM_ SG_ 878 DI_a225_vyEstimatorDegradedDebug "Drive inverter: a225 vy estimator degraded debug";
CM_ SG_ 878 DI_a226_sysStartConditionNotMet "Drive inverter: a226 sys start condition not met";
CM_ SG_ 878 DI_a227_contactorsNotClosed "Drive inverter: a227 contactors not closed";
CM_ SG_ 878 DI_a228_brakeTempEstUnavailable "Drive inverter: a228 brake temp est unavailable";
CM_ SG_ 878 DI_a230_cmpMIA "Drive inverter: a230 cmp MIA";
CM_ SG_ 878 DI_a231_unintendedReset2 "Drive inverter: a231 unintended reset2";
CM_ SG_ 878 DI_a232_velocityEstimatorDegrade "Drive inverter: a232 velocity estimator degraded";
CM_ SG_ 878 DI_a233_frontWheelImpactDetected "Drive inverter: a233 front wheel impact detected";
CM_ SG_ 878 DI_a235_trackModeActive "Drive inverter: a235 track mode active";
CM_ SG_ 878 DI_a236_tasMIA "Drive inverter: a236 tas MIA";
CM_ SG_ 878 DI_a237_undersideAbuse "Drive inverter: a237 underside abuse";
CM_ SG_ 878 DI_a238_secondaryCollisionMitiga "Drive inverter: a238 secondary collision mitigation active";
CM_ SG_ 878 DI_a239_neutralRequestByPM "Drive inverter: a239 neutral request by PM";
CM_ SG_ 878 DI_a240_torqueSplitStuck "Drive inverter: a240 torque split stuck";
CM_ SG_ 878 DI_a241_vdcMotorSpeed_dir "Drive inverter: a241 vdc motor speed dir";
CM_ SG_ 878 DI_a242_vdcTrailerSwayDetected "Drive inverter: a242 vdc trailer sway detected";
CM_ SG_ 878 DI_a243_rcuMIA "Drive inverter: a243 rcu MIA";
CM_ SG_ 878 DI_a244_vseRLSMassMismatch "Drive inverter: a244 vse RLS mass mismatch";
CM_ SG_ 878 DI_a245_opdReducedWithoutEbr "Drive inverter: a245 opd reduced without ebr";
CM_ SG_ 878 DI_a246_opdUnavailable "Drive inverter: a246 opd unavailable";
CM_ SG_ 878 DI_a248_vdcPreControlHighDynamic "Drive inverter: a248 vdc pre control high dynamic active";
CM_ SG_ 878 DI_a249_spinDownLearningInProgre "Drive inverter: a249 spin down learning in progress";
CM_ SG_ 878 DI_a250_tasSpeedLimitActive "Drive inverter: a250 tas speed limit active";
CM_ SG_ 878 DI_a251_diPowerOnStateMismatch "Drive inverter: a251 di power on state mismatch";
CM_ SG_ 878 DI_a253_accelSynchWarn "Drive inverter: a253 accel synch warn";
CM_ SG_ 878 DI_a254_vehicleStuckDetected "Drive inverter: a254 vehicle stuck detected";
BA_DEF_ "BusType" STRING;
BA_DEF_ "DBName" STRING;
BA_DEF_ "Baudrate" INT 0 1000000;
BA_DEF_ "BaudrateCANFD" INT 0 16000000;
BA_DEF_ "Manufacturer" STRING;
BA_DEF_ "FirmwareVersion" STRING;
BA_DEF_ "VehicleModel" STRING;
BA_DEF_ BU_ "ECU" STRING;
BA_DEF_ BO_ "GenMsgCycleTime" INT 0 3600000;
BA_DEF_ BO_ "GenMsgSendType" ENUM "Cyclic","NotUsed","NotUsed","NotUsed","NotUsed","NotUsed","NotUsed","IfActive","NoMsgSendType","NotUsed";
BA_DEF_ BO_ "VFrameFormat" ENUM "StandardCAN","ExtendedCAN","reserved","J1939PG","reserved","reserved","reserved","reserved","reserved","reserved","reserved","reserved","reserved","reserved","StandardCAN_FD","ExtendedCAN_FD";
BA_DEF_ BO_ "CANFD_BRS" ENUM "0","1";
BA_DEF_ SG_ "GenSigSNA" STRING;
BA_DEF_ SG_ "SystemSignalLongSymbol" STRING;
BA_DEF_ SG_ "Confidence" ENUM "validated","plausible","layout-only","contradicted";
BA_DEF_DEF_ "BusType" "CAN";
BA_DEF_DEF_ "DBName" "";
BA_DEF_DEF_ "Baudrate" 500000;
BA_DEF_DEF_ "BaudrateCANFD" 2000000;
BA_DEF_DEF_ "Manufacturer" "";
BA_DEF_DEF_ "FirmwareVersion" "";
BA_DEF_DEF_ "VehicleModel" "";
BA_DEF_DEF_ "ECU" "";
BA_DEF_DEF_ "GenMsgCycleTime" 0;
BA_DEF_DEF_ "GenMsgSendType" "NoMsgSendType";
BA_DEF_DEF_ "VFrameFormat" "StandardCAN";
BA_DEF_DEF_ "CANFD_BRS" "1";
BA_DEF_DEF_ "GenSigSNA" "";
BA_DEF_DEF_ "SystemSignalLongSymbol" "";
BA_DEF_DEF_ "Confidence" "layout-only";
BA_ "DBName" "AllModels_ETH";
BA_ "Manufacturer" "Tesla";
BA_ "FirmwareVersion" "2025.20.8";
BA_ "VehicleModel" "Model 3 / Model Y";
BA_ "ECU" BU_ ADSP "ADSP";
BA_ "ECU" BU_ APSB "APSB";
BA_ "ECU" BU_ BB "BB";
BA_ "ECU" BU_ BMS "BMS";
BA_ "ECU" BU_ CMP "CMP";
BA_ "ECU" BU_ CP "CP";
BA_ "ECU" BU_ DAS "DAS";
BA_ "ECU" BU_ DI "DI";
BA_ "ECU" BU_ DIF "DIF";
BA_ "ECU" BU_ DIR "DIR";
BA_ "ECU" BU_ DPB "DPB";
BA_ "ECU" BU_ EPASTP "EPASTP";
BA_ "ECU" BU_ EPASTS "EPASTS";
BA_ "ECU" BU_ GTW "GTW";
BA_ "ECU" BU_ ICR "ICR";
BA_ "ECU" BU_ IDB "IDB";
BA_ "ECU" BU_ OCS1P "OCS1P";
BA_ "ECU" BU_ PM "PM";
BA_ "ECU" BU_ PMF "PMF";
BA_ "ECU" BU_ PMR "PMR";
BA_ "ECU" BU_ PTC "PTC";
BA_ "ECU" BU_ RCM "RCM";
BA_ "ECU" BU_ RCU "RCU";
BA_ "ECU" BU_ TCU "TCU";
BA_ "ECU" BU_ UI "UI";
BA_ "ECU" BU_ UIS "UIS";
BA_ "ECU" BU_ VCLEFT "VCLEFT";
BA_ "ECU" BU_ VCSEC "VCSEC";
BA_ "GenMsgCycleTime" BO_ 1361 1000;
BA_ "GenMsgSendType" BO_ 1361 0;
BA_ "GenMsgCycleTime" BO_ 1362 1000;
BA_ "GenMsgSendType" BO_ 1362 0;
BA_ "GenMsgCycleTime" BO_ 992 100;
BA_ "GenMsgSendType" BO_ 992 0;
BA_ "GenMsgCycleTime" BO_ 1864 100;
BA_ "GenMsgSendType" BO_ 1864 0;
BA_ "GenMsgCycleTime" BO_ 971 500;
BA_ "GenMsgSendType" BO_ 971 0;
BA_ "GenMsgCycleTime" BO_ 943 10;
BA_ "GenMsgSendType" BO_ 943 0;
BA_ "GenMsgCycleTime" BO_ 2029 100;
BA_ "GenMsgSendType" BO_ 2029 0;
BA_ "GenMsgCycleTime" BO_ 2028 1000;
BA_ "GenMsgSendType" BO_ 2028 0;
BA_ "GenMsgCycleTime" BO_ 551 100;
BA_ "GenMsgSendType" BO_ 551 0;
BA_ "GenMsgCycleTime" BO_ 1085 100;
BA_ "GenMsgSendType" BO_ 1085 0;
BA_ "GenMsgCycleTime" BO_ 777 30;
BA_ "GenMsgSendType" BO_ 777 0;
BA_ "GenMsgCycleTime" BO_ 1548 5;
BA_ "GenMsgSendType" BO_ 1548 0;
BA_ "GenMsgCycleTime" BO_ 854 1000;
BA_ "GenMsgSendType" BO_ 854 0;
BA_ "GenMsgCycleTime" BO_ 855 1000;
BA_ "GenMsgSendType" BO_ 855 0;
BA_ "GenMsgCycleTime" BO_ 858 1000;
BA_ "GenMsgSendType" BO_ 858 0;
BA_ "GenMsgCycleTime" BO_ 859 1000;
BA_ "GenMsgSendType" BO_ 859 0;
BA_ "GenMsgCycleTime" BO_ 935 1000;
BA_ "GenMsgSendType" BO_ 935 0;
BA_ "GenMsgCycleTime" BO_ 949 1000;
BA_ "GenMsgSendType" BO_ 949 0;
BA_ "GenMsgCycleTime" BO_ 965 1000;
BA_ "GenMsgSendType" BO_ 965 0;
BA_ "GenMsgCycleTime" BO_ 997 1000;
BA_ "GenMsgSendType" BO_ 997 0;
BA_ "GenMsgCycleTime" BO_ 871 1000;
BA_ "GenMsgSendType" BO_ 871 0;
BA_ "GenMsgCycleTime" BO_ 872 1000;
BA_ "GenMsgSendType" BO_ 872 0;
BA_ "GenMsgCycleTime" BO_ 875 1000;
BA_ "GenMsgSendType" BO_ 875 0;
BA_ "GenMsgCycleTime" BO_ 878 1000;
BA_ "GenMsgSendType" BO_ 878 0;
BA_ "Confidence" SG_ 1360 ADSP_alertID 1;
BA_ "Confidence" SG_ 1360 ADSP_alertState 1;
BA_ "Confidence" SG_ 1360 ADSP_a035_a2baIntrType 1;
BA_ "Confidence" SG_ 1360 ADSP_a035_a2baFaultType 1;
BA_ "Confidence" SG_ 1360 ADSP_a036_a2bbIntrType 1;
BA_ "Confidence" SG_ 1360 ADSP_a036_a2bbFaultType 1;
BA_ "Confidence" SG_ 1360 ADSP_a053_audioSystemUnavailable 1;
BA_ "Confidence" SG_ 1360 ADSP_a067_baseamp0Fault 1;
BA_ "Confidence" SG_ 1360 ADSP_a068_baseamp1Fault 1;
BA_ "Confidence" SG_ 1360 ADSP_a069_baseamp2Fault 1;
BA_ "Confidence" SG_ 1360 ADSP_a070_baseamp3Fault 1;
BA_ "Confidence" SG_ 1360 ADSP_a071_versionMismatch 1;
BA_ "SystemSignalLongSymbol" SG_ 1362 ADSP_w065_tcuGpioExpanderCritica "ADSP_w065_tcuGpioExpanderCriticalError";
BA_ "SystemSignalLongSymbol" SG_ 1362 ADSP_w072_turnSignalChannelUnder "ADSP_w072_turnSignalChannelUnderrun";
BA_ "SystemSignalLongSymbol" SG_ 1362 ADSP_w076_activeSafetyChannelUnd "ADSP_w076_activeSafetyChannelUnderrun";
BA_ "Confidence" SG_ 992 APSB_A_lowPowerRequest 0;
BA_ "Confidence" SG_ 992 APSB_A_lowPowerRequestor 0;
BA_ "Confidence" SG_ 992 APSB_A_forcePowerOffRequest 0;
BA_ "Confidence" SG_ 992 APSB_B_lowPowerRequest 0;
BA_ "Confidence" SG_ 992 APSB_B_lowPowerRequestor 0;
BA_ "Confidence" SG_ 992 APSB_B_forcePowerOffRequest 0;
BA_ "Confidence" SG_ 1864 APSB_primaryTurbo 0;
BA_ "Confidence" SG_ 1864 APSB_A_arbState 0;
BA_ "Confidence" SG_ 1864 APSB_A_powerState 0;
BA_ "Confidence" SG_ 1864 APSB_A_sleepState 0;
BA_ "Confidence" SG_ 1864 APSB_A_resetState 0;
BA_ "Confidence" SG_ 1864 APSB_A_faultState 0;
BA_ "Confidence" SG_ 1864 APSB_secondaryTurbo 0;
BA_ "Confidence" SG_ 1864 APSB_B_arbState 0;
BA_ "Confidence" SG_ 1864 APSB_B_powerState 0;
BA_ "Confidence" SG_ 1864 APSB_B_sleepState 0;
BA_ "Confidence" SG_ 1864 APSB_B_resetState 0;
BA_ "Confidence" SG_ 1864 APSB_B_faultState 0;
BA_ "Confidence" SG_ 971 APSB_appStatusMonitorState 0;
BA_ "Confidence" SG_ 971 APSB_vehBehaviorState 0;
BA_ "Confidence" SG_ 971 APSB_canMaster 0;
BA_ "GenSigSNA" SG_ 971 APSB_canMaster "3";
BA_ "Confidence" SG_ 971 APSB_appGpioState 0;
BA_ "Confidence" SG_ 971 APSB_eacInternalState 0;
BA_ "Confidence" SG_ 971 APSB_switchState 0;
BA_ "Confidence" SG_ 971 APSB_apbStatusMonitorState 0;
BA_ "Confidence" SG_ 971 APSB_apbGpioState 0;
BA_ "Confidence" SG_ 971 APSB_statusCounter 0;
BA_ "Confidence" SG_ 971 APSB_locLimitReason 0;
BA_ "Confidence" SG_ 971 APSB_appPowerStateRequest 0;
BA_ "Confidence" SG_ 971 APSB_appPowerStateReason 0;
BA_ "Confidence" SG_ 971 APSB_apbPowerStateRequest 0;
BA_ "Confidence" SG_ 971 APSB_apbPowerStateReason 0;
BA_ "Confidence" SG_ 971 APSB_heaterStateDebug 0;
BA_ "GenSigSNA" SG_ 971 APSB_heaterStateDebug "7";
BA_ "Confidence" SG_ 971 APSB_autosummonCounter 0;
BA_ "Confidence" SG_ 971 APSB_autosummonAlert 0;
BA_ "Confidence" SG_ 971 APSB_gpsAntennaState 0;
BA_ "Confidence" SG_ 971 APSB_arbState 0;
BA_ "Confidence" SG_ 971 APSB_socPowerOperatingMode 0;
BA_ "Confidence" SG_ 943 BB_statusChecksum 0;
BA_ "Confidence" SG_ 943 BB_statusCounter 0;
BA_ "Confidence" SG_ 943 BB_sOutputRod 0;
BA_ "Confidence" SG_ 943 BB_sOutputRodQF 0;
BA_ "Confidence" SG_ 943 BB_sInputRod 0;
BA_ "Confidence" SG_ 943 BB_sInputRodQF 0;
BA_ "Confidence" SG_ 943 BB_driverBrakeApply 0;
BA_ "Confidence" SG_ 943 BB_driverBrakeApplyQF 0;
BA_ "Confidence" SG_ 943 BB_boosterStatus 0;
BA_ "Confidence" SG_ 943 BB_warningLampRequest 0;
BA_ "Confidence" SG_ 943 BB_brakeFluidLevel 0;
BA_ "Confidence" SG_ 943 BB_internalState 0;
BA_ "Confidence" SG_ 2029 BMS_10HzDebug_Id 1;
BA_ "Confidence" SG_ 2029 BMS_activeCoolCellTargetT 1;
BA_ "Confidence" SG_ 2029 BMS_passiveCoolCellTargetT 1;
BA_ "Confidence" SG_ 2028 BMS_coldStagnationLimit 1;
BA_ "Confidence" SG_ 2028 BMS_hotStagnationLimit 1;
BA_ "Confidence" SG_ 2028 BMS_hotCellTempLimit 1;
BA_ "Confidence" SG_ 2028 BMS_activeCoolCellReferenceT 1;
BA_ "Confidence" SG_ 2028 BMS_activeHeatCellTargetT 1;
BA_ "Confidence" SG_ 2028 BMS_cellTempTargetMode 1;
BA_ "Confidence" SG_ 2028 BMS_requestDischarge 1;
BA_ "Confidence" SG_ 551 CMP_inputHVVoltage 0;
BA_ "Confidence" SG_ 551 CMP_inputLVVoltage 0;
BA_ "Confidence" SG_ 551 CMP_inputHVCurrent 0;
BA_ "Confidence" SG_ 551 CMP_inputHVPower 0;
BA_ "Confidence" SG_ 1085 CP_hvChargeStatus_log 1;
BA_ "Confidence" SG_ 1085 CP_chargeShutdownRequest_log 1;
BA_ "Confidence" SG_ 1085 CP_acChargeCurrentLimit_log 1;
BA_ "Confidence" SG_ 1085 CP_internalMaxDcCurrentLimit_log 1;
BA_ "Confidence" SG_ 1085 CP_internalMaxAcCurrentLimit_log 1;
BA_ "Confidence" SG_ 1085 CP_evseChargeType_log 1;
BA_ "Confidence" SG_ 1085 CP_chgLimitMode_log 1;
BA_ "Confidence" SG_ 777 DAS_objectId 1;
BA_ "Confidence" SG_ 777 DAS_leadVehType 0;
BA_ "Confidence" SG_ 777 DAS_leadVehRelevantForControl 0;
BA_ "Confidence" SG_ 777 DAS_leadVehDx 0;
BA_ "GenSigSNA" SG_ 777 DAS_leadVehDx "255";
BA_ "Confidence" SG_ 777 DAS_leadVehVxRel 0;
BA_ "GenSigSNA" SG_ 777 DAS_leadVehVxRel "15";
BA_ "Confidence" SG_ 777 DAS_leadVehDy 0;
BA_ "Confidence" SG_ 777 DAS_leadVehId 0;
BA_ "GenSigSNA" SG_ 777 DAS_leadVehId "127";
BA_ "Confidence" SG_ 777 DAS_leadVeh2Type 0;
BA_ "Confidence" SG_ 777 DAS_leadVeh2RelevantForControl 0;
BA_ "Confidence" SG_ 777 DAS_leadVeh2Dx 0;
BA_ "GenSigSNA" SG_ 777 DAS_leadVeh2Dx "255";
BA_ "Confidence" SG_ 777 DAS_leadVeh2VxRel 0;
BA_ "GenSigSNA" SG_ 777 DAS_leadVeh2VxRel "15";
BA_ "Confidence" SG_ 777 DAS_leadVeh2Dy 0;
BA_ "Confidence" SG_ 777 DAS_leadVeh2Id 0;
BA_ "GenSigSNA" SG_ 777 DAS_leadVeh2Id "0";
BA_ "Confidence" SG_ 777 DAS_leftVehType 0;
BA_ "Confidence" SG_ 777 DAS_leftVehRelevantForControl 0;
BA_ "Confidence" SG_ 777 DAS_leftVehDx 0;
BA_ "GenSigSNA" SG_ 777 DAS_leftVehDx "255";
BA_ "Confidence" SG_ 777 DAS_leftVehVxRel 0;
BA_ "GenSigSNA" SG_ 777 DAS_leftVehVxRel "15";
BA_ "Confidence" SG_ 777 DAS_leftVehDy 0;
BA_ "Confidence" SG_ 777 DAS_leftVehId 0;
BA_ "GenSigSNA" SG_ 777 DAS_leftVehId "127";
BA_ "Confidence" SG_ 777 DAS_leftVeh2Type 0;
BA_ "Confidence" SG_ 777 DAS_leftVeh2RelevantForControl 0;
BA_ "Confidence" SG_ 777 DAS_leftVeh2Dx 0;
BA_ "GenSigSNA" SG_ 777 DAS_leftVeh2Dx "255";
BA_ "Confidence" SG_ 777 DAS_leftVeh2VxRel 0;
BA_ "GenSigSNA" SG_ 777 DAS_leftVeh2VxRel "15";
BA_ "Confidence" SG_ 777 DAS_leftVeh2Dy 0;
BA_ "Confidence" SG_ 777 DAS_leftVeh2Id 0;
BA_ "GenSigSNA" SG_ 777 DAS_leftVeh2Id "0";
BA_ "Confidence" SG_ 777 DAS_rightVehType 0;
BA_ "Confidence" SG_ 777 DAS_rightVehRelevantForControl 0;
BA_ "Confidence" SG_ 777 DAS_rightVehDx 0;
BA_ "GenSigSNA" SG_ 777 DAS_rightVehDx "255";
BA_ "Confidence" SG_ 777 DAS_rightVehVxRel 0;
BA_ "GenSigSNA" SG_ 777 DAS_rightVehVxRel "15";
BA_ "Confidence" SG_ 777 DAS_rightVehDy 0;
BA_ "Confidence" SG_ 777 DAS_rightVehId 0;
BA_ "GenSigSNA" SG_ 777 DAS_rightVehId "127";
BA_ "Confidence" SG_ 777 DAS_rightVeh2Type 0;
BA_ "Confidence" SG_ 777 DAS_rightVeh2RelevantForControl 0;
BA_ "Confidence" SG_ 777 DAS_rightVeh2Dx 0;
BA_ "GenSigSNA" SG_ 777 DAS_rightVeh2Dx "255";
BA_ "Confidence" SG_ 777 DAS_rightVeh2VxRel 0;
BA_ "GenSigSNA" SG_ 777 DAS_rightVeh2VxRel "15";
BA_ "Confidence" SG_ 777 DAS_rightVeh2Dy 0;
BA_ "Confidence" SG_ 777 DAS_rightVeh2Id 0;
BA_ "GenSigSNA" SG_ 777 DAS_rightVeh2Id "0";
BA_ "Confidence" SG_ 777 DAS_cutinVehType 0;
BA_ "Confidence" SG_ 777 DAS_cutinVehRelevantForControl 0;
BA_ "Confidence" SG_ 777 DAS_cutinVehDx 0;
BA_ "GenSigSNA" SG_ 777 DAS_cutinVehDx "255";
BA_ "Confidence" SG_ 777 DAS_cutinVehVxRel 0;
BA_ "GenSigSNA" SG_ 777 DAS_cutinVehVxRel "15";
BA_ "Confidence" SG_ 777 DAS_cutinVehDy 0;
BA_ "Confidence" SG_ 777 DAS_cutinVehId 0;
BA_ "GenSigSNA" SG_ 777 DAS_cutinVehId "127";
BA_ "Confidence" SG_ 777 DAS_roadSignColor 0;
BA_ "Confidence" SG_ 777 DAS_roadSignId 0;
BA_ "GenSigSNA" SG_ 777 DAS_roadSignId "255";
BA_ "Confidence" SG_ 777 DAS_roadSignStopLineDist 0;
BA_ "GenSigSNA" SG_ 777 DAS_roadSignStopLineDist "1023";
BA_ "Confidence" SG_ 777 DAS_roadSignControlActive 0;
BA_ "Confidence" SG_ 777 DAS_roadSignSource 0;
BA_ "Confidence" SG_ 777 DAS_roadSignArrow 0;
BA_ "Confidence" SG_ 777 DAS_roadSignOrientation 0;
BA_ "Confidence" SG_ 1548 DAS_TR_ObjIndex 1;
BA_ "Confidence" SG_ 1548 DAS_TR_Counter 0;
BA_ "Confidence" SG_ 1548 DAS_TR_Obj00_Class 0;
BA_ "Confidence" SG_ 1548 DAS_TR_Obj00_Dx 0;
BA_ "Confidence" SG_ 1548 DAS_TR_Obj00_Dy 0;
BA_ "Confidence" SG_ 1548 DAS_TR_Obj00_Vx 0;
BA_ "Confidence" SG_ 1548 DAS_TR_Obj00_RCS 0;
BA_ "Confidence" SG_ 1548 DAS_TR_Obj00_Length 0;
BA_ "Confidence" SG_ 1548 DAS_TR_Obj00_MovingState 0;
BA_ "Confidence" SG_ 1548 DAS_TR_Obj00_Dz 0;
BA_ "Confidence" SG_ 1548 DAS_TR_Obj00_Exist 0;
BA_ "SystemSignalLongSymbol" SG_ 854 DIF_a039_exceptionUndefinedInstr "DIF_a039_exceptionUndefinedInstruction";
BA_ "SystemSignalLongSymbol" SG_ 855 DIF_a081_P0BFF_DIF_EM_CurrentHig "DIF_a081_P0BFF_DIF_EM_CurrentHigh";
BA_ "SystemSignalLongSymbol" SG_ 855 DIF_a083_PABCD_DIF_ECU_DemoWindo "DIF_a083_PABCD_DIF_ECU_DemoWindow";
BA_ "SystemSignalLongSymbol" SG_ 859 DIF_a249_highStatorTempFromResis "DIF_a249_highStatorTempFromResist";
BA_ "SystemSignalLongSymbol" SG_ 935 DIR_a039_exceptionUndefinedInstr "DIR_a039_exceptionUndefinedInstruction";
BA_ "SystemSignalLongSymbol" SG_ 949 DIR_a081_P0BFF_DIR_EM_CurrentHig "DIR_a081_P0BFF_DIR_EM_CurrentHigh";
BA_ "SystemSignalLongSymbol" SG_ 949 DIR_a083_P98B3_DIR_ECU_DemoWindo "DIR_a083_P98B3_DIR_ECU_DemoWindow";
BA_ "SystemSignalLongSymbol" SG_ 965 DIR_a178_spindownLearningBrakeAl "DIR_a178_spindownLearningBrakeAllowed";
BA_ "SystemSignalLongSymbol" SG_ 997 DIR_a249_highStatorTempFromResis "DIR_a249_highStatorTempFromResist";
BA_ "SystemSignalLongSymbol" SG_ 871 DI_a026_parkPressedWithHighAPeda "DI_a026_parkPressedWithHighAPedal";
BA_ "SystemSignalLongSymbol" SG_ 871 DI_a036_sysStandbyUnitLimitedWai "DI_a036_sysStandbyUnitLimitedWait";
BA_ "SystemSignalLongSymbol" SG_ 871 DI_a039_exceptionUndefinedInstru "DI_a039_exceptionUndefinedInstruction";
BA_ "SystemSignalLongSymbol" SG_ 871 DI_a049_P0632_DI_ECU_OdometerNot "DI_a049_P0632_DI_ECU_OdometerNotProgrammed";
BA_ "SystemSignalLongSymbol" SG_ 872 DI_a068_secondaryWheelSpeedIrrat "DI_a068_secondaryWheelSpeedIrrational";
BA_ "SystemSignalLongSymbol" SG_ 872 DI_a118_diImmobilizedForFactoryF "DI_a118_diImmobilizedForFactoryFailsafe";
BA_ "SystemSignalLongSymbol" SG_ 872 DI_a119_latentFaultCheckFailedOn "DI_a119_latentFaultCheckFailedOnce";
BA_ "SystemSignalLongSymbol" SG_ 872 DI_a121_qualifiedBrakeEventMitig "DI_a121_qualifiedBrakeEventMitigation";
BA_ "SystemSignalLongSymbol" SG_ 875 DI_a179_steeringAngleOffsetWarni "DI_a179_steeringAngleOffsetWarning";
BA_ "SystemSignalLongSymbol" SG_ 875 DI_a188_tireRotationRecommendedG "DI_a188_tireRotationRecommendedGhosted";
BA_ "SystemSignalLongSymbol" SG_ 878 DI_a200_vdcModelBasedPlausibilit "DI_a200_vdcModelBasedPlausibility";
BA_ "SystemSignalLongSymbol" SG_ 878 DI_a232_velocityEstimatorDegrade "DI_a232_velocityEstimatorDegraded";
BA_ "SystemSignalLongSymbol" SG_ 878 DI_a238_secondaryCollisionMitiga "DI_a238_secondaryCollisionMitigationActive";
BA_ "SystemSignalLongSymbol" SG_ 878 DI_a248_vdcPreControlHighDynamic "DI_a248_vdcPreControlHighDynamicActive";
BA_ "SystemSignalLongSymbol" SG_ 878 DI_a249_spinDownLearningInProgre "DI_a249_spinDownLearningInProgress";
VAL_ 1360 ADSP_alertID 76 "w076_activeSafetyChannelUnderrun" 75 "w075_tdspArmError" 74 "w074_tdspArmXrun" 73 "w073_romFLError" 72 "w072_turnSignalChannelUnderrun" 71 "w071_versionMismatch" 70 "w070_baseamp3Fault" 69 "w069_baseamp2Fault" 68 "w068_baseamp1Fault" 67 "w067_baseamp0Fault" 66 "w066_rearPwsFault" 65 "w065_tcuGpioExpanderCriticalError" 61 "w061_tcuGpioServiceError" 60 "w060_baseamp3SmFault" 59 "w059_nvmmError" 58 "w058_hfpMathExcept2INF" 57 "w057_hfpMathExcept2NAN" 56 "w056_hfpMathExcept1INF" 55 "w055_hfpMathExcept1NAN" 54 "w054_canethRxError" 53 "w053_audioSystemUnavailable" 52 "w052_criticalReset" 51 "w051_extspkFailure" 50 "w050_extSpkFault" 49 "w049_sae" 48 "w048_eCallSelfTestFailed" 47 "w047_sharc1AweFrameOverload" 46 "w046_sharc0AweFrameOverload" 45 "w045_ancEnableFail" 44 "w044_canethChecksum" 43 "w043_aweControlError" 42 "w042_twiReadError" 41 "w041_twiWriteError" 40 "w040_socSciHeartbeat" 39 "w039_ancPing" 38 "w038_a2bbIdleFailed" 37 "w037_a2baIdleFailed" 36 "w036_a2bbFault" 35 "w035_a2baFault" 34 "w034_a2bbDiscoveryFailed" 33 "w033_a2baDiscoveryFailed" 32 "w032_baseamp2SmFault" 31 "w031_baseamp1SmFault" 30 "w030_ethSysErr" 29 "w029_baseamp0SmFault" 28 "w028_ethTcpErr" 27 "w027_ethUdpErr" 26 "w026_ethIcmpErr" 25 "w025_ethIpErr" 24 "w024_ethIpfragErr" 23 "w023_ethEtharpErr" 22 "w022_emacErr" 21 "w021_usbTxAborted" 20 "w020_usbTxFailed" 19 "w019_usbTxUnderrun" 18 "w018_usbTxOverrun" 17 "w017_usbRxUnderrun" 16 "w016_usbRxOverrun" 15 "w015_eavbUnderrun" 14 "w014_eavbOverrun" 13 "w013_sharc1HighCpuUsage" 12 "w012_sharc0HighCpuUsage" 11 "w011_armHighCpuUsage" 10 "w010_12vAudioFiltLow" 8 "w008_internalTempHigh" 7 "w007_ethLinkErr" 6 "w006_eavbSeqno" 5 "w005_stackOverflow" 4 "w004_malloc" 3 "w003_assert" 2 "w002_exception" 1 "w001_flashInit" 0 "ALERT_DO_NOT_USE_ZERO" ;
VAL_ 1360 ADSP_alertState 1 "SET" 0 "CLEARED" ;
VAL_ 1360 ADSP_a035_a2baIntrType 255 "MSTR_RUNNING" 254 "STANDBY_DONE" 253 "SLAVE_INTTYPE_ERR" 252 "STRTUP_ERR_RTF" 251 "NONE" 128 "IRPT_MSG_ERR" 51 "MBOX1_EMPTY" 50 "MBOX1_FULL" 49 "MBOX0_EMPTY" 48 "MBOX0_FULL" 42 "PWRERR_NON_LOCALIZED_SHORT_VBAT" 41 "PWRERR_NON_LOCALIZED_SHORT_GND" 26 "ICRCERR" 25 "I2CERR" 24 "DSCDONE" 23 "IO7PND" 22 "IO6PND" 21 "IO5PND" 20 "IO4PND" 19 "IO3PND" 18 "IO2PND" 17 "IO1PND" 16 "IO0PND" 15 "PWRERR_INDETERMINATE_FAULT" 13 "PWRERR_CABLE_REVERSE_CONNECTED" 12 "PWRERR_CABLE_DISCONNECTED_OR_OPEN_CIRCUIT" 11 "PWRERR_CABLE_SHORTED_TOGETHER" 10 "PWRERR_CABLE_SHORTED_VBAT" 9 "PWRERR_CABLE_SHORTED_GND" 5 "SRFERR" 4 "BIT_ERR_COUNT_OVERFLOW" 3 "DATA_PARITY_ERR" 2 "CRC_ERR" 1 "DATA_DECODING_ERR" 0 "HEADER_COUNT_ERR" ;
VAL_ 1360 ADSP_a035_a2baFaultType 44 "UNKNOWN" 43 "END" 42 "A2B_NOT_LAST_NODE" 41 "A2B_BAD_NODE" 40 "A2B_BUS_REVERSE_CONNECTED" 39 "A2B_BUS_DISCONNECT_OR_OPEN_CIRCUIT" 38 "A2B_BUS_SHORT_TO_VBAT" 37 "A2B_BUS_SHORT_TO_GROUND" 36 "A2B_BUS_NO_FAULT" 35 "A2B_BUS_UNKNOWN_FAULT" 34 "A2B_BUS_INDETERMINATE_FAULT" 33 "A2B_BUS_REVERSED_OR_WRONG_PORT" 32 "A2B_BUS_REVERSED_OR_OPEN" 31 "A2B_BUS_OPEN_OR_WRONG_PORT" 30 "A2B_BUS_SHORT_TOGETHER" 29 "A2B_BUS_NEG_SHORT_TO_VBAT" 28 "A2B_BUS_POS_SHORT_TO_GROUND" 27 "A2B_MEMORY_ERROR" 26 "A2B_I2C_READ_ERROR" 25 "A2B_I2C_WRITE_ERROR" 24 "UNSUPPORTED_PROTOCOL" 23 "UNSUPPORTED_ADDR_BYTES" 22 "UNSUPPORTED_DATA_WIDTH" 21 "UNSUPPORTED_READ_LENGTH" 20 "UNSUPPORTED_INIT_FILE" 19 "CORRUPT_INIT_FILE" 18 "ODD_I2C_ADDRESS_ERROR" 17 "BUS_TIMEOUT" 16 "BUS_ERROR" 15 "CFG_ERROR" 14 "ERROR" 13 "SUCCESS" 12 "STRTUP_ERR_RTF" 11 "BECOVF" 10 "PWRERR_NLS_VBAT" 9 "PWRERR_NLS_GND" 8 "PWRERR_FAULT" 7 "PWRERR_CREV" 6 "PWRERR_CDISC" 5 "PWRERR_CS" 4 "PWRERR_CS_VBAT" 3 "PWRERR_CS_GND" 2 "DISCOVERY_DIAG_TIMEOUT" 1 "BUS_OK" 0 "EMPTY" ;
VAL_ 1360 ADSP_a036_a2bbIntrType 255 "MSTR_RUNNING" 254 "STANDBY_DONE" 253 "SLAVE_INTTYPE_ERR" 252 "STRTUP_ERR_RTF" 251 "NONE" 128 "IRPT_MSG_ERR" 51 "MBOX1_EMPTY" 50 "MBOX1_FULL" 49 "MBOX0_EMPTY" 48 "MBOX0_FULL" 42 "PWRERR_NON_LOCALIZED_SHORT_VBAT" 41 "PWRERR_NON_LOCALIZED_SHORT_GND" 26 "ICRCERR" 25 "I2CERR" 24 "DSCDONE" 23 "IO7PND" 22 "IO6PND" 21 "IO5PND" 20 "IO4PND" 19 "IO3PND" 18 "IO2PND" 17 "IO1PND" 16 "IO0PND" 15 "PWRERR_INDETERMINATE_FAULT" 13 "PWRERR_CABLE_REVERSE_CONNECTED" 12 "PWRERR_CABLE_DISCONNECTED_OR_OPEN_CIRCUIT" 11 "PWRERR_CABLE_SHORTED_TOGETHER" 10 "PWRERR_CABLE_SHORTED_VBAT" 9 "PWRERR_CABLE_SHORTED_GND" 5 "SRFERR" 4 "BIT_ERR_COUNT_OVERFLOW" 3 "DATA_PARITY_ERR" 2 "CRC_ERR" 1 "DATA_DECODING_ERR" 0 "HEADER_COUNT_ERR" ;
VAL_ 1360 ADSP_a036_a2bbFaultType 44 "UNKNOWN" 43 "END" 42 "A2B_NOT_LAST_NODE" 41 "A2B_BAD_NODE" 40 "A2B_BUS_REVERSE_CONNECTED" 39 "A2B_BUS_DISCONNECT_OR_OPEN_CIRCUIT" 38 "A2B_BUS_SHORT_TO_VBAT" 37 "A2B_BUS_SHORT_TO_GROUND" 36 "A2B_BUS_NO_FAULT" 35 "A2B_BUS_UNKNOWN_FAULT" 34 "A2B_BUS_INDETERMINATE_FAULT" 33 "A2B_BUS_REVERSED_OR_WRONG_PORT" 32 "A2B_BUS_REVERSED_OR_OPEN" 31 "A2B_BUS_OPEN_OR_WRONG_PORT" 30 "A2B_BUS_SHORT_TOGETHER" 29 "A2B_BUS_NEG_SHORT_TO_VBAT" 28 "A2B_BUS_POS_SHORT_TO_GROUND" 27 "A2B_MEMORY_ERROR" 26 "A2B_I2C_READ_ERROR" 25 "A2B_I2C_WRITE_ERROR" 24 "UNSUPPORTED_PROTOCOL" 23 "UNSUPPORTED_ADDR_BYTES" 22 "UNSUPPORTED_DATA_WIDTH" 21 "UNSUPPORTED_READ_LENGTH" 20 "UNSUPPORTED_INIT_FILE" 19 "CORRUPT_INIT_FILE" 18 "ODD_I2C_ADDRESS_ERROR" 17 "BUS_TIMEOUT" 16 "BUS_ERROR" 15 "CFG_ERROR" 14 "ERROR" 13 "SUCCESS" 12 "STRTUP_ERR_RTF" 11 "BECOVF" 10 "PWRERR_NLS_VBAT" 9 "PWRERR_NLS_GND" 8 "PWRERR_FAULT" 7 "PWRERR_CREV" 6 "PWRERR_CDISC" 5 "PWRERR_CS" 4 "PWRERR_CS_VBAT" 3 "PWRERR_CS_GND" 2 "DISCOVERY_DIAG_TIMEOUT" 1 "BUS_OK" 0 "EMPTY" ;
VAL_ 1360 ADSP_a053_audioSystemUnavailable 4 "CHIME_SYSTEM_FAULT" 3 "EXTERNAL_SPEAKER_CONNECTION_FAULT" 2 "EXTERNAL_SPEAKER_BASEAMP_NOT_AVAILABLE" 1 "EXTERNAL_SPEAKER_BASEAMP_FAULT" 0 "NONE" ;
VAL_ 1360 ADSP_a067_baseamp0Fault 7 "OTHER" 6 "DC" 5 "UNDER_VOLTAGE" 4 "OVER_VOLTAGE" 3 "OVER_CURRENT" 2 "CLOCK_PLL" 1 "OVER_TEMP" 0 "NONE" ;
VAL_ 1360 ADSP_a068_baseamp1Fault 7 "OTHER" 6 "DC" 5 "UNDER_VOLTAGE" 4 "OVER_VOLTAGE" 3 "OVER_CURRENT" 2 "CLOCK_PLL" 1 "OVER_TEMP" 0 "NONE" ;
VAL_ 1360 ADSP_a069_baseamp2Fault 7 "OTHER" 6 "DC" 5 "UNDER_VOLTAGE" 4 "OVER_VOLTAGE" 3 "OVER_CURRENT" 2 "CLOCK_PLL" 1 "OVER_TEMP" 0 "NONE" ;
VAL_ 1360 ADSP_a070_baseamp3Fault 7 "OTHER" 6 "DC" 5 "UNDER_VOLTAGE" 4 "OVER_VOLTAGE" 3 "OVER_CURRENT" 2 "CLOCK_PLL" 1 "OVER_TEMP" 0 "NONE" ;
VAL_ 1360 ADSP_a071_versionMismatch 1 "MISMATCH" 0 "MATCH" ;
VAL_ 992 APSB_A_lowPowerRequest 5 "APS_LOW_POWER_COLD_RESET" 4 "APS_LOW_POWER_SOC_WARM_RESET" 3 "APS_LOW_POWER_AP_WARM_RESET" 2 "APS_LOW_POWER_OFF" 1 "APS_LOW_POWER_SUSPEND" 0 "APS_LOW_POWER_NONE" ;
VAL_ 992 APSB_A_lowPowerRequestor 10 "APS_LOW_POWER_REQ_COUNT" 9 "APS_LOW_POWER_REQ_SGK_PGOOD_IRQ" 8 "APS_LOW_POWER_REQ_SGK_CONSOLE" 7 "APS_LOW_POWER_REQ_SGK_SLEEP" 6 "APS_LOW_POWER_REQ_SGK_UDS" 5 "APS_LOW_POWER_REQ_SGK_BRIDGE" 4 "APS_LOW_POWER_REQ_SGK_FM" 3 "APS_LOW_POWER_REQ_SGK_POWER" 2 "APS_LOW_POWER_REQ_AP_MAILBOX" 1 "APS_LOW_POWER_REQ_AP_ATF" 0 "APS_LOW_POWER_REQ_NONE" ;
VAL_ 992 APSB_B_lowPowerRequest 5 "APS_LOW_POWER_COLD_RESET" 4 "APS_LOW_POWER_SOC_WARM_RESET" 3 "APS_LOW_POWER_AP_WARM_RESET" 2 "APS_LOW_POWER_OFF" 1 "APS_LOW_POWER_SUSPEND" 0 "APS_LOW_POWER_NONE" ;
VAL_ 992 APSB_B_lowPowerRequestor 10 "APS_LOW_POWER_REQ_COUNT" 9 "APS_LOW_POWER_REQ_SGK_PGOOD_IRQ" 8 "APS_LOW_POWER_REQ_SGK_CONSOLE" 7 "APS_LOW_POWER_REQ_SGK_SLEEP" 6 "APS_LOW_POWER_REQ_SGK_UDS" 5 "APS_LOW_POWER_REQ_SGK_BRIDGE" 4 "APS_LOW_POWER_REQ_SGK_FM" 3 "APS_LOW_POWER_REQ_SGK_POWER" 2 "APS_LOW_POWER_REQ_AP_MAILBOX" 1 "APS_LOW_POWER_REQ_AP_ATF" 0 "APS_LOW_POWER_REQ_NONE" ;
VAL_ 1864 APSB_primaryTurbo 2 "TURBO_UNKNOWN" 1 "TURBO_B" 0 "TURBO_A" ;
VAL_ 1864 APSB_A_arbState 7 "ARB_STATE_COUNT" 6 "ARB_STATE_UNKNOWN" 5 "ARB_STATE_MIA" 4 "ARB_STATE_FAULT" 3 "ARB_STATE_SECONDARY" 2 "ARB_STATE_PRIMARY" 1 "ARB_STATE_IDLE" 0 "ARB_STATE_INIT" ;
VAL_ 1864 APSB_A_powerState 28 "POWER_STATE_AP_FORCE_POWER_OFF" 27 "POWER_STATE_AP_WAIT_FOR_SHUTDOWN_ABORT" 26 "POWER_STATE_AP_IN_LINUX" 25 "POWER_STATE_AP_IDLE" 24 "POWER_STATE_VEH_BOOTING" 23 "POWER_STATE_UNKNOWN" 22 "POWER_STATE_MIA" 21 "POWER_STATE_FAULT" 20 "POWER_STATE_SOC_OFF_ABORT" 19 "POWER_STATE_SOC_OFF" 18 "POWER_STATE_SOC_OFF_READY" 17 "POWER_STATE_AP_SUSPENDED" 16 "POWER_STATE_AP_OFF_ABORT_WAIT_FOR_ACK" 15 "POWER_STATE_AP_OFF_ABORT" 14 "POWER_STATE_AP_OFF_READY_WAIT_FOR_RESPONSE" 13 "POWER_STATE_AP_OFF_READY_WAIT_FOR_ACK" 12 "POWER_STATE_AP_OFF_READY" 11 "POWER_STATE_AP_OFF_PREPARE" 10 "POWER_STATE_AP_WAIT_FOR_SHUTDOWN" 9 "POWER_STATE_AP_ON" 8 "POWER_STATE_AP_IN_COREBOOT" 7 "POWER_STATE_AP_BOOTING" 6 "POWER_STATE_AP_ON_READY_WAIT_FOR_RESPONSE" 5 "POWER_STATE_AP_ON_READY_WAIT_FOR_ACK" 4 "POWER_STATE_AP_ON_READY" 3 "POWER_STATE_AP_ON_PREPARE_WAIT_FOR_RESPONSE" 2 "POWER_STATE_AP_ON_PREPARE_WAIT_FOR_ACK" 1 "POWER_STATE_AP_ON_PREPARE" 0 "POWER_STATE_IDLE" ;
VAL_ 1864 APSB_A_sleepState 9 "SLEEP_STATE_COUNT" 8 "SLEEP_STATE_UNKNOWN" 7 "SLEEP_STATE_MIA" 6 "SLEEP_STATE_FAULT" 5 "SLEEP_STATE_ABORT" 4 "SLEEP_STATE_SLEEPING" 3 "SLEEP_STATE_GOING_TO_SLEEP" 2 "SLEEP_STATE_READY" 1 "SLEEP_STATE_WAIT_FOR_BUS_SILENCE" 0 "SLEEP_STATE_IDLE" ;
VAL_ 1864 APSB_A_resetState 5 "RESET_STATE_COUNT" 4 "RESET_STATE_UNKNOWN" 3 "RESET_STATE_MIA" 2 "RESET_STATE_FAULT" 1 "RESET_STATE_RESETTING" 0 "RESET_STATE_NOT_RESETTING" ;
VAL_ 1864 APSB_A_faultState 27 "FAULT_STATE_COUNT" 26 "FAULT_STATE_UNKNOWN" 25 "FAULT_STATE_MIA" 24 "FAULT_STATE_UNEXPECTED" 23 "FAULT_STATE_SCS" 22 "FAULT_STATE_SOFTWARE_FAULT" 21 "FAULT_STATE_TRIP1_FAULT" 20 "FAULT_STATE_TRIP0_FAULT" 19 "FAULT_STATE_WDT" 18 "FAULT_STATE_CPU_FAULT" 17 "FAULT_STATE_DROOP_TRIP" 16 "FAULT_STATE_DROOP_GPU" 15 "FAULT_STATE_DROOP_CPUCL2" 14 "FAULT_STATE_DROOP_CPUCL1" 13 "FAULT_STATE_DROOP_CPUCL0" 12 "FAULT_STATE_MIF_ECC_AP" 11 "FAULT_STATE_MIF7_DFI_ALERT" 10 "FAULT_STATE_MIF6_DFI_ALERT" 9 "FAULT_STATE_MIF5_DFI_ALERT" 8 "FAULT_STATE_MIF4_DFI_ALERT" 7 "FAULT_STATE_MIF3_DFI_ALERT" 6 "FAULT_STATE_MIF2_DFI_ALERT" 5 "FAULT_STATE_MIF1_DFI_ALERT" 4 "FAULT_STATE_MIF0_DFI_ALERT" 3 "FAULT_STATE_MIF_ECC_UNCORRECTED" 2 "FAULT_STATE_MIF_ECC_CORRECTED" 1 "FAULT_STATE_GIC" 0 "FAULT_STATE_NONE" ;
VAL_ 1864 APSB_secondaryTurbo 2 "TURBO_UNKNOWN" 1 "TURBO_B" 0 "TURBO_A" ;
VAL_ 1864 APSB_B_arbState 7 "ARB_STATE_COUNT" 6 "ARB_STATE_UNKNOWN" 5 "ARB_STATE_MIA" 4 "ARB_STATE_FAULT" 3 "ARB_STATE_SECONDARY" 2 "ARB_STATE_PRIMARY" 1 "ARB_STATE_IDLE" 0 "ARB_STATE_INIT" ;
VAL_ 1864 APSB_B_powerState 28 "POWER_STATE_AP_FORCE_POWER_OFF" 27 "POWER_STATE_AP_WAIT_FOR_SHUTDOWN_ABORT" 26 "POWER_STATE_AP_IN_LINUX" 25 "POWER_STATE_AP_IDLE" 24 "POWER_STATE_VEH_BOOTING" 23 "POWER_STATE_UNKNOWN" 22 "POWER_STATE_MIA" 21 "POWER_STATE_FAULT" 20 "POWER_STATE_SOC_OFF_ABORT" 19 "POWER_STATE_SOC_OFF" 18 "POWER_STATE_SOC_OFF_READY" 17 "POWER_STATE_AP_SUSPENDED" 16 "POWER_STATE_AP_OFF_ABORT_WAIT_FOR_ACK" 15 "POWER_STATE_AP_OFF_ABORT" 14 "POWER_STATE_AP_OFF_READY_WAIT_FOR_RESPONSE" 13 "POWER_STATE_AP_OFF_READY_WAIT_FOR_ACK" 12 "POWER_STATE_AP_OFF_READY" 11 "POWER_STATE_AP_OFF_PREPARE" 10 "POWER_STATE_AP_WAIT_FOR_SHUTDOWN" 9 "POWER_STATE_AP_ON" 8 "POWER_STATE_AP_IN_COREBOOT" 7 "POWER_STATE_AP_BOOTING" 6 "POWER_STATE_AP_ON_READY_WAIT_FOR_RESPONSE" 5 "POWER_STATE_AP_ON_READY_WAIT_FOR_ACK" 4 "POWER_STATE_AP_ON_READY" 3 "POWER_STATE_AP_ON_PREPARE_WAIT_FOR_RESPONSE" 2 "POWER_STATE_AP_ON_PREPARE_WAIT_FOR_ACK" 1 "POWER_STATE_AP_ON_PREPARE" 0 "POWER_STATE_IDLE" ;
VAL_ 1864 APSB_B_sleepState 9 "SLEEP_STATE_COUNT" 8 "SLEEP_STATE_UNKNOWN" 7 "SLEEP_STATE_MIA" 6 "SLEEP_STATE_FAULT" 5 "SLEEP_STATE_ABORT" 4 "SLEEP_STATE_SLEEPING" 3 "SLEEP_STATE_GOING_TO_SLEEP" 2 "SLEEP_STATE_READY" 1 "SLEEP_STATE_WAIT_FOR_BUS_SILENCE" 0 "SLEEP_STATE_IDLE" ;
VAL_ 1864 APSB_B_resetState 5 "RESET_STATE_COUNT" 4 "RESET_STATE_UNKNOWN" 3 "RESET_STATE_MIA" 2 "RESET_STATE_FAULT" 1 "RESET_STATE_RESETTING" 0 "RESET_STATE_NOT_RESETTING" ;
VAL_ 1864 APSB_B_faultState 27 "FAULT_STATE_COUNT" 26 "FAULT_STATE_UNKNOWN" 25 "FAULT_STATE_MIA" 24 "FAULT_STATE_UNEXPECTED" 23 "FAULT_STATE_SCS" 22 "FAULT_STATE_SOFTWARE_FAULT" 21 "FAULT_STATE_TRIP1_FAULT" 20 "FAULT_STATE_TRIP0_FAULT" 19 "FAULT_STATE_WDT" 18 "FAULT_STATE_CPU_FAULT" 17 "FAULT_STATE_DROOP_TRIP" 16 "FAULT_STATE_DROOP_GPU" 15 "FAULT_STATE_DROOP_CPUCL2" 14 "FAULT_STATE_DROOP_CPUCL1" 13 "FAULT_STATE_DROOP_CPUCL0" 12 "FAULT_STATE_MIF_ECC_AP" 11 "FAULT_STATE_MIF7_DFI_ALERT" 10 "FAULT_STATE_MIF6_DFI_ALERT" 9 "FAULT_STATE_MIF5_DFI_ALERT" 8 "FAULT_STATE_MIF4_DFI_ALERT" 7 "FAULT_STATE_MIF3_DFI_ALERT" 6 "FAULT_STATE_MIF2_DFI_ALERT" 5 "FAULT_STATE_MIF1_DFI_ALERT" 4 "FAULT_STATE_MIF0_DFI_ALERT" 3 "FAULT_STATE_MIF_ECC_UNCORRECTED" 2 "FAULT_STATE_MIF_ECC_CORRECTED" 1 "FAULT_STATE_GIC" 0 "FAULT_STATE_NONE" ;
VAL_ 971 APSB_appStatusMonitorState 7 "STATUS_MONITOR_NUM_STATES" 6 "STATUS_MONITOR_STATE_RECOVERY" 5 "STATUS_MONITOR_STATE_SHUTTING_DOWN" 4 "STATUS_MONITOR_STATE_CRITICAL" 3 "STATUS_MONITOR_STATE_NOMINAL" 2 "STATUS_MONITOR_STATE_INIT" 1 "STATUS_MONITOR_STATE_PWR_OFF" 0 "STATUS_MONITOR_STATE_UNKNOWN" ;
VAL_ 971 APSB_vehBehaviorState 8 "VEH_BEHAVIOR_NUM_STATES" 7 "VEH_BEHAVIOR_STATE_SYSTEM_FAULT" 6 "VEH_BEHAVIOR_STATE_APS_OVERRIDE" 5 "VEH_BEHAVIOR_STATE_APS_FAIL_SAFE" 4 "VEH_BEHAVIOR_STATE_APS_BRIDGE_APB" 3 "VEH_BEHAVIOR_STATE_APS_BRIDGE_APP" 2 "VEH_BEHAVIOR_STATE_APS_CONTROL" 1 "VEH_BEHAVIOR_STATE_APS_AVAILABLE" 0 "VEH_BEHAVIOR_STATE_UNKNOWN" ;
VAL_ 971 APSB_canMaster 3 "CAN_MASTER_SNA" 2 "CAN_MASTER_APB" 1 "CAN_MASTER_APP" 0 "CAN_MASTER_APS" ;
VAL_ 971 APSB_appGpioState 3 "AP_GPIO_STATE_HEALTHY" 2 "AP_GPIO_STATE_CRITICAL" 1 "AP_GPIO_STATE_DISABLED" 0 "AP_GPIO_STATE_PWR_DOWN_REBOOT" ;
VAL_ 971 APSB_eacInternalState 7 "APS_EAC_NUM_STATES" 6 "APS_EAC_STATE_LSS" 5 "APS_EAC_STATE_OVERRIDE" 4 "APS_EAC_STATE_INHIBIT" 3 "APS_EAC_STATE_AUTOPARK" 2 "APS_EAC_STATE_CONTINUOUS" 1 "APS_EAC_STATE_MOMENTARY" 0 "APS_EAC_STATE_INIT" ;
VAL_ 971 APSB_apbStatusMonitorState 7 "STATUS_MONITOR_NUM_STATES" 6 "STATUS_MONITOR_STATE_RECOVERY" 5 "STATUS_MONITOR_STATE_SHUTTING_DOWN" 4 "STATUS_MONITOR_STATE_CRITICAL" 3 "STATUS_MONITOR_STATE_NOMINAL" 2 "STATUS_MONITOR_STATE_INIT" 1 "STATUS_MONITOR_STATE_PWR_OFF" 0 "STATUS_MONITOR_STATE_UNKNOWN" ;
VAL_ 971 APSB_apbGpioState 3 "AP_GPIO_STATE_HEALTHY" 2 "AP_GPIO_STATE_CRITICAL" 1 "AP_GPIO_STATE_DISABLED" 0 "AP_GPIO_STATE_PWR_DOWN_REBOOT" ;
VAL_ 971 APSB_locLimitReason 7 "LOC_LIMITS_EXTENDED" 6 "LOC_MONITOR_UNAVAILABLE" 5 "NO_RADAR_TARGET" 4 "RADAR_NOT_HEALTHY" 3 "PRIMARY_AP_NOT_HEALTHY" 2 "ACC_AND_AEB_UNAVAILABLE" 1 "NOT_IN_DRIVE" 0 "NOMINAL_DEFAULT" ;
VAL_ 971 APSB_appPowerStateRequest 3 "AP_POWER_STATE_SLEEP" 2 "AP_POWER_STATE_SUSPEND" 1 "AP_POWER_STATE_SENTRY" 0 "AP_POWER_STATE_NOMINAL" ;
VAL_ 971 APSB_appPowerStateReason 12 "UI_SUMMON_STANDBY_MODE_ENABLED" 11 "SLEEP_REQUEST_RECVD" 10 "AP_POWER_REQUEST_OVERHEATED" 9 "LOADSHED_POWER_REQUEST_PENDING" 8 "VC_POWER_REQUEST" 7 "AP_POWER_REQUEST_OVERRIDE" 6 "AP_POWER_REQUEST_OVERHEATING" 5 "AP_POWER_REQUEST_HYSTERESIS" 4 "GTW_GOTO_FULL_POWER" 3 "AP_NOT_IN_PARK" 2 "AP_NM_REASON_SET" 1 "AP_WDOG_UNHEALTHY" 0 "UI_POWER_STATE_REQUEST" ;
VAL_ 971 APSB_apbPowerStateRequest 3 "AP_POWER_STATE_SLEEP" 2 "AP_POWER_STATE_SUSPEND" 1 "AP_POWER_STATE_SENTRY" 0 "AP_POWER_STATE_NOMINAL" ;
VAL_ 971 APSB_apbPowerStateReason 12 "UI_SUMMON_STANDBY_MODE_ENABLED" 11 "SLEEP_REQUEST_RECVD" 10 "AP_POWER_REQUEST_OVERHEATED" 9 "LOADSHED_POWER_REQUEST_PENDING" 8 "VC_POWER_REQUEST" 7 "AP_POWER_REQUEST_OVERRIDE" 6 "AP_POWER_REQUEST_OVERHEATING" 5 "AP_POWER_REQUEST_HYSTERESIS" 4 "GTW_GOTO_FULL_POWER" 3 "AP_NOT_IN_PARK" 2 "AP_NM_REASON_SET" 1 "AP_WDOG_UNHEALTHY" 0 "UI_POWER_STATE_REQUEST" ;
VAL_ 971 APSB_heaterStateDebug 7 "APS_HEATER_SNA" 4 "APS_HEATER_FAULT_SHORT" 3 "APS_HEATER_FAULT_OPEN" 2 "APS_HEATER_ON_NOT_HEATING" 1 "APS_HEATER_ON_HEATING" 0 "APS_HEATER_OFF" ;
VAL_ 971 APSB_gpsAntennaState 2 "GPS_ANTENNA_CONNECTED" 1 "GPS_ANTENNA_UNKNOWN" 0 "GPS_ANTENNA_DISCONNECTED" ;
VAL_ 971 APSB_arbState 7 "ARB_STATE_N_COUNT" 6 "ARB_STATE_N_UNKNOWN" 5 "ARB_STATE_N_MIA" 4 "ARB_STATE_N_FAULT" 3 "ARB_STATE_N_SECONDARY" 2 "ARB_STATE_N_PRIMARY" 1 "ARB_STATE_N_IDLE" 0 "ARB_STATE_N_INIT" ;
VAL_ 971 APSB_socPowerOperatingMode 2 "APS_DUAL_SOC" 1 "APS_SINGLE_SOC" 0 "APS_UNKNOWN" ;
VAL_ 943 BB_sOutputRodQF 2 "Faulty" 1 "Normal" 0 "NotInit_orOff" ;
VAL_ 943 BB_sInputRodQF 2 "Faulty" 1 "Normal" 0 "NotInit_orOff" ;
VAL_ 943 BB_driverBrakeApply 1 "DRIVER_APPLYING_BRAKES" 0 "BRAKES_NOT_APPLIED" ;
VAL_ 943 BB_driverBrakeApplyQF 2 "Faulty" 1 "Normal" 0 "NotInit_orOff" ;
VAL_ 943 BB_boosterStatus 6 "ACTUATION" 5 "READY" 4 "ACTIVE_GOOD_CHECK" 3 "DIAGNOSTIC" 2 "FAILURE" 1 "INIT" 0 "OFF" ;
VAL_ 943 BB_warningLampRequest 2 "RED_BRAKE_LAMP_REQUEST" 1 "YELLOW_BRAKE_LAMP_REQUEST" 0 "NO_LAMP_REQUEST" ;
VAL_ 943 BB_brakeFluidLevel 3 "BRAKE_FLUID_LEVEL_INVALID" 2 "BRAKE_FLUID_LEVEL_NORMAL" 1 "BRAKE_FLUID_LEVEL_LOW" 0 "BRAKE_FLUID_LEVEL_UNKNOWN" ;
VAL_ 943 BB_internalState 7 "READY_TO_SHUTDOWN" 6 "POST_DRIVE_CHECK" 5 "TRANSITION_TO_IDLE" 4 "DIAGNOSTIC" 3 "EXTERNAL_BRAKE_REQUEST" 2 "LOCAL_BRAKE_REQUEST" 1 "PRE_DRIVE_CHECK" 0 "NO_MODE_ACTIVE" ;
VAL_ 2029 BMS_10HzDebug_Id 34 "AGED_SOC_OCV" 33 "THM_TARGETS" 32 "SOC_AND_OCV" 31 "DRIVE_LIMITS" 30 "STANDBY_SUPPLY" 29 "SLEEP_WAKE" 28 "POWER_PREDICTION_3" 27 "POWER_PREDICTION_2" 26 "POWER_PREDICTION_1" 25 "ADC_FLOOD" 24 "ADC_MISC" 23 "ADC_DCLINK" 22 "ADC_CP" 21 "ADC_VREF" 20 "WAKE_TIMERS" 19 "CAC_3" 18 "CAC_2" 17 "CAC_1" 16 "HYST" 15 "PACK_VOLTAGES" 14 "THM_MODEL_DATA_11" 13 "THM_MODEL_DATA_10" 12 "THM_MODEL_DATA_9" 3 "SOC_RESTING" 2 "ISOLATION" 1 "AHR_COUNTER" 0 "STATE" ;
VAL_ 2028 BMS_cellTempTargetMode 11 "V2X_SESSION" 10 "PASSIVE_COOL_ON_NAV" 9 "ACTIVE_COOL_ON_NAV" 8 "SOH_HEAT_PACK" 7 "DRAGSTRIP" 6 "PASSIVE_HEAT_ON_NAV" 5 "ACTIVE_HEAT_ON_NAV" 4 "DISCONNECTED_PRECONDITION" 3 "CONNECTED_PRECONDITION" 2 "HIGH_POWER_CHARGE" 1 "LOW_POWER_CHARGE" 0 "DEFAULT" ;
VAL_ 1085 CP_hvChargeStatus_log 6 "CHARGE_FAULTED" 5 "CHARGE_ENABLED" 4 "EVSE_TEST_PASSED" 3 "EXT_EVSE_TEST_ACTIVE" 2 "CHARGE_STANDBY" 1 "CHARGE_CONNECTED" 0 "CHARGE_INACTIVE" ;
VAL_ 1085 CP_chargeShutdownRequest_log 2 "EMERGENCY_SHUTDOWN_REQUESTED" 1 "GRACEFUL_SHUTDOWN_REQUESTED" 0 "NO_SHUTDOWN_REQUESTED" ;
VAL_ 1085 CP_evseChargeType_log 2 "AC_CHARGER_PRESENT" 1 "DC_CHARGER_PRESENT" 0 "NO_CHARGER_PRESENT" ;
VAL_ 1085 CP_chgLimitMode_log 5 "NUM" 4 "DEBUG_OVERRIDE" 3 "ADAPTER_FOLDBACK" 2 "THERMAL_FOLDBACK" 1 "CABLE_UNSECURED" 0 "HW" ;
VAL_ 777 DAS_objectId 5 "VEHICLE_HEADINGS" 4 "ROAD_SIGN" 3 "CUTIN_VEHICLE" 2 "RIGHT_VEHICLES" 1 "LEFT_VEHICLES" 0 "LEAD_VEHICLES" ;
VAL_ 777 DAS_leadVehType 6 "IPSO" 5 "PEDESTRIAN" 4 "BICYCLE" 3 "MOTORCYCLE" 2 "CAR" 1 "TRUCK" 0 "UNKNOWN" ;
VAL_ 777 DAS_leadVehDx 255 "SNA" ;
VAL_ 777 DAS_leadVehVxRel 15 "SNA" ;
VAL_ 777 DAS_leadVehId 127 "SNA" ;
VAL_ 777 DAS_leadVeh2Type 5 "PEDESTRIAN" 4 "BICYCLE" 3 "MOTORCYCLE" 2 "CAR" 1 "TRUCK" 0 "UNKNOWN" ;
VAL_ 777 DAS_leadVeh2Dx 255 "SNA" ;
VAL_ 777 DAS_leadVeh2VxRel 15 "SNA" ;
VAL_ 777 DAS_leadVeh2Id 0 "SNA" ;
VAL_ 777 DAS_leftVehType 5 "PEDESTRIAN" 4 "BICYCLE" 3 "MOTORCYCLE" 2 "CAR" 1 "TRUCK" 0 "UNKNOWN" ;
VAL_ 777 DAS_leftVehDx 255 "SNA" ;
VAL_ 777 DAS_leftVehVxRel 15 "SNA" ;
VAL_ 777 DAS_leftVehId 127 "SNA" ;
VAL_ 777 DAS_leftVeh2Type 5 "PEDESTRIAN" 4 "BICYCLE" 3 "MOTORCYCLE" 2 "CAR" 1 "TRUCK" 0 "UNKNOWN" ;
VAL_ 777 DAS_leftVeh2Dx 255 "SNA" ;
VAL_ 777 DAS_leftVeh2VxRel 15 "SNA" ;
VAL_ 777 DAS_leftVeh2Id 0 "SNA" ;
VAL_ 777 DAS_rightVehType 5 "PEDESTRIAN" 4 "BICYCLE" 3 "MOTORCYCLE" 2 "CAR" 1 "TRUCK" 0 "UNKNOWN" ;
VAL_ 777 DAS_rightVehDx 255 "SNA" ;
VAL_ 777 DAS_rightVehVxRel 15 "SNA" ;
VAL_ 777 DAS_rightVehId 127 "SNA" ;
VAL_ 777 DAS_rightVeh2Type 5 "PEDESTRIAN" 4 "BICYCLE" 3 "MOTORCYCLE" 2 "CAR" 1 "TRUCK" 0 "UNKNOWN" ;
VAL_ 777 DAS_rightVeh2Dx 255 "SNA" ;
VAL_ 777 DAS_rightVeh2VxRel 15 "SNA" ;
VAL_ 777 DAS_rightVeh2Id 0 "SNA" ;
VAL_ 777 DAS_cutinVehType 5 "PEDESTRIAN" 4 "BICYCLE" 3 "MOTORCYCLE" 2 "CAR" 1 "TRUCK" 0 "UNKNOWN" ;
VAL_ 777 DAS_cutinVehDx 255 "SNA" ;
VAL_ 777 DAS_cutinVehVxRel 15 "SNA" ;
VAL_ 777 DAS_cutinVehId 127 "SNA" ;
VAL_ 777 DAS_roadSignColor 4 "RED_YELLOW" 3 "GREEN" 2 "YELLOW" 1 "RED" 0 "NONE" ;
VAL_ 777 DAS_roadSignId 255 "SNA" 1 "TRAFFIC_LIGHT" 0 "STOP_SIGN" ;
VAL_ 777 DAS_roadSignStopLineDist 1023 "SNA" ;
VAL_ 777 DAS_roadSignSource 2 "VISION" 1 "NAV" 0 "NONE" ;
VAL_ 777 DAS_roadSignArrow 4 "UNKNOWN" 3 "STRAIGHT" 2 "RIGHT" 1 "LEFT" 0 "CIRCLE" ;
VAL_ 777 DAS_roadSignOrientation 2 "HORIZONTAL_3_LIGHT" 1 "VERTICAL_3_LIGHT" 0 "UNKNOWN" ;
VAL_ 1548 DAS_TR_ObjIndex 31 "Mux31" 30 "Mux30" 29 "Mux29" 28 "Mux28" 27 "Mux27" 26 "Mux26" 25 "Mux25" 24 "Mux24" 23 "Mux23" 22 "Mux22" 21 "Mux21" 20 "Mux20" 19 "Mux19" 18 "Mux18" 17 "Mux17" 16 "Mux16" 15 "Mux15" 14 "Mux14" 13 "Mux13" 12 "Mux12" 11 "Mux11" 10 "Mux10" 9 "Mux9" 8 "Mux8" 7 "Mux7" 6 "Mux6" 5 "Mux5" 4 "Mux4" 3 "Mux3" 2 "Mux2" 1 "Mux1" 0 "Mux0" ;
VAL_ 1548 DAS_TR_Obj00_Class 4 "RADAR_CLASS_CONSTRUCTION_ELEMENT" 3 "RADAR_CLASS_MOVING_PEDESTRIAN" 2 "RADAR_CLASS_MOVING_TWO_WHEEL_VEHICLE" 1 "RADAR_CLASS_MOVING_FOUR_WHEEL_VEHICLE" 0 "RADAR_CLASS_UNKNOWN" ;
VAL_ 1548 DAS_TR_Obj00_MovingState 3 "RADAR_MOVESTATE_STANDING" 2 "RADAR_MOVESTATE_STOPPED" 1 "RADAR_MOVESTATE_MOVING" 0 "RADAR_MOVESTATE_INDETERMINATE" ;
